VERSION ""

NS_ :

BS_:

BU_: BSM BSM2 CADM CVADAS ECM EPS ORC CANOE EVCU2

BO_ 2654552208 Distance_Point_Map_7: 64 CVADAS
 SG_ FD14_Point_Map_Cruising_Age_63 : 482|6@1+ (1,0) [0|63] ""  CANOE
 SG_ FD14_Point_Map_Cruising_Age_62 : 418|6@1+ (1,0) [0|63] ""  CANOE
 SG_ FD14_Point_Map_Cruising_Age_61 : 354|6@1+ (1,0) [0|63] ""  CANOE
 SG_ FD14_Point_Map_Cruising_Age_60 : 290|6@1+ (1,0) [0|63] ""  CANOE
 SG_ FD14_Point_Map_Cruising_Age_59 : 226|6@1+ (1,0) [0|63] ""  CANOE
 SG_ FD14_Point_Map_Cruising_Age_58 : 162|6@1+ (1,0) [0|63] ""  CANOE
 SG_ FD14_Point_Map_Cruising_Age_57 : 98|6@1+ (1,0) [0|63] ""  CANOE
 SG_ FD14_Point_Map_Cruising_Age_56 : 34|6@1+ (1,0) [0|63] ""  CANOE
 SG_ FD14_Point_Map_Reserved_62 : 440|8@1+ (1,0) [0|255] ""  CANOE
 SG_ FD14_Point_Map_Age_62 : 432|8@1+ (1,0) [0|255] ""  CANOE
 SG_ FD14_Point_Map_Confidence_62 : 424|8@1+ (1,0) [0|255] ""  CANOE
 SG_ FD14_Point_Map_Height_62 : 416|2@1+ (1,0) [0|3] ""  CANOE
 SG_ FD14_Point_Map_Y_62 : 400|16@1- (1,0) [-32768|32767] ""  CANOE
 SG_ FD14_Point_Map_X_62 : 384|16@1- (1,0) [-32768|32767] ""  CANOE
 SG_ FD14_Point_Map_Reserved_61 : 376|8@1+ (1,0) [0|255] ""  CANOE
 SG_ FD14_Point_Map_Age_61 : 368|8@1+ (1,0) [0|255] ""  CANOE
 SG_ FD14_Point_Map_Confidence_61 : 360|8@1+ (1,0) [0|255] ""  CANOE
 SG_ FD14_Point_Map_Height_61 : 352|2@1+ (1,0) [0|3] ""  CANOE
 SG_ FD14_Point_Map_Y_61 : 336|16@1- (1,0) [-32768|32767] ""  CANOE
 SG_ FD14_Point_Map_X_61 : 320|16@1- (1,0) [-32768|32767] ""  CANOE
 SG_ FD14_Point_Map_Reserved_60 : 312|8@1+ (1,0) [0|255] ""  CANOE
 SG_ FD14_Point_Map_Confidence_60 : 296|8@1+ (1,0) [0|255] ""  CANOE
 SG_ FD14_Point_Map_Height_60 : 288|2@1+ (1,0) [0|3] ""  CANOE
 SG_ FD14_Point_Map_Age_60 : 304|8@1+ (1,0) [0|255] ""  CANOE
 SG_ FD14_Point_Map_Y_60 : 272|16@1- (1,0) [-32768|32767] ""  CANOE
 SG_ FD14_Point_Map_X_60 : 256|16@1- (1,0) [-32768|32767] ""  CANOE
 SG_ FD14_Point_Map_Reserved_59 : 248|8@1+ (1,0) [0|255] ""  CANOE
 SG_ FD14_Point_Map_Age_59 : 240|8@1+ (1,0) [0|255] ""  CANOE
 SG_ FD14_Point_Map_Confidence_59 : 232|8@1+ (1,0) [0|255] ""  CANOE
 SG_ FD14_Point_Map_Height_59 : 224|2@1+ (1,0) [0|3] ""  CANOE
 SG_ FD14_Point_Map_Y_59 : 208|16@1- (1,0) [-32768|32767] ""  CANOE
 SG_ FD14_Point_Map_X_59 : 192|16@1- (1,0) [-32768|32767] ""  CANOE
 SG_ FD14_Point_Map_Reserved_58 : 184|8@1+ (1,0) [0|255] ""  CANOE
 SG_ FD14_Point_Map_Age_58 : 176|8@1+ (1,0) [0|255] ""  CANOE
 SG_ FD14_Point_Map_Confidence_58 : 168|8@1+ (1,0) [0|255] ""  CANOE
 SG_ FD14_Point_Map_Height_58 : 160|2@1+ (1,0) [0|3] ""  CANOE
 SG_ FD14_Point_Map_Y_58 : 144|16@1- (1,0) [-32768|32767] ""  CANOE
 SG_ FD14_Point_Map_X_58 : 128|16@1- (1,0) [-32768|32767] ""  CANOE
 SG_ FD14_Point_Map_Reserved_57 : 120|8@1+ (1,0) [0|255] ""  CANOE
 SG_ FD14_Point_Map_Age_57 : 112|8@1+ (1,0) [0|255] ""  CANOE
 SG_ FD14_Point_Map_Confidence_57 : 104|8@1+ (1,0) [0|255] ""  CANOE
 SG_ FD14_Point_Map_Height_57 : 96|2@1+ (1,0) [0|3] ""  CANOE
 SG_ FD14_Point_Map_Y_57 : 80|16@1- (1,0) [-32768|32767] ""  CANOE
 SG_ FD14_Point_Map_X_57 : 64|16@1- (1,0) [-32768|32767] ""  CANOE
 SG_ FD14_Point_Map_Reserved_56 : 56|8@1+ (1,0) [0|255] ""  CANOE
 SG_ FD14_Point_Map_Age_56 : 48|8@1+ (1,0) [0|255] ""  CANOE
 SG_ FD14_Point_Map_Confidence_56 : 40|8@1+ (1,0) [0|255] ""  CANOE
 SG_ FD14_Point_Map_Height_56 : 32|2@1+ (1,0) [0|3] ""  CANOE
 SG_ FD14_Point_Map_Y_56 : 16|16@1- (1,0) [-32768|32767] ""  CANOE
 SG_ FD14_Point_Map_X_56 : 0|16@1- (1,0) [-32768|32767] ""  CANOE
 SG_ FD14_Point_Map_Reserved_63 : 504|8@1+ (1,0) [0|255] ""  CANOE
 SG_ FD14_Point_Map_Age_63 : 496|8@1+ (1,0) [0|255] ""  CANOE
 SG_ FD14_Point_Map_Confidence_63 : 488|8@1+ (1,0) [0|255] ""  CANOE
 SG_ FD14_Point_Map_Height_63 : 480|2@1+ (1,0) [0|3] ""  CANOE
 SG_ FD14_Point_Map_Y_63 : 464|16@1- (1,0) [-32768|32767] ""  CANOE
 SG_ FD14_Point_Map_X_63 : 448|16@1- (1,0) [-32768|32767] ""  CANOE

BO_ 2654552209 Distance_Point_Map_8: 64 CVADAS
 SG_ FD14_Point_Map_Cruising_Age_71 : 498|6@1+ (1,0) [0|63] ""  CANOE
 SG_ FD14_Point_Map_Cruising_Age_70 : 418|6@1+ (1,0) [0|63] ""  CANOE
 SG_ FD14_Point_Map_Cruising_Age_69 : 354|6@1+ (1,0) [0|63] ""  CANOE
 SG_ FD14_Point_Map_Cruising_Age_68 : 290|6@1+ (1,0) [0|63] ""  CANOE
 SG_ FD14_Point_Map_Cruising_Age_67 : 226|6@1+ (1,0) [0|63] ""  CANOE
 SG_ FD14_Point_Map_Cruising_Age_66 : 162|6@1+ (1,0) [0|63] ""  CANOE
 SG_ FD14_Point_Map_Cruising_Age_65 : 98|6@1+ (1,0) [0|63] ""  CANOE
 SG_ FD14_Point_Map_Cruising_Age_64 : 34|6@1+ (1,0) [0|63] ""  CANOE
 SG_ FD14_Point_Map_Reserved_71 : 504|8@1+ (1,0) [0|255] ""  CANOE
 SG_ FD14_Point_Map_Height_71 : 496|2@1+ (1,0) [0|3] ""  CANOE
 SG_ FD14_Point_Map_Age_71 : 488|8@1+ (1,0) [0|255] ""  CANOE
 SG_ FD14_Point_Map_Confidence_71 : 480|8@1+ (1,0) [0|255] ""  CANOE
 SG_ FD14_Point_Map_Y_71 : 464|16@1- (1,0) [-32768|32767] ""  CANOE
 SG_ FD14_Point_Map_X_71 : 448|16@1- (1,0) [-32768|32767] ""  CANOE
 SG_ FD14_Point_Map_Reserved_70 : 440|8@1+ (1,0) [0|255] ""  CANOE
 SG_ FD14_Point_Map_Age_70 : 432|8@1+ (1,0) [0|255] ""  CANOE
 SG_ FD14_Point_Map_Confidence_70 : 424|8@1+ (1,0) [0|255] ""  CANOE
 SG_ FD14_Point_Map_Height_70 : 416|2@1+ (1,0) [0|3] ""  CANOE
 SG_ FD14_Point_Map_Y_70 : 400|16@1- (1,0) [-32768|32767] ""  CANOE
 SG_ FD14_Point_Map_X_70 : 384|16@1- (1,0) [-32768|32767] ""  CANOE
 SG_ FD14_Point_Map_Reserved_69 : 376|8@1+ (1,0) [0|255] ""  CANOE
 SG_ FD14_Point_Map_Age_69 : 368|8@1+ (1,0) [0|255] ""  CANOE
 SG_ FD14_Point_Map_Confidence_69 : 360|8@1+ (1,0) [0|255] ""  CANOE
 SG_ FD14_Point_Map_Height_69 : 352|2@1+ (1,0) [0|3] ""  CANOE
 SG_ FD14_Point_Map_Y_69 : 336|16@1- (1,0) [-32768|32767] ""  CANOE
 SG_ FD14_Point_Map_X_69 : 320|16@1- (1,0) [-32768|32767] ""  CANOE
 SG_ FD14_Point_Map_Reserved_68 : 312|8@1+ (1,0) [0|255] ""  CANOE
 SG_ FD14_Point_Map_Age_68 : 304|8@1+ (1,0) [0|255] ""  CANOE
 SG_ FD14_Point_Map_Confidence_68 : 296|8@1+ (1,0) [0|255] ""  CANOE
 SG_ FD14_Point_Map_Height_68 : 288|2@1+ (1,0) [0|3] ""  CANOE
 SG_ FD14_Point_Map_Y_68 : 272|16@1- (1,0) [-32768|32767] ""  CANOE
 SG_ FD14_Point_Map_X_68 : 256|16@1- (1,0) [-32768|32767] ""  CANOE
 SG_ FD14_Point_Map_Reserved_67 : 248|8@1+ (1,0) [0|255] ""  CANOE
 SG_ FD14_Point_Map_Age_67 : 240|8@1+ (1,0) [0|255] ""  CANOE
 SG_ FD14_Point_Map_Confidence_67 : 232|8@1+ (1,0) [0|255] ""  CANOE
 SG_ FD14_Point_Map_Height_67 : 224|2@1+ (1,0) [0|3] ""  CANOE
 SG_ FD14_Point_Map_Y_67 : 208|16@1- (1,0) [-32768|32767] ""  CANOE
 SG_ FD14_Point_Map_X_67 : 192|16@1- (1,0) [-32768|32767] ""  CANOE
 SG_ FD14_Point_Map_Reserved_66 : 184|8@1+ (1,0) [0|255] ""  CANOE
 SG_ FD14_Point_Map_Age_66 : 176|8@1+ (1,0) [0|255] ""  CANOE
 SG_ FD14_Point_Map_Confidence_66 : 168|8@1+ (1,0) [0|255] ""  CANOE
 SG_ FD14_Point_Map_Height_66 : 160|2@1+ (1,0) [0|3] ""  CANOE
 SG_ FD14_Point_Map_Y_66 : 144|16@1- (1,0) [-32768|32767] ""  CANOE
 SG_ FD14_Point_Map_X_66 : 128|16@1- (1,0) [-32768|32767] ""  CANOE
 SG_ FD14_Point_Map_Reserved_65 : 120|8@1+ (1,0) [0|255] ""  CANOE
 SG_ FD14_Point_Map_Age_65 : 112|8@1+ (1,0) [0|255] ""  CANOE
 SG_ FD14_Point_Map_Confidence_65 : 104|8@1+ (1,0) [0|255] ""  CANOE
 SG_ FD14_Point_Map_Height_65 : 96|2@1+ (1,0) [0|3] ""  CANOE
 SG_ FD14_Point_Map_Y_65 : 80|16@1- (1,0) [-32768|32767] ""  CANOE
 SG_ FD14_Point_Map_X_65 : 64|16@1- (1,0) [-32768|32767] ""  CANOE
 SG_ FD14_Point_Map_Reserved_64 : 56|8@1+ (1,0) [0|255] ""  CANOE
 SG_ FD14_Point_Map_Age_64 : 48|8@1+ (1,0) [0|255] ""  CANOE
 SG_ FD14_Point_Map_Confidence_64 : 40|8@1+ (1,0) [0|255] ""  CANOE
 SG_ FD14_Point_Map_Height_64 : 32|2@1+ (1,0) [0|3] ""  CANOE
 SG_ FD14_Point_Map_Y_64 : 16|16@1- (1,0) [-32768|32767] ""  CANOE
 SG_ FD14_Point_Map_X_64 : 0|16@1- (1,0) [-32768|32767] ""  CANOE

BO_ 2654552210 Distance_Point_Map_9: 64 CVADAS
 SG_ FD14_Point_Map_Cruising_Age_79 : 482|6@1+ (1,0) [0|63] ""  CANOE
 SG_ FD14_Point_Map_Cruising_Age_78 : 418|6@1+ (1,0) [0|63] ""  CANOE
 SG_ FD14_Point_Map_Cruising_Age_77 : 354|6@1+ (1,0) [0|63] ""  CANOE
 SG_ FD14_Point_Map_Cruising_Age_76 : 290|6@1+ (1,0) [0|63] ""  CANOE
 SG_ FD14_Point_Map_Cruising_Age_75 : 226|6@1+ (1,0) [0|63] ""  CANOE
 SG_ FD14_Point_Map_Cruising_Age_74 : 162|6@1+ (1,0) [0|63] ""  CANOE
 SG_ FD14_Point_Map_Cruising_Age_73 : 98|6@1+ (1,0) [0|63] ""  CANOE
 SG_ FD14_Point_Map_Cruising_Age_72 : 34|6@1+ (1,0) [0|63] ""  CANOE
 SG_ FD14_Point_Map_Reserved_79 : 504|8@1+ (1,0) [0|255] ""  CANOE
 SG_ FD14_Point_Map_Age_79 : 496|8@1+ (1,0) [0|255] ""  CANOE
 SG_ FD14_Point_Map_Confidence_79 : 488|8@1+ (1,0) [0|255] ""  CANOE
 SG_ FD14_Point_Map_Height_79 : 480|2@1+ (1,0) [0|3] ""  CANOE
 SG_ FD14_Point_Map_Y_79 : 464|16@1- (1,0) [-32768|32767] ""  CANOE
 SG_ FD14_Point_Map_X_79 : 448|16@1- (1,0) [-32768|32767] ""  CANOE
 SG_ FD14_Point_Map_Reserved_78 : 440|8@1+ (1,0) [0|255] ""  CANOE
 SG_ FD14_Point_Map_Age_78 : 432|8@1+ (1,0) [0|255] ""  CANOE
 SG_ FD14_Point_Map_Confidence_78 : 424|8@1+ (1,0) [0|255] ""  CANOE
 SG_ FD14_Point_Map_Height_78 : 416|2@1+ (1,0) [0|3] ""  CANOE
 SG_ FD14_Point_Map_Y_78 : 400|16@1- (1,0) [-32768|32767] ""  CANOE
 SG_ FD14_Point_Map_X_78 : 384|16@1- (1,0) [-32768|32767] ""  CANOE
 SG_ FD14_Point_Map_Reserved_77 : 376|8@1+ (1,0) [0|255] ""  CANOE
 SG_ FD14_Point_Map_Age_77 : 368|8@1+ (1,0) [0|255] ""  CANOE
 SG_ FD14_Point_Map_Confidence_77 : 360|8@1+ (1,0) [0|255] ""  CANOE
 SG_ FD14_Point_Map_Height_77 : 352|2@1+ (1,0) [0|3] ""  CANOE
 SG_ FD14_Point_Map_Y_77 : 336|16@1- (1,0) [-32768|32767] ""  CANOE
 SG_ FD14_Point_Map_X_77 : 320|16@1- (1,0) [-32768|32767] ""  CANOE
 SG_ FD14_Point_Map_Reserved_76 : 312|8@1+ (1,0) [0|255] ""  CANOE
 SG_ FD14_Point_Map_Age_76 : 304|8@1+ (1,0) [0|255] ""  CANOE
 SG_ FD14_Point_Map_Confidence_76 : 296|8@1+ (1,0) [0|255] ""  CANOE
 SG_ FD14_Point_Map_Height_76 : 288|2@1+ (1,0) [0|3] ""  CANOE
 SG_ FD14_Point_Map_Y_76 : 272|16@1- (1,0) [-32768|32767] ""  CANOE
 SG_ FD14_Point_Map_X_76 : 256|16@1- (1,0) [-32768|32767] ""  CANOE
 SG_ FD14_Point_Map_Reserved_75 : 248|8@1+ (1,0) [0|255] ""  CANOE
 SG_ FD14_Point_Map_Age_75 : 240|8@1+ (1,0) [0|255] ""  CANOE
 SG_ FD14_Point_Map_Confidence_75 : 232|8@1+ (1,0) [0|255] ""  CANOE
 SG_ FD14_Point_Map_Height_75 : 224|2@1+ (1,0) [0|3] ""  CANOE
 SG_ FD14_Point_Map_Y_75 : 208|16@1- (1,0) [-32768|32767] ""  CANOE
 SG_ FD14_Point_Map_X_75 : 192|16@1- (1,0) [-32768|32767] ""  CANOE
 SG_ FD14_Point_Map_Reserved_74 : 184|8@1+ (1,0) [0|255] ""  CANOE
 SG_ FD14_Point_Map_Age_74 : 176|8@1+ (1,0) [0|255] ""  CANOE
 SG_ FD14_Point_Map_Confidence_74 : 168|8@1+ (1,0) [0|255] ""  CANOE
 SG_ FD14_Point_Map_Height_74 : 160|2@1+ (1,0) [0|3] ""  CANOE
 SG_ FD14_Point_Map_Y_74 : 144|16@1- (1,0) [-32768|32767] ""  CANOE
 SG_ FD14_Point_Map_X_74 : 128|16@1- (1,0) [-32768|32767] ""  CANOE
 SG_ FD14_Point_Map_Reserved_73 : 120|8@1+ (1,0) [0|255] ""  CANOE
 SG_ FD14_Point_Map_Age_73 : 112|8@1+ (1,0) [0|255] ""  CANOE
 SG_ FD14_Point_Map_Confidence_73 : 104|8@1+ (1,0) [0|255] ""  CANOE
 SG_ FD14_Point_Map_Height_73 : 96|2@1+ (1,0) [0|3] ""  CANOE
 SG_ FD14_Point_Map_Y_73 : 80|16@1- (1,0) [-32768|32767] ""  CANOE
 SG_ FD14_Point_Map_X_73 : 64|16@1- (1,0) [-32768|32767] ""  CANOE
 SG_ FD14_Point_Map_Reserved_72 : 56|8@1+ (1,0) [0|255] ""  CANOE
 SG_ FD14_Point_Map_Age_72 : 48|8@1+ (1,0) [0|255] ""  CANOE
 SG_ FD14_Point_Map_Confidence_72 : 40|8@1+ (1,0) [0|255] ""  CANOE
 SG_ FD14_Point_Map_Height_72 : 32|2@1+ (1,0) [0|3] ""  CANOE
 SG_ FD14_Point_Map_Y_72 : 16|16@1- (1,0) [-32768|32767] ""  CANOE
 SG_ FD14_Point_Map_X_72 : 0|16@1- (1,0) [-32768|32767] ""  CANOE

BO_ 2654552211 Distance_Point_Map_10: 64 CVADAS
 SG_ FD14_Point_Map_Cruising_Age_87 : 482|6@1+ (1,0) [0|63] ""  CANOE
 SG_ FD14_Point_Map_Cruising_Age_86 : 418|6@1+ (1,0) [0|63] ""  CANOE
 SG_ FD14_Point_Map_Cruising_Age_85 : 354|6@1+ (1,0) [0|63] ""  CANOE
 SG_ FD14_Point_Map_Cruising_Age_84 : 290|6@1+ (1,0) [0|63] ""  CANOE
 SG_ FD14_Point_Map_Cruising_Age_83 : 226|6@1+ (1,0) [0|63] ""  CANOE
 SG_ FD14_Point_Map_Cruising_Age_82 : 162|6@1+ (1,0) [0|63] ""  CANOE
 SG_ FD14_Point_Map_Cruising_Age_81 : 98|6@1+ (1,0) [0|63] ""  CANOE
 SG_ FD14_Point_Map_Cruising_Age_80 : 34|6@1+ (1,0) [0|63] ""  CANOE
 SG_ FD14_Point_Map_Reserved_87 : 504|8@1+ (1,0) [0|255] ""  CANOE
 SG_ FD14_Point_Map_Age_87 : 496|8@1+ (1,0) [0|255] ""  CANOE
 SG_ FD14_Point_Map_Confidence_87 : 488|8@1+ (1,0) [0|255] ""  CANOE
 SG_ FD14_Point_Map_Height_87 : 480|2@1+ (1,0) [0|3] ""  CANOE
 SG_ FD14_Point_Map_Y_87 : 464|16@1- (1,0) [-32768|32767] ""  CANOE
 SG_ FD14_Point_Map_X_87 : 448|16@1- (1,0) [-32768|32767] ""  CANOE
 SG_ FD14_Point_Map_Reserved_86 : 440|8@1+ (1,0) [0|255] ""  CANOE
 SG_ FD14_Point_Map_Age_86 : 432|8@1+ (1,0) [0|255] ""  CANOE
 SG_ FD14_Point_Map_Confidence_86 : 424|8@1+ (1,0) [0|255] ""  CANOE
 SG_ FD14_Point_Map_Height_86 : 416|2@1+ (1,0) [0|3] ""  CANOE
 SG_ FD14_Point_Map_Y_86 : 400|16@1- (1,0) [-32768|32767] ""  CANOE
 SG_ FD14_Point_Map_X_86 : 384|16@1- (1,0) [-32768|32767] ""  CANOE
 SG_ FD14_Point_Map_Reserved_85 : 376|8@1+ (1,0) [0|255] ""  CANOE
 SG_ FD14_Point_Map_Age_85 : 368|8@1+ (1,0) [0|255] ""  CANOE
 SG_ FD14_Point_Map_Confidence_85 : 360|8@1+ (1,0) [0|255] ""  CANOE
 SG_ FD14_Point_Map_Height_85 : 352|2@1+ (1,0) [0|3] ""  CANOE
 SG_ FD14_Point_Map_Y_85 : 336|16@1- (1,0) [-32768|32767] ""  CANOE
 SG_ FD14_Point_Map_X_85 : 320|16@1- (1,0) [-32768|32767] ""  CANOE
 SG_ FD14_Point_Map_Reserved_84 : 312|8@1+ (1,0) [0|255] ""  CANOE
 SG_ FD14_Point_Map_Age_84 : 304|8@1+ (1,0) [0|255] ""  CANOE
 SG_ FD14_Point_Map_Confidence_84 : 296|8@1+ (1,0) [0|255] ""  CANOE
 SG_ FD14_Point_Map_Height_84 : 288|2@1+ (1,0) [0|3] ""  CANOE
 SG_ FD14_Point_Map_Y_84 : 272|16@1- (1,0) [-32768|32767] ""  CANOE
 SG_ FD14_Point_Map_X_84 : 256|16@1- (1,0) [-32768|32767] ""  CANOE
 SG_ FD14_Point_Map_Reserved_83 : 248|8@1+ (1,0) [0|255] ""  CANOE
 SG_ FD14_Point_Map_Age_83 : 240|8@1+ (1,0) [0|255] ""  CANOE
 SG_ FD14_Point_Map_Confidence_83 : 232|8@1+ (1,0) [0|255] ""  CANOE
 SG_ FD14_Point_Map_Height_83 : 224|2@1+ (1,0) [0|3] ""  CANOE
 SG_ FD14_Point_Map_Y_83 : 208|16@1- (1,0) [-32768|32767] ""  CANOE
 SG_ FD14_Point_Map_X_83 : 192|16@1- (1,0) [-32768|32767] ""  CANOE
 SG_ FD14_Point_Map_Reserved_82 : 184|8@1+ (1,0) [0|255] ""  CANOE
 SG_ FD14_Point_Map_Age_82 : 176|8@1+ (1,0) [0|255] ""  CANOE
 SG_ FD14_Point_Map_Confidence_82 : 168|8@1+ (1,0) [0|255] ""  CANOE
 SG_ FD14_Point_Map_Height_82 : 160|2@1+ (1,0) [0|3] ""  CANOE
 SG_ FD14_Point_Map_Y_82 : 144|16@1- (1,0) [-32768|32767] ""  CANOE
 SG_ FD14_Point_Map_X_82 : 128|16@1- (1,0) [-32768|32767] ""  CANOE
 SG_ FD14_Point_Map_Reserved_81 : 120|8@1+ (1,0) [0|255] ""  CANOE
 SG_ FD14_Point_Map_Age_81 : 112|8@1+ (1,0) [0|255] ""  CANOE
 SG_ FD14_Point_Map_Confidence_81 : 104|8@1+ (1,0) [0|255] ""  CANOE
 SG_ FD14_Point_Map_Height_81 : 96|2@1+ (1,0) [0|3] ""  CANOE
 SG_ FD14_Point_Map_Y_81 : 80|16@1- (1,0) [-32768|32767] ""  CANOE
 SG_ FD14_Point_Map_X_81 : 64|16@1- (1,0) [-32768|32767] ""  CANOE
 SG_ FD14_Point_Map_Reserved_80 : 56|8@1+ (1,0) [0|255] ""  CANOE
 SG_ FD14_Point_Map_Age_80 : 48|8@1+ (1,0) [0|255] ""  CANOE
 SG_ FD14_Point_Map_Confidence_80 : 40|8@1+ (1,0) [0|255] ""  CANOE
 SG_ FD14_Point_Map_Height_80 : 32|2@1+ (1,0) [0|3] ""  CANOE
 SG_ FD14_Point_Map_Y_80 : 16|16@1- (1,0) [-32768|32767] ""  CANOE
 SG_ FD14_Point_Map_X_80 : 0|16@1- (1,0) [-32768|32767] ""  CANOE

BO_ 2654552212 Distance_Point_Map_11: 64 CVADAS
 SG_ FD14_Point_Map_Cruising_Age_95 : 482|6@1+ (1,0) [0|63] ""  CANOE
 SG_ FD14_Point_Map_Cruising_Age_94 : 418|6@1+ (1,0) [0|63] ""  CANOE
 SG_ FD14_Point_Map_Cruising_Age_93 : 354|6@1+ (1,0) [0|63] ""  CANOE
 SG_ FD14_Point_Map_Cruising_Age_92 : 290|6@1+ (1,0) [0|63] ""  CANOE
 SG_ FD14_Point_Map_Cruising_Age_91 : 226|6@1+ (1,0) [0|63] ""  CANOE
 SG_ FD14_Point_Map_Cruising_Age_90 : 162|6@1+ (1,0) [0|63] ""  CANOE
 SG_ FD14_Point_Map_Cruising_Age_89 : 98|6@1+ (1,0) [0|63] ""  CANOE
 SG_ FD14_Point_Map_Cruising_Age_88 : 34|6@1+ (1,0) [0|63] ""  CANOE
 SG_ FD14_Point_Map_Reserved_94 : 440|8@1+ (1,0) [0|255] ""  CANOE
 SG_ FD14_Point_Map_Age_94 : 432|8@1+ (1,0) [0|255] ""  CANOE
 SG_ FD14_Point_Map_Confidence_94 : 424|8@1+ (1,0) [0|255] ""  CANOE
 SG_ FD14_Point_Map_Height_94 : 416|2@1+ (1,0) [0|3] ""  CANOE
 SG_ FD14_Point_Map_Y_94 : 400|16@1- (1,0) [-32768|32767] ""  CANOE
 SG_ FD14_Point_Map_X_94 : 384|16@1- (1,0) [-32768|32767] ""  CANOE
 SG_ FD14_Point_Map_Reserved_93 : 376|8@1+ (1,0) [0|255] ""  CANOE
 SG_ FD14_Point_Map_Age_93 : 368|8@1+ (1,0) [0|255] ""  CANOE
 SG_ FD14_Point_Map_Confidence_93 : 360|8@1+ (1,0) [0|255] ""  CANOE
 SG_ FD14_Point_Map_Height_93 : 352|2@1+ (1,0) [0|3] ""  CANOE
 SG_ FD14_Point_Map_Y_93 : 336|16@1- (1,0) [-32768|32767] ""  CANOE
 SG_ FD14_Point_Map_X_93 : 320|16@1- (1,0) [-32768|32767] ""  CANOE
 SG_ FD14_Point_Map_Reserved_92 : 312|8@1+ (1,0) [0|255] ""  CANOE
 SG_ FD14_Point_Map_Age_92 : 304|8@1+ (1,0) [0|255] ""  CANOE
 SG_ FD14_Point_Map_Confidence_92 : 296|8@1+ (1,0) [0|255] ""  CANOE
 SG_ FD14_Point_Map_Height_92 : 288|2@1+ (1,0) [0|3] ""  CANOE
 SG_ FD14_Point_Map_Y_92 : 272|16@1- (1,0) [-32768|32767] ""  CANOE
 SG_ FD14_Point_Map_X_92 : 256|16@1- (1,0) [-32768|32767] ""  CANOE
 SG_ FD14_Point_Map_Reserved_91 : 248|8@1+ (1,0) [0|255] ""  CANOE
 SG_ FD14_Point_Map_Age_91 : 240|8@1+ (1,0) [0|255] ""  CANOE
 SG_ FD14_Point_Map_Confidence_91 : 232|8@1+ (1,0) [0|255] ""  CANOE
 SG_ FD14_Point_Map_Height_91 : 224|2@1+ (1,0) [0|3] ""  CANOE
 SG_ FD14_Point_Map_Y_91 : 208|16@1- (1,0) [-32768|32767] ""  CANOE
 SG_ FD14_Point_Map_X_91 : 192|16@1- (1,0) [-32768|32767] ""  CANOE
 SG_ FD14_Point_Map_Reserved_90 : 184|8@1+ (1,0) [0|255] ""  CANOE
 SG_ FD14_Point_Map_Age_90 : 176|8@1+ (1,0) [0|255] ""  CANOE
 SG_ FD14_Point_Map_Confidence_90 : 168|8@1+ (1,0) [0|255] ""  CANOE
 SG_ FD14_Point_Map_Height_90 : 160|2@1+ (1,0) [0|3] ""  CANOE
 SG_ FD14_Point_Map_Y_90 : 144|16@1- (1,0) [-32768|32767] ""  CANOE
 SG_ FD14_Point_Map_X_90 : 128|16@1- (1,0) [-32768|32767] ""  CANOE
 SG_ FD14_Point_Map_Reserved_89 : 120|8@1+ (1,0) [0|255] ""  CANOE
 SG_ FD14_Point_Map_Age_89 : 112|8@1+ (1,0) [0|255] ""  CANOE
 SG_ FD14_Point_Map_Confidence_89 : 104|8@1+ (1,0) [0|255] ""  CANOE
 SG_ FD14_Point_Map_Height_89 : 96|2@1+ (1,0) [0|3] ""  CANOE
 SG_ FD14_Point_Map_Y_89 : 80|16@1- (1,0) [-32768|32767] ""  CANOE
 SG_ FD14_Point_Map_X_89 : 64|16@1- (1,0) [-32768|32767] ""  CANOE
 SG_ FD14_Point_Map_Reserved_88 : 56|8@1+ (1,0) [0|255] ""  CANOE
 SG_ FD14_Point_Map_Age_88 : 48|8@1+ (1,0) [0|255] ""  CANOE
 SG_ FD14_Point_Map_Confidence_88 : 40|8@1+ (1,0) [0|255] ""  CANOE
 SG_ FD14_Point_Map_Height_88 : 32|2@1+ (1,0) [0|3] ""  CANOE
 SG_ FD14_Point_Map_Y_88 : 16|16@1- (1,0) [-32768|32767] ""  CANOE
 SG_ FD14_Point_Map_X_88 : 0|16@1- (1,0) [-32768|32767] ""  CANOE
 SG_ FD14_Point_Map_Reserved_95 : 504|8@1+ (1,0) [0|255] ""  CANOE
 SG_ FD14_Point_Map_Age_95 : 496|8@1+ (1,0) [0|255] ""  CANOE
 SG_ FD14_Point_Map_Confidence_95 : 488|8@1+ (1,0) [0|255] ""  CANOE
 SG_ FD14_Point_Map_Y_95 : 464|16@1- (1,0) [-32768|32767] ""  CANOE
 SG_ FD14_Point_Map_Height_95 : 480|2@1+ (1,0) [0|3] ""  CANOE
 SG_ FD14_Point_Map_X_95 : 448|16@1- (1,0) [-32768|32767] ""  CANOE

BO_ 2654552213 Firing_Mode: 5 CVADAS
 SG_ FD14_FiringMode_TimeStamp : 8|32@1+ (1,0) [0|0] "ms"  CANOE
 SG_ FD14_Firing_Mode_Seq : 0|8@1+ (1,0) [0|0] ""  CANOE

BO_ 2654552214 Firing_Sensors: 6 CVADAS
 SG_ FD14_FiringSnr_TimeStamp : 16|32@1+ (1,0) [0|0] "ms"  CANOE
 SG_ FD14_Firing_Sensor : 0|16@1+ (1,0) [0|0] ""  CANOE

BO_ 2654552215 Firing_Sequence: 8 CVADAS
 SG_ FD14_Current_Firing_Sequence : 0|2@1+ (1,0) [0|3] ""  CANOE

BO_ 2654552193 FODDebug: 64 CVADAS
 SG_ FD14_cntrCvpamFdData1_u16 : 160|16@1+ (1,0) [0|65535] ""  CANOE
 SG_ FD14_crcCvpamFdData1_u8 : 152|8@1+ (1,0) [0|255] ""  CANOE
 SG_ FD14_msgcntrCvpamFdData1_u8 : 144|8@1+ (1,0) [0|255] ""  CANOE
 SG_ FD14_macCvpamFdData1_u64 : 80|64@1+ (1,0) [0|1.84467440737096E+019] ""  CANOE
 SG_ FD14_obj_Pos_Longi : 48|32@1- (1,0) [-3.4E+038|3.4E+038] ""  CANOE
 SG_ FD14_obj_Pos_Lat : 16|32@1- (1,0) [-3.4E+038|3.4E+038] ""  CANOE
 SG_ FD14_objConf_e : 8|2@1+ (1,0) [0|3] ""  CANOE
 SG_ FD14_FrontSensorDetHealth_e : 0|2@1+ (1,0) [0|3] ""  CANOE

BO_ 2654814256 Log_PackedDiagFlagData2_v: 64 CVADAS
 SG_ FD14_Log_PackedDiagFlagData2_v : 0|8@1+ (1,0) [0|0] ""  CANOE

BO_ 2654814248 Log_PackedDiagFlagData1_v: 64 CVADAS
 SG_ FD14_Log_PackedDiagFlagData1_v : 0|8@1+ (1,0) [0|0] ""  CANOE

BO_ 2654814249 Log_PackedNoiseMeasData: 64 CVADAS
 SG_ FD14_Log_PackedNoiseMeasData : 0|8@1+ (1,0) [0|0] ""  CANOE

BO_ 2654552336 FPADebugInfo1: 64 CVADAS
 SG_ FD14_stFPAInfoToVCLockedSlotRear : 176|32@1- (1,0) [0|640] ""  CANOE
 SG_ FD14_stFPAInfoToVCLockedSlotFrnt : 144|32@1- (1,0) [0|640] ""  CANOE
 SG_ FD14_stFPAInfoToVCLockedSlo_0000 : 112|32@1- (1,0) [0|400] ""  CANOE
 SG_ FD14_stFPAInfoToVCLockedSlo_0001 : 72|32@1- (1,0) [0|400] ""  CANOE
 SG_ FD14_stFPAInfoToVCLockedSlotType : 64|8@1+ (1,0) [0|3] ""  CANOE
 SG_ FD14_m_FPAToNVMParkInStyle : 56|8@1+ (1,0) [0|2] ""  CANOE
 SG_ FD14_stFPAInfoToVCLockedSlotSide : 48|8@1+ (1,0) [0|2] ""  CANOE
 SG_ FD14_m_FpaInfoToVCParkOutStyle : 40|8@1+ (1,0) [0|2] ""  CANOE
 SG_ FD14_stFPAInfoToVCLockedSlotID : 32|8@1+ (1,0) [0|6] ""  CANOE
 SG_ FD14_m_FPAInfoToUSSOMSlotID : 24|8@1+ (1,0) [0|6] ""  CANOE
 SG_ FD14_m_FPAInfoToPLDSlotID : 10|8@1+ (1,0) [0|6] ""  CANOE
 SG_ FD14_stFPAInfoToHMISlot6Valid : 9|1@1+ (1,0) [0|1] ""  CANOE
 SG_ FD14_stFPAInfoToHMISlot5Valid : 8|1@1+ (1,0) [0|1] ""  CANOE
 SG_ FD14_stFPAInfoToHMISlot4Valid : 7|1@1+ (1,0) [0|1] ""  CANOE
 SG_ FD14_stFPAInfoToHMISlot3Valid : 6|1@1+ (1,0) [0|1] ""  CANOE
 SG_ FD14_stFPAInfoToHMISlot2Valid : 5|1@1+ (1,0) [0|1] ""  CANOE
 SG_ FD14_stFPAInfoToHMISlot1Valid : 4|1@1+ (1,0) [0|1] ""  CANOE
 SG_ FD14_m_FPAToNVMWriteNVMParam_b : 3|1@1+ (1,0) [0|1] ""  CANOE
 SG_ FD14_m_FPAToNVMReadNVMParam_b : 2|1@1+ (1,0) [0|1] ""  CANOE
 SG_ FD14_stFPAInfoToVCLockedSlotVali : 1|1@1+ (1,0) [0|1] ""  CANOE
 SG_ FD14_AutoParkInitializedStatus_b : 0|1@1+ (1,0) [0|1] ""  CANOE

BO_ 2654552145 HMI_Curr_Displayed_Overlays: 16 CVADAS
 SG_ FD14_Frameset1AndTopFrontText_b : 111|1@1+ (1,0) [0|1] ""  CANOE
 SG_ FD14_Frameset1AndTopRearText_b : 110|1@1+ (1,0) [0|1] ""  CANOE
 SG_ FD14_Frameset2AndFrontCrossText_ : 109|1@1+ (1,0) [0|1] ""  CANOE
 SG_ FD14_Frameset2AndRearCrossText_b : 108|1@1+ (1,0) [0|1] ""  CANOE
 SG_ FD14_MoreCamsIconFullScreenNoSel : 107|1@1+ (1,0) [0|1] ""  CANOE
 SG_ FD14_TopRearButtonNoSelect_b : 106|1@1+ (1,0) [0|1] ""  CANOE
 SG_ FD14_TopRearButtonSelect_b : 105|1@1+ (1,0) [0|1] ""  CANOE
 SG_ FD14_RearCrossButtonNoSelect_b : 104|1@1+ (1,0) [0|1] ""  CANOE
 SG_ FD14_RearCrossButtonSelect_b : 103|1@1+ (1,0) [0|1] ""  CANOE
 SG_ FD14_FrontCrossButtonNoSelect_b : 102|1@1+ (1,0) [0|1] ""  CANOE
 SG_ FD14_FrontCrossButtonSelect_b : 101|1@1+ (1,0) [0|1] ""  CANOE
 SG_ FD14_TopFrontButtonSelect_b : 100|1@1+ (1,0) [0|1] ""  CANOE
 SG_ FD14_TopFrontButtonNoSelect_b : 99|1@1+ (1,0) [0|1] ""  CANOE
 SG_ FD14_BackupRearCamButtonSelect_b : 98|1@1+ (1,0) [0|1] ""  CANOE
 SG_ FD14_BackupRearCamButtonNoSelect : 97|1@1+ (1,0) [0|1] ""  CANOE
 SG_ FD14_FrontFaceCamButtonSelect_b : 96|1@1+ (1,0) [0|1] ""  CANOE
 SG_ FD14_FrontFaceCamButtonNoSelect_ : 95|1@1+ (1,0) [0|1] ""  CANOE
 SG_ FD14_FrontTireTracks_b : 94|1@1+ (1,0) [0|1] ""  CANOE
 SG_ FD14_AuxCamButton1Select_b : 93|1@1+ (1,0) [0|1] ""  CANOE
 SG_ FD14_AuxCamButton1NoSelect_b : 92|1@1+ (1,0) [0|1] ""  CANOE
 SG_ FD14_AuxCamButton2Select_b : 91|1@1+ (1,0) [0|1] ""  CANOE
 SG_ FD14_AuxCamButton2NoSelect_b : 90|1@1+ (1,0) [0|1] ""  CANOE
 SG_ FD14_MoreCamsButton1Select_b : 89|1@1+ (1,0) [0|1] ""  CANOE
 SG_ FD14_MoreCamsButton1NoSelect_b : 88|1@1+ (1,0) [0|1] ""  CANOE
 SG_ FD14_MoreCamsButton2Select_b : 87|1@1+ (1,0) [0|1] ""  CANOE
 SG_ FD14_MoreCamsButton2NoSelect_b : 86|1@1+ (1,0) [0|1] ""  CANOE
 SG_ FD14_RearViewDynamics_b : 85|1@1+ (1,0) [0|1] ""  CANOE
 SG_ FD14_TopViewRearDynamics_b : 84|1@1+ (1,0) [0|1] ""  CANOE
 SG_ FD14_FrontViewDynamics_b : 83|1@1+ (1,0) [0|1] ""  CANOE
 SG_ FD14_TopViewFrontDynamics_b : 82|1@1+ (1,0) [0|1] ""  CANOE
 SG_ FD14_XIcon_b : 81|1@1+ (1,0) [0|1] ""  CANOE
 SG_ FD14_ZoomButtonDisable_b : 80|1@1+ (1,0) [0|1] ""  CANOE
 SG_ FD14_ZoomMinusIcon_b : 79|1@1+ (1,0) [0|1] ""  CANOE
 SG_ FD14_ZoomPlusIcon_b : 78|1@1+ (1,0) [0|1] ""  CANOE
 SG_ FD14_LeftDoorFrontOpen_Icon_b : 77|1@1+ (1,0) [0|1] ""  CANOE
 SG_ FD14_LeftDoorRearOpen_Icon_b : 76|1@1+ (1,0) [0|1] ""  CANOE
 SG_ FD14_RightDoorFrontOpen_Icon_b : 75|1@1+ (1,0) [0|1] ""  CANOE
 SG_ FD14_RightDoorRearOpen_Icon_b : 74|1@1+ (1,0) [0|1] ""  CANOE
 SG_ FD14_BackDoorOpen_Icon_b : 73|1@1+ (1,0) [0|1] ""  CANOE
 SG_ FD14_FrontCam_NA_b : 72|1@1+ (1,0) [0|1] ""  CANOE
 SG_ FD14_LeftCam_NA_b : 71|1@1+ (1,0) [0|1] ""  CANOE
 SG_ FD14_BackCam_NA_b : 70|1@1+ (1,0) [0|1] ""  CANOE
 SG_ FD14_RightCam_NA_b : 69|1@1+ (1,0) [0|1] ""  CANOE
 SG_ FD14_TopViewBlack_b : 68|1@1+ (1,0) [0|1] ""  CANOE
 SG_ FD14_LeftDoorFrontClose_Icon_b : 67|1@1+ (1,0) [0|1] ""  CANOE
 SG_ FD14_LeftDoorRearClose_Icon_b : 66|1@1+ (1,0) [0|1] ""  CANOE
 SG_ FD14_RightDoorFrontClose_Icon_b : 65|1@1+ (1,0) [0|1] ""  CANOE
 SG_ FD14_RightDoorRearClose_Icon_b : 64|1@1+ (1,0) [0|1] ""  CANOE
 SG_ FD14_Reserved13_b : 63|1@1+ (1,0) [0|1] ""  CANOE
 SG_ FD14_PDC_RearCenter_Yellow_b : 62|1@1+ (1,0) [0|1] ""  CANOE
 SG_ FD14_PDC_RearCenter_Red_b : 61|1@1+ (1,0) [0|1] ""  CANOE
 SG_ FD14_Reserved12_b : 60|1@1+ (1,0) [0|1] ""  CANOE
 SG_ FD14_PDC_RearRight_Yellow_b : 59|1@1+ (1,0) [0|1] ""  CANOE
 SG_ FD14_PDC_RearRight_Red_b : 58|1@1+ (1,0) [0|1] ""  CANOE
 SG_ FD14_Reserved11_b : 57|1@1+ (1,0) [0|1] ""  CANOE
 SG_ FD14_PDC_FrontLeft_Yellow_b : 56|1@1+ (1,0) [0|1] ""  CANOE
 SG_ FD14_PDC_FrontLeft_Red_b : 55|1@1+ (1,0) [0|1] ""  CANOE
 SG_ FD14_Reserved10_b : 54|1@1+ (1,0) [0|1] ""  CANOE
 SG_ FD14_PDC_FrontCenter_Yellow_b : 53|1@1+ (1,0) [0|1] ""  CANOE
 SG_ FD14_PDC_FrontCenter_Red_b : 52|1@1+ (1,0) [0|1] ""  CANOE
 SG_ FD14_Reserved09_b : 51|1@1+ (1,0) [0|1] ""  CANOE
 SG_ FD14_PDC_FrontRight_Yellow_b : 50|1@1+ (1,0) [0|1] ""  CANOE
 SG_ FD14_PDC_FrontRight_Red_b : 49|1@1+ (1,0) [0|1] ""  CANOE
 SG_ FD14_Reserved08_b : 48|1@1+ (1,0) [0|1] ""  CANOE
 SG_ FD14_PDC_RearLeft_Yellow_b : 47|1@1+ (1,0) [0|1] ""  CANOE
 SG_ FD14_PDC_RearLeft_Red_b : 46|1@1+ (1,0) [0|1] ""  CANOE
 SG_ FD14_SrvLayout_b : 45|1@1+ (1,0) [0|1] ""  CANOE
 SG_ FD14_SrvStAngIndOk_b : 44|1@1+ (1,0) [0|1] ""  CANOE
 SG_ FD14_SrvStAngIndNok_b : 43|1@1+ (1,0) [0|1] ""  CANOE
 SG_ FD14_SrvSpOmIndOk_b : 42|1@1+ (1,0) [0|1] ""  CANOE
 SG_ FD14_SrvSpOmIndNok_b : 41|1@1+ (1,0) [0|1] ""  CANOE
 SG_ FD14_SrvChkIndRun_b : 40|1@1+ (1,0) [0|1] ""  CANOE
 SG_ FD14_SrvChkIndOk_b : 39|1@1+ (1,0) [0|1] ""  CANOE
 SG_ FD14_SrvChkIndNok_b : 38|1@1+ (1,0) [0|1] ""  CANOE
 SG_ FD14_SrvChkIndCondNok_b : 37|1@1+ (1,0) [0|1] ""  CANOE
 SG_ FD14_SrvCamIndFrOk_b : 36|1@1+ (1,0) [0|1] ""  CANOE
 SG_ FD14_SrvCamIndFrNok_b : 35|1@1+ (1,0) [0|1] ""  CANOE
 SG_ FD14_SrvCamIndFrPend_b : 34|1@1+ (1,0) [0|1] ""  CANOE
 SG_ FD14_SrvCamIndFrNone_b : 33|1@1+ (1,0) [0|1] ""  CANOE
 SG_ FD14_SrvCamIndLeOk_b : 32|1@1+ (1,0) [0|1] ""  CANOE
 SG_ FD14_SrvCamIndLeNok_b : 31|1@1+ (1,0) [0|1] ""  CANOE
 SG_ FD14_SrvCamIndLePend_b : 30|1@1+ (1,0) [0|1] ""  CANOE
 SG_ FD14_SrvCamIndLeNone_b : 29|1@1+ (1,0) [0|1] ""  CANOE
 SG_ FD14_SrvCamIndBaOk_b : 28|1@1+ (1,0) [0|1] ""  CANOE
 SG_ FD14_SrvCamIndBaNok_b : 27|1@1+ (1,0) [0|1] ""  CANOE
 SG_ FD14_SrvCamIndBaPend_b : 26|1@1+ (1,0) [0|1] ""  CANOE
 SG_ FD14_SrvCamIndBaNone_b : 25|1@1+ (1,0) [0|1] ""  CANOE
 SG_ FD14_SrvCamIndRiOk_b : 24|1@1+ (1,0) [0|1] ""  CANOE
 SG_ FD14_SrvCamIndRiNok_b : 23|1@1+ (1,0) [0|1] ""  CANOE
 SG_ FD14_SrvCamIndRiPend_b : 22|1@1+ (1,0) [0|1] ""  CANOE
 SG_ FD14_SrvCamIndRiNone_b : 21|1@1+ (1,0) [0|1] ""  CANOE
 SG_ FD14_SrvPrgBar0Per_b : 20|1@1+ (1,0) [0|1] ""  CANOE
 SG_ FD14_SrvPrgBar20Per_b : 19|1@1+ (1,0) [0|1] ""  CANOE
 SG_ FD14_SrvPrgBar40Per_b : 18|1@1+ (1,0) [0|1] ""  CANOE
 SG_ FD14_SrvPrgBar60Per_b : 17|1@1+ (1,0) [0|1] ""  CANOE
 SG_ FD14_SrvPrgBar80Per_b : 16|1@1+ (1,0) [0|1] ""  CANOE
 SG_ FD14_SrvPrgBar100Per_b : 15|1@1+ (1,0) [0|1] ""  CANOE
 SG_ FD14_TrscOvl : 14|1@1+ (1,0) [0|1] ""  CANOE
 SG_ FD14_TrscJackKnifeOrange : 13|1@1+ (1,0) [0|1] ""  CANOE
 SG_ FD14_TrscJackKnifeRed : 12|1@1+ (1,0) [0|1] ""  CANOE
 SG_ FD14_TrscTrailerRed : 11|1@1+ (1,0) [0|1] ""  CANOE
 SG_ FD14_THATriangleOverlay : 10|1@1+ (1,0) [0|1] ""  CANOE
 SG_ FD14_THACouplerBulletIcon : 9|1@1+ (1,0) [0|1] ""  CANOE
 SG_ FD14_THAButtonGrey : 8|1@1+ (1,0) [0|1] ""  CANOE
 SG_ FD14_THAButtonSelectable : 7|1@1+ (1,0) [0|1] ""  CANOE
 SG_ FD14_THAConfirmButton : 6|1@1+ (1,0) [0|1] ""  CANOE
 SG_ FD14_THAStartButton : 5|1@1+ (1,0) [0|1] ""  CANOE
 SG_ FD14_THAProgressBar : 4|1@1+ (1,0) [0|1] ""  CANOE
 SG_ FD14_Reserved3_b : 3|1@1+ (1,0) [0|1] ""  CANOE
 SG_ FD14_Reserved2_b : 2|1@1+ (1,0) [0|1] ""  CANOE
 SG_ FD14_Reserved1_b : 1|1@1+ (1,0) [0|1] ""  CANOE
 SG_ FD14_Reserved0_b : 0|1@1+ (1,0) [0|1] ""  CANOE

BO_ 2654552147 HMI_Curr_Displayed_ProxiConfig: 16 CVADAS
 SG_ FD14_MePRX_b_TRSCPresence : 70|1@1+ (1,0) [0|1] ""  CANOE
 SG_ FD14_MePRX_b_TRGPresence : 69|1@1+ (1,0) [0|1] ""  CANOE
 SG_ FD14_MePRX_b_CanNode27 : 68|1@1+ (1,0) [0|1] ""  CANOE
 SG_ FD14_MePRX_b_CANNode95 : 67|1@1+ (1,0) [0|1] ""  CANOE
 SG_ FD14_MePRX_b_AuxTrlrCam : 66|1@1+ (1,0) [0|1] ""  CANOE
 SG_ FD14_MePRX_b_FrwFacingCam : 65|1@1+ (1,0) [0|1] ""  CANOE
 SG_ FD14_MePRX_b_SurroundViewCamera : 64|1@1+ (1,0) [0|1] ""  CANOE
 SG_ FD14_MePRX_e_AutonomyLvl : 56|8@1+ (1,0) [0|255] ""  CANOE
 SG_ FD14_MePRX_e_PAMTunSet : 48|8@1+ (1,0) [0|255] ""  CANOE
 SG_ FD14_MePRX_e_MirrorType : 40|8@1+ (1,0) [0|255] ""  CANOE
 SG_ FD14_MePRX_e_RadDispType : 32|8@1+ (1,0) [0|255] ""  CANOE
 SG_ FD14_MePRX_e_SteerRatRackPinionT : 24|8@1+ (1,0) [0|255] ""  CANOE
 SG_ FD14_MePRX_e_Wheelbase : 16|8@1+ (1,0) [0|255] ""  CANOE
 SG_ FD14_MePRX_e_VehLineCfg : 8|8@1+ (1,0) [0|255] ""  CANOE
 SG_ FD14_MePRX_e_VariantID : 0|8@1+ (1,0) [0|255] ""  CANOE

BO_ 2654552144 HMI_Curr_Requested_Overlays: 16 CVADAS
 SG_ FD14_Frameset1AndTopFrontText_b : 111|1@1+ (1,0) [0|1] ""  CANOE
 SG_ FD14_Frameset1AndTopRearText_b : 110|1@1+ (1,0) [0|1] ""  CANOE
 SG_ FD14_Frameset2AndFrontCross_0000 : 109|1@1+ (1,0) [0|1] ""  CANOE
 SG_ FD14_Frameset2AndRearCrossText_b : 108|1@1+ (1,0) [0|1] ""  CANOE
 SG_ FD14_MoreCamsIconFullScreen_0000 : 107|1@1+ (1,0) [0|1] ""  CANOE
 SG_ FD14_TopRearButtonNoSelect_b : 106|1@1+ (1,0) [0|1] ""  CANOE
 SG_ FD14_TopRearButtonSelect_b : 105|1@1+ (1,0) [0|1] ""  CANOE
 SG_ FD14_RearCrossButtonNoSelect_b : 104|1@1+ (1,0) [0|1] ""  CANOE
 SG_ FD14_RearCrossButtonSelect_b : 103|1@1+ (1,0) [0|1] ""  CANOE
 SG_ FD14_FrontCrossButtonNoSelect_b : 102|1@1+ (1,0) [0|1] ""  CANOE
 SG_ FD14_FrontCrossButtonSelect_b : 101|1@1+ (1,0) [0|1] ""  CANOE
 SG_ FD14_TopFrontButtonSelect_b : 100|1@1+ (1,0) [0|1] ""  CANOE
 SG_ FD14_TopFrontButtonNoSelect_b : 99|1@1+ (1,0) [0|1] ""  CANOE
 SG_ FD14_BackupRearCamButtonSelect_b : 98|1@1+ (1,0) [0|1] ""  CANOE
 SG_ FD14_BackupRearCamButtonNoS_0000 : 97|1@1+ (1,0) [0|1] ""  CANOE
 SG_ FD14_FrontFaceCamButtonSelect_b : 96|1@1+ (1,0) [0|1] ""  CANOE
 SG_ FD14_FrontFaceCamButtonNoSe_0000 : 95|1@1+ (1,0) [0|1] ""  CANOE
 SG_ FD14_FrontTireTracks_b : 94|1@1+ (1,0) [0|1] ""  CANOE
 SG_ FD14_AuxCamButton1Select_b : 93|1@1+ (1,0) [0|1] ""  CANOE
 SG_ FD14_AuxCamButton1NoSelect_b : 92|1@1+ (1,0) [0|1] ""  CANOE
 SG_ FD14_AuxCamButton2Select_b : 91|1@1+ (1,0) [0|1] ""  CANOE
 SG_ FD14_AuxCamButton2NoSelect_b : 90|1@1+ (1,0) [0|1] ""  CANOE
 SG_ FD14_MoreCamsButton1Select_b : 89|1@1+ (1,0) [0|1] ""  CANOE
 SG_ FD14_MoreCamsButton1NoSelect_b : 88|1@1+ (1,0) [0|1] ""  CANOE
 SG_ FD14_MoreCamsButton2Select_b : 87|1@1+ (1,0) [0|1] ""  CANOE
 SG_ FD14_MoreCamsButton2NoSelect_b : 86|1@1+ (1,0) [0|1] ""  CANOE
 SG_ FD14_RearViewDynamics_b : 85|1@1+ (1,0) [0|1] ""  CANOE
 SG_ FD14_TopViewRearDynamics_b : 84|1@1+ (1,0) [0|1] ""  CANOE
 SG_ FD14_FrontViewDynamics_b : 83|1@1+ (1,0) [0|1] ""  CANOE
 SG_ FD14_TopViewFrontDynamics_b : 82|1@1+ (1,0) [0|1] ""  CANOE
 SG_ FD14_XIcon_b : 81|1@1+ (1,0) [0|1] ""  CANOE
 SG_ FD14_ZoomButtonDisable_b : 80|1@1+ (1,0) [0|1] ""  CANOE
 SG_ FD14_ZoomMinusIcon_b : 79|1@1+ (1,0) [0|1] ""  CANOE
 SG_ FD14_ZoomPlusIcon_b : 78|1@1+ (1,0) [0|1] ""  CANOE
 SG_ FD14_LeftDoorFrontOpen_Icon_b : 77|1@1+ (1,0) [0|1] ""  CANOE
 SG_ FD14_LeftDoorRearOpen_Icon_b : 76|1@1+ (1,0) [0|1] ""  CANOE
 SG_ FD14_RightDoorFrontOpen_Icon_b : 75|1@1+ (1,0) [0|1] ""  CANOE
 SG_ FD14_RightDoorRearOpen_Icon_b : 74|1@1+ (1,0) [0|1] ""  CANOE
 SG_ FD14_BackDoorOpen_Icon_b : 73|1@1+ (1,0) [0|1] ""  CANOE
 SG_ FD14_FrontCam_NA_b : 72|1@1+ (1,0) [0|1] ""  CANOE
 SG_ FD14_LeftCam_NA_b : 71|1@1+ (1,0) [0|1] ""  CANOE
 SG_ FD14_BackCam_NA_b : 70|1@1+ (1,0) [0|1] ""  CANOE
 SG_ FD14_RightCam_NA_b : 69|1@1+ (1,0) [0|1] ""  CANOE
 SG_ FD14_TopViewBlack_b : 68|1@1+ (1,0) [0|1] ""  CANOE
 SG_ FD14_LeftDoorFrontClose_Icon_b : 67|1@1+ (1,0) [0|1] ""  CANOE
 SG_ FD14_LeftDoorRearClose_Icon_b : 66|1@1+ (1,0) [0|1] ""  CANOE
 SG_ FD14_RightDoorFrontClose_Icon_b : 65|1@1+ (1,0) [0|1] ""  CANOE
 SG_ FD14_RightDoorRearClose_Icon_b : 64|1@1+ (1,0) [0|1] ""  CANOE
 SG_ FD14_Reserved13_b : 63|1@1+ (1,0) [0|1] ""  CANOE
 SG_ FD14_PDC_RearCenter_Yellow_b : 62|1@1+ (1,0) [0|1] ""  CANOE
 SG_ FD14_PDC_RearCenter_Red_b : 61|1@1+ (1,0) [0|1] ""  CANOE
 SG_ FD14_Reserved12_b : 60|1@1+ (1,0) [0|1] ""  CANOE
 SG_ FD14_PDC_RearRight_Yellow_b : 59|1@1+ (1,0) [0|1] ""  CANOE
 SG_ FD14_PDC_RearRight_Red_b : 58|1@1+ (1,0) [0|1] ""  CANOE
 SG_ FD14_Reserved11_b : 57|1@1+ (1,0) [0|1] ""  CANOE
 SG_ FD14_PDC_FrontLeft_Yellow_b : 56|1@1+ (1,0) [0|1] ""  CANOE
 SG_ FD14_PDC_FrontLeft_Red_b : 55|1@1+ (1,0) [0|1] ""  CANOE
 SG_ FD14_Reserved10_b : 54|1@1+ (1,0) [0|1] ""  CANOE
 SG_ FD14_PDC_FrontCenter_Yellow_b : 53|1@1+ (1,0) [0|1] ""  CANOE
 SG_ FD14_PDC_FrontCenter_Red_b : 52|1@1+ (1,0) [0|1] ""  CANOE
 SG_ FD14_Reserved09_b : 51|1@1+ (1,0) [0|1] ""  CANOE
 SG_ FD14_PDC_FrontRight_Yellow_b : 50|1@1+ (1,0) [0|1] ""  CANOE
 SG_ FD14_PDC_FrontRight_Red_b : 49|1@1+ (1,0) [0|1] ""  CANOE
 SG_ FD14_Reserved08_b : 48|1@1+ (1,0) [0|1] ""  CANOE
 SG_ FD14_PDC_RearLeft_Yellow_b : 47|1@1+ (1,0) [0|1] ""  CANOE
 SG_ FD14_PDC_RearLeft_Red_b : 46|1@1+ (1,0) [0|1] ""  CANOE
 SG_ FD14_SrvLayout_b : 45|1@1+ (1,0) [0|1] ""  CANOE
 SG_ FD14_SrvStAngIndOk_b : 44|1@1+ (1,0) [0|1] ""  CANOE
 SG_ FD14_SrvStAngIndNok_b : 43|1@1+ (1,0) [0|1] ""  CANOE
 SG_ FD14_SrvSpOmIndOk_b : 42|1@1+ (1,0) [0|1] ""  CANOE
 SG_ FD14_SrvSpOmIndNok_b : 41|1@1+ (1,0) [0|1] ""  CANOE
 SG_ FD14_SrvChkIndRun_b : 40|1@1+ (1,0) [0|1] ""  CANOE
 SG_ FD14_SrvChkIndOk_b : 39|1@1+ (1,0) [0|1] ""  CANOE
 SG_ FD14_SrvChkIndNok_b : 38|1@1+ (1,0) [0|1] ""  CANOE
 SG_ FD14_SrvChkIndCondNok_b : 37|1@1+ (1,0) [0|1] ""  CANOE
 SG_ FD14_SrvCamIndFrOk_b : 36|1@1+ (1,0) [0|1] ""  CANOE
 SG_ FD14_SrvCamIndFrNok_b : 35|1@1+ (1,0) [0|1] ""  CANOE
 SG_ FD14_SrvCamIndFrPend_b : 34|1@1+ (1,0) [0|1] ""  CANOE
 SG_ FD14_SrvCamIndFrNone_b : 33|1@1+ (1,0) [0|1] ""  CANOE
 SG_ FD14_SrvCamIndLeOk_b : 32|1@1+ (1,0) [0|1] ""  CANOE
 SG_ FD14_SrvCamIndLeNok_b : 31|1@1+ (1,0) [0|1] ""  CANOE
 SG_ FD14_SrvCamIndLePend_b : 30|1@1+ (1,0) [0|1] ""  CANOE
 SG_ FD14_SrvCamIndLeNone_b : 29|1@1+ (1,0) [0|1] ""  CANOE
 SG_ FD14_SrvCamIndBaOk_b : 28|1@1+ (1,0) [0|1] ""  CANOE
 SG_ FD14_SrvCamIndBaNok_b : 27|1@1+ (1,0) [0|1] ""  CANOE
 SG_ FD14_SrvCamIndBaPend_b : 26|1@1+ (1,0) [0|1] ""  CANOE
 SG_ FD14_SrvCamIndBaNone_b : 25|1@1+ (1,0) [0|1] ""  CANOE
 SG_ FD14_SrvCamIndRiOk_b : 24|1@1+ (1,0) [0|1] ""  CANOE
 SG_ FD14_SrvCamIndRiNok_b : 23|1@1+ (1,0) [0|1] ""  CANOE
 SG_ FD14_SrvCamIndRiPend_b : 22|1@1+ (1,0) [0|1] ""  CANOE
 SG_ FD14_SrvCamIndRiNone_b : 21|1@1+ (1,0) [0|1] ""  CANOE
 SG_ FD14_SrvPrgBar0Per_b : 20|1@1+ (1,0) [0|1] ""  CANOE
 SG_ FD14_SrvPrgBar20Per_b : 19|1@1+ (1,0) [0|1] ""  CANOE
 SG_ FD14_SrvPrgBar40Per_b : 18|1@1+ (1,0) [0|1] ""  CANOE
 SG_ FD14_SrvPrgBar60Per_b : 17|1@1+ (1,0) [0|1] ""  CANOE
 SG_ FD14_SrvPrgBar80Per_b : 16|1@1+ (1,0) [0|1] ""  CANOE
 SG_ FD14_SrvPrgBar100Per_b : 15|1@1+ (1,0) [0|1] ""  CANOE
 SG_ FD14_TrscOvl : 14|1@1+ (1,0) [0|1] ""  CANOE
 SG_ FD14_TrscJackKnifeOrange : 13|1@1+ (1,0) [0|1] ""  CANOE
 SG_ FD14_TrscJackKnifeRed : 12|1@1+ (1,0) [0|1] ""  CANOE
 SG_ FD14_TrscTrailerRed : 11|1@1+ (1,0) [0|1] ""  CANOE
 SG_ FD14_THATriangleOverlay : 10|1@1+ (1,0) [0|1] ""  CANOE
 SG_ FD14_THACouplerBulletIcon : 9|1@1+ (1,0) [0|1] ""  CANOE
 SG_ FD14_THAButtonGrey : 8|1@1+ (1,0) [0|1] ""  CANOE
 SG_ FD14_THAButtonSelectable : 7|1@1+ (1,0) [0|1] ""  CANOE
 SG_ FD14_THAConfirmButton : 6|1@1+ (1,0) [0|1] ""  CANOE
 SG_ FD14_THAStartButton : 5|1@1+ (1,0) [0|1] ""  CANOE
 SG_ FD14_THAProgressBar : 4|1@1+ (1,0) [0|1] ""  CANOE
 SG_ FD14_Reserved3_b : 3|1@1+ (1,0) [0|1] ""  CANOE
 SG_ FD14_Reserved2_b : 2|1@1+ (1,0) [0|1] ""  CANOE
 SG_ FD14_Reserved1_b : 1|1@1+ (1,0) [0|1] ""  CANOE
 SG_ FD14_Reserved0_b : 0|1@1+ (1,0) [0|1] ""  CANOE

BO_ 2654552146 HMI_Curr_Requested_ProxiConfig: 16 CVADAS
 SG_ FD14_MePRX_b_TRSCPresence : 112|1@1+ (1,0) [0|1] ""  CANOE
 SG_ FD14_MePRX_b_TRGPresence : 104|1@1+ (1,0) [0|1] ""  CANOE
 SG_ FD14_MePRX_b_CanNode27 : 96|1@1+ (1,0) [0|1] ""  CANOE
 SG_ FD14_MePRX_b_CANNode95 : 88|1@1+ (1,0) [0|1] ""  CANOE
 SG_ FD14_MePRX_b_AuxTrlrCam : 80|1@1+ (1,0) [0|1] ""  CANOE
 SG_ FD14_MePRX_b_FrwFacingCam : 72|1@1+ (1,0) [0|1] ""  CANOE
 SG_ FD14_MePRX_b_SurroundViewCamera : 64|1@1+ (1,0) [0|1] ""  CANOE
 SG_ FD14_MePRX_e_AutonomyLvl : 56|8@1+ (1,0) [0|255] ""  CANOE
 SG_ FD14_MePRX_e_PAMTunSet : 48|8@1+ (1,0) [0|255] ""  CANOE
 SG_ FD14_MePRX_e_MirrorType : 40|8@1+ (1,0) [0|255] ""  CANOE
 SG_ FD14_MePRX_e_RadDispType : 32|8@1+ (1,0) [0|255] ""  CANOE
 SG_ FD14_MePRX_e_SteerRatRackPi_0000 : 24|8@1+ (1,0) [0|255] ""  CANOE
 SG_ FD14_MePRX_e_Wheelbase : 16|8@1+ (1,0) [0|255] ""  CANOE
 SG_ FD14_MePRX_e_VehLineCfg : 8|8@1+ (1,0) [0|255] ""  CANOE
 SG_ FD14_MePRX_e_VariantID : 0|8@1+ (1,0) [0|255] ""  CANOE

BO_ 2654552184 LMD_LaneLinesDebug_1: 64 CVADAS
 SG_ FD14_LMD_m_Line_2_End_Range : 368|32@1- (0.5,0) [-25|38.5] ""  CANOE
 SG_ FD14_LMD_m_Line_2_Start_Range : 336|32@1- (0.5,0) [-25|38.5] ""  CANOE
 SG_ FD14_LMD_rad_Line_2_Heading : 304|32@1- (0.000976562,0) [-0.357|0.6420234375] ""  CANOE
 SG_ FD14_LMD_m_Line_2_Offset : 272|32@1- (0.01,0) [-5|5.23] ""  CANOE
 SG_ FD14_LMD_e_Line_2_Type : 72|8@1+ (1,0) [0|15] ""  CANOE
 SG_ FD14_LMD_pct_Line_2_Confidence : 240|32@1- (0.1,0) [0|1.5] ""  CANOE
 SG_ FD14_LMD_px_Line_2_Curvature : 208|32@1- (9.77E-007,0) [-0.032|0.032027695] ""  CANOE
 SG_ FD14_LMD_m_Line_1_End_Range : 176|32@1- (0.5,0) [-25|38.5] ""  CANOE
 SG_ FD14_LMD_m_Line_1_Start_Range : 144|32@1- (0.5,0) [-25|38.5] ""  CANOE
 SG_ FD14_LMD_rad_Line_1_Heading : 112|32@1- (0.000976562,0) [-0.357|0.6420234375] ""  CANOE
 SG_ FD14_LMD_m_Line_1_Offset : 80|32@1- (0.01,0) [-5|5.23] ""  CANOE
 SG_ FD14_LMD_e_Line_1_Type : 64|8@1+ (1,0) [0|15] ""  CANOE
 SG_ FD14_LMD_px_Line_1_Curvature : 32|32@1- (9.77E-007,0) [-0.032|0.032027695] ""  CANOE
 SG_ FD14_LMD_pct_Line_1_Confidence : 0|32@1- (0.1,0) [0|1.5] ""  CANOE

BO_ 2654552321 LMD_LaneLinesDebug_2: 64 CVADAS
 SG_ FD14_LMD_e_Line_4_Type : 392|8@1+ (1,0) [0|15] ""  CANOE
 SG_ FD14_LMD_e_Line_3_Type : 384|8@1+ (1,0) [0|15] ""  CANOE
 SG_ FD14_LMD_pct_Line_3_Confidence : 352|32@1- (0.1,0) [0|1.5] ""  CANOE
 SG_ FD14_LMD_px_Line_3_Curvature : 320|32@1- (9.77E-007,0) [-0.032|0.032027695] ""  CANOE
 SG_ FD14_LMD_m_Line_4_End_Range : 288|32@1- (0.5,0) [-25|38.5] ""  CANOE
 SG_ FD14_LMD_m_Line_4_Start_Range : 256|32@1- (0.5,0) [-25|38.5] ""  CANOE
 SG_ FD14_LMD_rad_Line_4_Heading : 224|32@1- (0.000976562,0) [-0.357|0.6420234375] ""  CANOE
 SG_ FD14_LMD_m_Line_4_Offset : 192|32@1- (0.01,0) [-5|5.23] ""  CANOE
 SG_ FD14_LMD_pct_Line_4_Confidence : 160|32@1- (0.1,0) [0|1.5] ""  CANOE
 SG_ FD14_LMD_px_Line_4_Curvature : 128|32@1- (9.77E-007,0) [-0.032|0.032027695] ""  CANOE
 SG_ FD14_LMD_m_Line_3_End_Range : 96|32@1- (0.5,0) [-25|38.5] ""  CANOE
 SG_ FD14_LMD_m_Line_3_Start_Range : 64|32@1- (0.5,0) [-25|38.5] ""  CANOE
 SG_ FD14_LMD_rad_Line_3_Heading : 32|32@1- (0.000976562,0) [-0.357|0.6420234375] ""  CANOE
 SG_ FD14_LMD_m_Line_3_Offset : 0|32@1- (0.01,0) [-5|5.23] ""  CANOE

BO_ 2654552322 LMD_SegmentDebug_1: 64 CVADAS
 SG_ FD14_LMD_m_Segment_5_Y1 : 448|32@1- (0.01,0) [-5|5.23] ""  CANOE
 SG_ FD14_LMD_m_Segment_4_Y1 : 416|32@1- (0.01,0) [-5|5.23] ""  CANOE
 SG_ FD14_LMD_m_Segment_3_Y1 : 384|32@1- (0.01,0) [-5|5.23] ""  CANOE
 SG_ FD14_LMD_m_Segment_2_Y1 : 352|32@1- (0.01,0) [-5|5.23] ""  CANOE
 SG_ FD14_LMD_m_Segment_1_Y1 : 320|32@1- (0.01,0) [-5|5.23] ""  CANOE
 SG_ FD14_LMD_m_Segment_8_X1 : 288|32@1- (0.03,0) [-21|40.41] ""  CANOE
 SG_ FD14_LMD_m_Segment_6_X1 : 256|32@1- (0.03,0) [-21|40.41] ""  CANOE
 SG_ FD14_LMD_m_Segment_7_X1 : 224|32@1- (0.03,0) [-21|40.41] ""  CANOE
 SG_ FD14_LMD_m_Segment_5_X1 : 192|32@1- (0.03,0) [-21|40.41] ""  CANOE
 SG_ FD14_LMD_m_Segment_4_X1 : 160|32@1- (0.03,0) [-21|40.41] ""  CANOE
 SG_ FD14_LMD_m_Segment_3_X1 : 128|32@1- (0.03,0) [-21|40.41] ""  CANOE
 SG_ FD14_LMD_m_Segment_2_X1 : 96|32@1- (0.03,0) [-21|40.41] ""  CANOE
 SG_ FD14_LMD_m_Segment_1_X1 : 64|32@1- (0.03,0) [-21|40.41] ""  CANOE
 SG_ FD14_LMD_e_Segment_7_ID : 56|8@1+ (1,0) [0|15] ""  CANOE
 SG_ FD14_LMD_e_Segment_8_ID : 48|8@1+ (1,0) [0|15] ""  CANOE
 SG_ FD14_LMD_e_Segment_5_ID : 40|8@1+ (1,0) [0|15] ""  CANOE
 SG_ FD14_LMD_e_Segment_6_ID : 32|8@1+ (1,0) [0|15] ""  CANOE
 SG_ FD14_LMD_e_Segment_3_ID : 24|8@1+ (1,0) [0|15] ""  CANOE
 SG_ FD14_LMD_e_Segment_4_ID : 16|8@1+ (1,0) [0|15] ""  CANOE
 SG_ FD14_LMD_e_Segment_1_ID : 8|8@1+ (1,0) [0|15] ""  CANOE
 SG_ FD14_LMD_e_Segment_2_ID : 0|8@1+ (1,0) [0|15] ""  CANOE

BO_ 2654552323 LMD_SegmentDebug_1_2: 12 CVADAS
 SG_ FD14_LMD_m_Segment_8_Y1 : 32|32@1- (0.01,0) [-5|5.23] ""  CANOE
 SG_ FD14_LMD_m_Segment_7_Y1 : 64|32@1- (0.01,0) [-5|5.23] ""  CANOE
 SG_ FD14_LMD_m_Segment_6_Y1 : 0|32@1- (0.01,0) [-5|5.23] ""  CANOE

BO_ 2654552324 LMD_SegmentDebug_2_1: 64 CVADAS
 SG_ FD14_LMD_m_Segment_8_Y2 : 480|32@1- (0.01,0) [-5|5.23] ""  CANOE
 SG_ FD14_LMD_m_Segment_7_Y2 : 448|32@1- (0.01,0) [-5|5.23] ""  CANOE
 SG_ FD14_LMD_m_Segment_6_Y2 : 416|32@1- (0.01,0) [-5|5.23] ""  CANOE
 SG_ FD14_LMD_m_Segment_5_Y2 : 384|32@1- (0.01,0) [-5|5.23] ""  CANOE
 SG_ FD14_LMD_m_Segment_4_Y2 : 352|32@1- (0.01,0) [-5|5.23] ""  CANOE
 SG_ FD14_LMD_m_Segment_3_Y2 : 320|32@1- (0.01,0) [-5|5.23] ""  CANOE
 SG_ FD14_LMD_m_Segment_2_Y2 : 288|32@1- (0.01,0) [-5|5.23] ""  CANOE
 SG_ FD14_LMD_m_Segment_1_Y2 : 256|32@1- (0.01,0) [-5|5.23] ""  CANOE
 SG_ FD14_LMD_m_Segment_8_X2 : 224|32@1- (0.03,0) [-21|40.41] ""  CANOE
 SG_ FD14_LMD_m_Segment_7_X2 : 192|32@1- (0.03,0) [-21|40.41] ""  CANOE
 SG_ FD14_LMD_m_Segment_6_X2 : 160|32@1- (0.03,0) [-21|40.41] ""  CANOE
 SG_ FD14_LMD_m_Segment_5_X2 : 128|32@1- (0.03,0) [-21|40.41] ""  CANOE
 SG_ FD14_LMD_m_Segment_4_X2 : 96|32@1- (0.03,0) [-21|40.41] ""  CANOE
 SG_ FD14_LMD_m_Segment_3_X2 : 64|32@1- (0.03,0) [-21|40.41] ""  CANOE
 SG_ FD14_LMD_m_Segment_2_X2 : 32|32@1- (0.03,0) [-21|40.41] ""  CANOE
 SG_ FD14_LMD_m_Segment_1_X2 : 0|32@1- (0.03,0) [-21|40.41] ""  CANOE

BO_ 2654552325 LMD_SegmentDebug_2_2: 48 CVADAS
 SG_ FD14_leLMD_e_HealthStatus : 304|8@1+ (1,0) [0|3] ""  CANOE
 SG_ FD14_IeLMD_e_CameraStatus : 296|8@1+ (1,0) [0|15] ""  CANOE
 SG_ FD14_Total_lines_count : 288|8@1+ (1,0) [0|100] ""  CANOE
 SG_ FD14_Frame_Index_Lanes__1 : 256|32@1+ (1,0) [0|2500] ""  CANOE
 SG_ FD14_LMD_pct_Segment_7_Confidenc : 224|32@1- (0.1,0) [0|1.5] ""  CANOE
 SG_ FD14_LMD_pct_Segment_8_Confidenc : 192|32@1- (0.1,0) [0|1.5] ""  CANOE
 SG_ FD14_LMD_pct_Segment_5_Confidenc : 160|32@1- (0.1,0) [0|1.5] ""  CANOE
 SG_ FD14_LMD_pct_Segment_6_Confidenc : 128|32@1- (0.1,0) [0|1.5] ""  CANOE
 SG_ FD14_LMD_pct_Segment_3_Confidenc : 96|32@1- (0.1,0) [0|1.5] ""  CANOE
 SG_ FD14_LMD_pct_Segment_4_Confidenc : 64|32@1- (0.1,0) [0|1.5] ""  CANOE
 SG_ FD14_LMD_pct_Segment_1_Confidenc : 32|32@1- (0.1,0) [0|1.5] ""  CANOE
 SG_ FD14_LMD_pct_Segment_2_Confidenc : 0|32@1- (0.1,0) [0|1.5] ""  CANOE

BO_ 2654814230 Log_SnrMeasData_01: 64 CVADAS
 SG_ FD14_Log_SnrMeasData_1 : 0|64@1+ (1,0) [0|1.84467440737096E+019] ""  CANOE

BO_ 2654814231 Log_SnrMeasData_02: 64 CVADAS
 SG_ FD14_Log_SnrMeasData_2 : 0|64@1+ (1,0) [0|1.84467440737096E+019] ""  CANOE

BO_ 2654814247 Log_SnrMeasData_03: 64 CVADAS
 SG_ FD14_Log_SnrMeasData_3 : 0|64@1+ (1,0) [0|1.84467440737096E+019] ""  CANOE

BO_ 2654814233 Log_SnrMeasData_04: 64 CVADAS
 SG_ FD14_Log_SnrMeasData_4 : 0|64@1+ (1,0) [0|1.84467440737096E+019] ""  CANOE

BO_ 2654814234 Log_SnrMeasData_05: 64 CVADAS
 SG_ FD14_Log_SnrMeasData_5 : 0|64@1+ (1,0) [0|1.84467440737096E+019] ""  CANOE

BO_ 2654814235 Log_SnrMeasData_06: 64 CVADAS
 SG_ FD14_Log_SnrMeasData_6 : 0|64@1+ (1,0) [0|1.84467440737096E+019] ""  CANOE

BO_ 2654814236 Log_SnrMeasData_07: 64 CVADAS
 SG_ FD14_Log_SnrMeasData_7 : 0|64@1+ (1,0) [0|1.84467440737096E+019] ""  CANOE
 SG_ FD14_SnrMeasDataChecksum : 344|32@1+ (1,0) [0|0] ""  CANOE

BO_ 2654814237 Log_SnrTemperature: 64 CVADAS
 SG_ FD14_Log_Sensor_Temperature : 0|64@1+ (1,0) [0|1.84467440737096E+019] ""  CANOE

BO_ 2654552337 ME_Debug_SensorTestData_1: 64 CVADAS
 SG_ FD14_Tstr_SD_FSR_DrvFreq : 0|16@1+ (572,0) [0|145860] "hz"  CANOE
 SG_ FD14_Tstr_SD_FSR_RingFreq : 16|16@1+ (572,0) [0|145860] "hz"  CANOE
 SG_ FD14_Tstr_SD_FSR_Ringtime_us : 32|12@1+ (1,0) [0|4095] ""  CANOE
 SG_ FD14_Tstr_SD_FSR_Unfiltered_DirD : 44|10@1+ (1,0) [0|1023] "cm"  CANOE
 SG_ FD14_Tstr_SD_FSR_Unfiltered_0000 : 54|10@1+ (1,0) [0|1023] "cm"  CANOE
 SG_ FD14_Tstr_SD_FSR_EchoHeight_adc : 64|8@1+ (1,0) [0|255] "adc"  CANOE
 SG_ FD14_Tstr_SD_FSR_SensorBlkgSetCo : 72|8@1+ (1,0) [0|255] ""  CANOE
 SG_ FD14_Tstr_SD_FSR_SensorBlkgClrCo : 80|8@1+ (1,0) [0|255] ""  CANOE
 SG_ FD14_Tstr_SD_FOR_DrvFreq : 88|16@1+ (572,0) [0|145860] "hz"  CANOE
 SG_ FD14_Tstr_SD_FOR_RingFreq : 104|16@1+ (572,0) [0|145860] "hz"  CANOE
 SG_ FD14_Tstr_SD_FOR_Ringtime_us : 120|12@1+ (1,0) [0|4095] ""  CANOE
 SG_ FD14_Tstr_SD_FOR_Unfiltered_DirD : 132|10@1+ (1,0) [0|1023] "cm"  CANOE
 SG_ FD14_Tstr_SD_FOR_Unfiltered_0000 : 142|10@1+ (1,0) [0|1023] "cm"  CANOE
 SG_ FD14_Tstr_SD_FOR_EchoHeight_adc : 152|8@1+ (1,0) [0|255] "adc"  CANOE
 SG_ FD14_Tstr_SD_FOR_SensorBlkgSetCo : 160|8@1+ (1,0) [0|255] ""  CANOE
 SG_ FD14_Tstr_SD_FOR_SensorBlkgClrCo : 168|8@1+ (1,0) [0|255] ""  CANOE
 SG_ FD14_Tstr_SD_FIR_DrvFreq : 176|16@1+ (572,0) [0|145860] "hz"  CANOE
 SG_ FD14_Tstr_SD_FIR_RingFreq : 192|16@1+ (572,0) [0|145860] "hz"  CANOE
 SG_ FD14_Tstr_SD_FIR_Ringtime_us : 208|12@1+ (1,0) [0|4095] ""  CANOE
 SG_ FD14_Tstr_SD_FIR_Unfiltered_DirD : 220|10@1+ (1,0) [0|1023] "cm"  CANOE
 SG_ FD14_Tstr_SD_FIR_Unfiltered_0000 : 230|10@1+ (1,0) [0|1023] "cm"  CANOE
 SG_ FD14_Tstr_SD_FIR_EchoHeight_adc : 240|8@1+ (1,0) [0|255] "adc"  CANOE
 SG_ FD14_Tstr_SD_FIR_SensorBlkgSetCo : 248|8@1+ (1,0) [0|255] ""  CANOE
 SG_ FD14_Tstr_SD_FIR_SensorBlkgClrCo : 256|8@1+ (1,0) [0|255] ""  CANOE
 SG_ FD14_Tstr_SD_FIL_DrvFreq : 264|16@1+ (572,0) [0|145860] "hz"  CANOE
 SG_ FD14_Tstr_SD_FIL_RingFreq : 280|16@1+ (572,0) [0|145860] "hz"  CANOE
 SG_ FD14_Tstr_SD_FIL_Ringtime_us : 296|12@1+ (1,0) [0|4095] ""  CANOE
 SG_ FD14_Tstr_SD_FIL_Unfiltered_DirD : 308|10@1+ (1,0) [0|1023] "cm"  CANOE
 SG_ FD14_Tstr_SD_FIL_Unfiltered_0000 : 318|10@1+ (1,0) [0|1023] "cm"  CANOE
 SG_ FD14_Tstr_SD_FIL_EchoHeight_adc : 328|8@1+ (1,0) [0|255] "adc"  CANOE
 SG_ FD14_Tstr_SD_FIL_SensorBlkgSetCo : 336|8@1+ (1,0) [0|255] ""  CANOE
 SG_ FD14_Tstr_SD_FIL_SensorBlkgClrCo : 344|8@1+ (1,0) [0|255] ""  CANOE

BO_ 2654552338 ME_Debug_SensorTestData_2: 64 CVADAS
 SG_ FD14_Tstr_SD_FOL_DrvFreq : 0|16@1+ (572,0) [0|145860] "hz"  CANOE
 SG_ FD14_Tstr_SD_FOL_RingFreq : 16|16@1+ (572,0) [0|145860] "hz"  CANOE
 SG_ FD14_Tstr_SD_FOL_Ringtime_us : 32|12@1+ (1,0) [0|4095] ""  CANOE
 SG_ FD14_Tstr_SD_FOL_Unfiltered_DirD : 44|10@1+ (1,0) [0|1023] "cm"  CANOE
 SG_ FD14_Tstr_SD_FOL_Unfiltered_0000 : 54|10@1+ (1,0) [0|1023] "cm"  CANOE
 SG_ FD14_Tstr_SD_FOL_EchoHeight_adc : 64|8@1+ (1,0) [0|255] "adc"  CANOE
 SG_ FD14_Tstr_SD_FOL_SensorBlkgSetCo : 72|8@1+ (1,0) [0|255] ""  CANOE
 SG_ FD14_Tstr_SD_FOL_SensorBlkgClrCo : 80|8@1+ (1,0) [0|255] ""  CANOE
 SG_ FD14_Tstr_SD_FSL_DrvFreq : 88|16@1+ (572,0) [0|145860] "hz"  CANOE
 SG_ FD14_Tstr_SD_FSL_RingFreq : 104|16@1+ (572,0) [0|145860] "hz"  CANOE
 SG_ FD14_Tstr_SD_FSL_Ringtime_us : 120|12@1+ (1,0) [0|4095] ""  CANOE
 SG_ FD14_Tstr_SD_FSL_Unfiltered_DirD : 132|10@1+ (1,0) [0|1023] "cm"  CANOE
 SG_ FD14_Tstr_SD_FSL_Unfiltered_0000 : 142|10@1+ (1,0) [0|1023] "cm"  CANOE
 SG_ FD14_Tstr_SD_FSL_EchoHeight_adc : 152|8@1+ (1,0) [0|255] "adc"  CANOE
 SG_ FD14_Tstr_SD_FSL_SensorBlkgSetCo : 160|8@1+ (1,0) [0|255] ""  CANOE
 SG_ FD14_Tstr_SD_FSL_SensorBlkgClrCo : 168|8@1+ (1,0) [0|255] ""  CANOE
 SG_ FD14_Tstr_SD_RSR_DrvFreq : 176|16@1+ (572,0) [0|145860] "hz"  CANOE
 SG_ FD14_Tstr_SD_RSR_RingFreq : 192|16@1+ (572,0) [0|145860] "hz"  CANOE
 SG_ FD14_Tstr_SD_RSR_Ringtime_us : 208|12@1+ (1,0) [0|4095] ""  CANOE
 SG_ FD14_Tstr_SD_RSR_Unfiltered_DirD : 220|10@1+ (1,0) [0|1023] "cm"  CANOE
 SG_ FD14_Tstr_SD_RSR_Unfiltered_0000 : 230|10@1+ (1,0) [0|1023] "cm"  CANOE
 SG_ FD14_Tstr_SD_RSR_EchoHeight_adc : 240|8@1+ (1,0) [0|255] "adc"  CANOE
 SG_ FD14_Tstr_SD_RSR_SensorBlkgSetCo : 248|8@1+ (1,0) [0|255] ""  CANOE
 SG_ FD14_Tstr_SD_RSR_SensorBlkgClrCo : 256|8@1+ (1,0) [0|255] ""  CANOE
 SG_ FD14_Tstr_SD_ROR_DrvFreq : 264|16@1+ (572,0) [0|145860] "hz"  CANOE
 SG_ FD14_Tstr_SD_ROR_RingFreq : 280|16@1+ (572,0) [0|145860] "hz"  CANOE
 SG_ FD14_Tstr_SD_ROR_Ringtime_us : 296|12@1+ (1,0) [0|4095] ""  CANOE
 SG_ FD14_Tstr_SD_ROR_Unfiltered_DirD : 308|10@1+ (1,0) [0|1023] "cm"  CANOE
 SG_ FD14_Tstr_SD_ROR_Unfiltered_0000 : 318|10@1+ (1,0) [0|1023] "cm"  CANOE
 SG_ FD14_Tstr_SD_ROR_EchoHeight_adc : 328|8@1+ (1,0) [0|255] "adc"  CANOE
 SG_ FD14_Tstr_SD_ROR_SensorBlkgSetCo : 336|8@1+ (1,0) [0|255] ""  CANOE
 SG_ FD14_Tstr_SD_ROR_SensorBlkgClrCo : 344|8@1+ (1,0) [0|255] ""  CANOE

BO_ 2654552339 ME_Debug_SensorTestData_3: 64 CVADAS
 SG_ FD14_Tstr_SD_RIR_DrvFreq : 0|16@1+ (572,0) [0|145860] "hz"  CANOE
 SG_ FD14_Tstr_SD_RIR_RingFreq : 16|16@1+ (572,0) [0|145860] "hz"  CANOE
 SG_ FD14_Tstr_SD_RIR_Ringtime_us : 32|12@1+ (1,0) [0|4095] ""  CANOE
 SG_ FD14_Tstr_SD_RIR_Unfiltered_DirD : 44|10@1+ (1,0) [0|1023] "cm"  CANOE
 SG_ FD14_Tstr_SD_RIR_Unfiltered_0000 : 54|10@1+ (1,0) [0|1023] "cm"  CANOE
 SG_ FD14_Tstr_SD_RIR_EchoHeight_adc : 64|8@1+ (1,0) [0|255] "adc"  CANOE
 SG_ FD14_Tstr_SD_RIR_SensorBlkgSetCo : 72|8@1+ (1,0) [0|255] ""  CANOE
 SG_ FD14_Tstr_SD_RIR_SensorBlkgClrCo : 80|8@1+ (1,0) [0|255] ""  CANOE
 SG_ FD14_Tstr_SD_RIL_DrvFreq : 88|16@1+ (572,0) [0|145860] "hz"  CANOE
 SG_ FD14_Tstr_SD_RIL_RingFreq : 104|16@1+ (572,0) [0|145860] "hz"  CANOE
 SG_ FD14_Tstr_SD_RIL_Ringtime_us : 120|12@1+ (1,0) [0|4095] ""  CANOE
 SG_ FD14_Tstr_SD_RIL_Unfiltered_DirD : 132|10@1+ (1,0) [0|1023] "cm"  CANOE
 SG_ FD14_Tstr_SD_RIL_Unfiltered_0000 : 142|10@1+ (1,0) [0|1023] "cm"  CANOE
 SG_ FD14_Tstr_SD_RIL_EchoHeight_adc : 152|8@1+ (1,0) [0|255] "adc"  CANOE
 SG_ FD14_Tstr_SD_RIL_SensorBlkgSetCo : 160|8@1+ (1,0) [0|255] ""  CANOE
 SG_ FD14_Tstr_SD_RIL_SensorBlkgClrCo : 168|8@1+ (1,0) [0|255] ""  CANOE
 SG_ FD14_Tstr_SD_ROL_DrvFreq : 176|16@1+ (572,0) [0|145860] "hz"  CANOE
 SG_ FD14_Tstr_SD_ROL_RingFreq : 192|16@1+ (572,0) [0|145860] "hz"  CANOE
 SG_ FD14_Tstr_SD_ROL_Ringtime_us : 208|12@1+ (1,0) [0|4095] ""  CANOE
 SG_ FD14_Tstr_SD_ROL_Unfiltered_DirD : 220|10@1+ (1,0) [0|1023] "cm"  CANOE
 SG_ FD14_Tstr_SD_ROL_Unfiltered_0000 : 230|10@1+ (1,0) [0|1023] "cm"  CANOE
 SG_ FD14_Tstr_SD_ROL_EchoHeight_adc : 240|8@1+ (1,0) [0|255] "adc"  CANOE
 SG_ FD14_Tstr_SD_ROL_SensorBlkgSetCo : 248|8@1+ (1,0) [0|255] ""  CANOE
 SG_ FD14_Tstr_SD_ROL_SensorBlkgClrCo : 256|8@1+ (1,0) [0|255] ""  CANOE
 SG_ FD14_Tstr_SD_RSL_DrvFreq : 264|16@1+ (572,0) [0|145860] "hz"  CANOE
 SG_ FD14_Tstr_SD_RSL_RingFreq : 280|16@1+ (572,0) [0|145860] "hz"  CANOE
 SG_ FD14_Tstr_SD_RSL_Ringtime_us : 296|12@1+ (1,0) [0|4095] ""  CANOE
 SG_ FD14_Tstr_SD_RSL_Unfiltered_DirD : 308|10@1+ (1,0) [0|1023] "cm"  CANOE
 SG_ FD14_Tstr_SD_RSL_Unfiltered_0000 : 318|10@1+ (1,0) [0|1023] "cm"  CANOE
 SG_ FD14_Tstr_SD_RSL_EchoHeight_adc : 328|8@1+ (1,0) [0|255] "adc"  CANOE
 SG_ FD14_Tstr_SD_RSL_SensorBlkgSetCo : 336|8@1+ (1,0) [0|255] ""  CANOE
 SG_ FD14_Tstr_SD_RSL_SensorBlkgClrCo : 344|8@1+ (1,0) [0|255] ""  CANOE

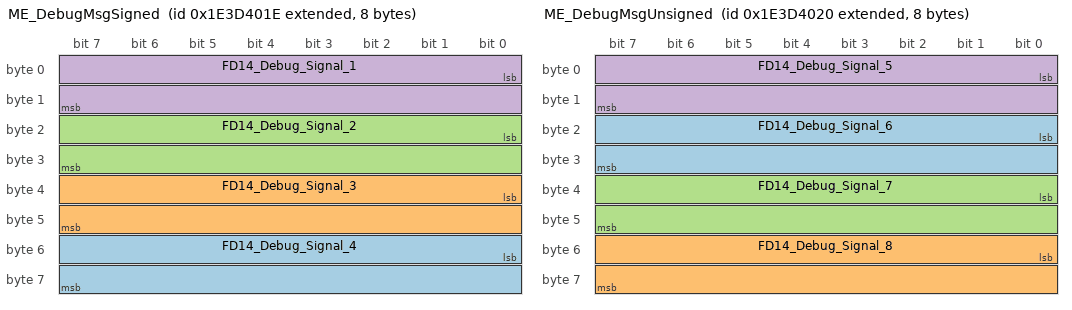
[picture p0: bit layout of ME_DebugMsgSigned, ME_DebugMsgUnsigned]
BO_ 2654814238 ME_DebugMsgSigned: 8 CVADAS
 SG_ FD14_Debug_Signal_4 : 48|16@1- (1,0) [0|0] ""  CANOE
 SG_ FD14_Debug_Signal_3 : 32|16@1- (1,0) [0|0] ""  CANOE
 SG_ FD14_Debug_Signal_2 : 16|16@1- (1,0) [0|0] ""  CANOE
 SG_ FD14_Debug_Signal_1 : 0|16@1- (1,0) [0|0] ""  CANOE

BO_ 2654814240 ME_DebugMsgUnsigned: 8 CVADAS
 SG_ FD14_Debug_Signal_6 : 16|16@1+ (1,0) [0|0] ""  CANOE
 SG_ FD14_Debug_Signal_8 : 48|16@1+ (1,0) [0|0] ""  CANOE
 SG_ FD14_Debug_Signal_7 : 32|16@1+ (1,0) [0|0] ""  CANOE
 SG_ FD14_Debug_Signal_5 : 0|16@1+ (1,0) [0|0] ""  CANOE

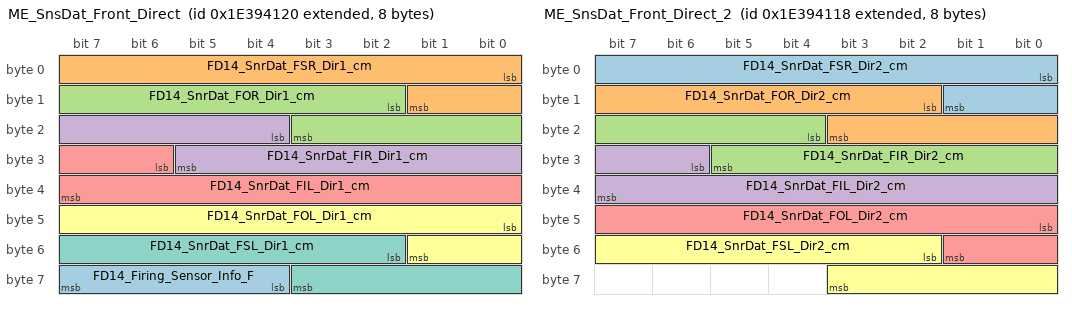
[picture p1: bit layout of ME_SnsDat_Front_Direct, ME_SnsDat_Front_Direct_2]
BO_ 2654552352 ME_SnsDat_Front_Direct: 8 CVADAS
 SG_ FD14_Firing_Sensor_Info_F : 60|4@1+ (1,0) [0|8] ""  CANOE
 SG_ FD14_SnrDat_FSR_Dir1_cm : 0|10@1+ (1,0) [0|1023] ""  CANOE
 SG_ FD14_SnrDat_FOR_Dir1_cm : 10|10@1+ (1,0) [0|1023] ""  CANOE
 SG_ FD14_SnrDat_FIR_Dir1_cm : 20|10@1+ (1,0) [0|1023] ""  CANOE
 SG_ FD14_SnrDat_FIL_Dir1_cm : 30|10@1+ (1,0) [0|1023] ""  CANOE
 SG_ FD14_SnrDat_FOL_Dir1_cm : 40|10@1+ (1,0) [0|1023] ""  CANOE
 SG_ FD14_SnrDat_FSL_Dir1_cm : 50|10@1+ (1,0) [0|1023] ""  CANOE

BO_ 2654552344 ME_SnsDat_Front_Direct_2: 8 CVADAS
 SG_ FD14_SnrDat_FSR_Dir2_cm : 0|10@1+ (1,0) [0|1023] ""  CANOE
 SG_ FD14_SnrDat_FOR_Dir2_cm : 10|10@1+ (1,0) [0|1023] ""  CANOE
 SG_ FD14_SnrDat_FIR_Dir2_cm : 20|10@1+ (1,0) [0|1023] ""  CANOE
 SG_ FD14_SnrDat_FIL_Dir2_cm : 30|10@1+ (1,0) [0|1023] ""  CANOE
 SG_ FD14_SnrDat_FOL_Dir2_cm : 40|10@1+ (1,0) [0|1023] ""  CANOE
 SG_ FD14_SnrDat_FSL_Dir2_cm : 50|10@1+ (1,0) [0|1023] ""  CANOE

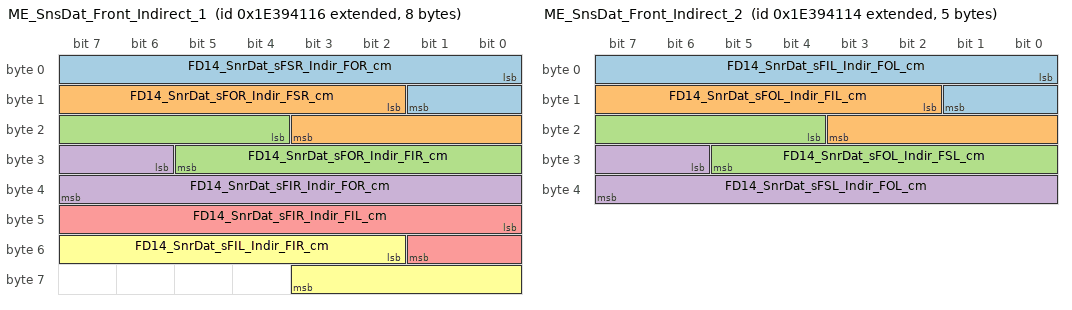
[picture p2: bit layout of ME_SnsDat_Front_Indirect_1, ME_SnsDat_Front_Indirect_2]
BO_ 2654552342 ME_SnsDat_Front_Indirect_1: 8 CVADAS
 SG_ FD14_SnrDat_sFSR_Indir_FOR_cm : 0|10@1+ (1,0) [0|1023] ""  CANOE
 SG_ FD14_SnrDat_sFOR_Indir_FSR_cm : 10|10@1+ (1,0) [0|1023] ""  CANOE
 SG_ FD14_SnrDat_sFOR_Indir_FIR_cm : 20|10@1+ (1,0) [0|1023] ""  CANOE
 SG_ FD14_SnrDat_sFIR_Indir_FOR_cm : 30|10@1+ (1,0) [0|1023] ""  CANOE
 SG_ FD14_SnrDat_sFIR_Indir_FIL_cm : 40|10@1+ (1,0) [0|1023] ""  CANOE
 SG_ FD14_SnrDat_sFIL_Indir_FIR_cm : 50|10@1+ (1,0) [0|1023] ""  CANOE

BO_ 2654552340 ME_SnsDat_Front_Indirect_2: 5 CVADAS
 SG_ FD14_SnrDat_sFIL_Indir_FOL_cm : 0|10@1+ (1,0) [0|1023] ""  CANOE
 SG_ FD14_SnrDat_sFOL_Indir_FIL_cm : 10|10@1+ (1,0) [0|1023] ""  CANOE
 SG_ FD14_SnrDat_sFOL_Indir_FSL_cm : 20|10@1+ (1,0) [0|1023] ""  CANOE
 SG_ FD14_SnrDat_sFSL_Indir_FOL_cm : 30|10@1+ (1,0) [0|1023] ""  CANOE

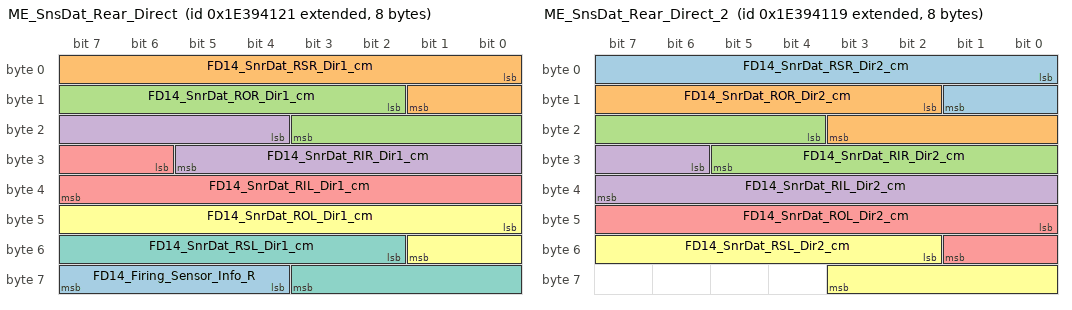
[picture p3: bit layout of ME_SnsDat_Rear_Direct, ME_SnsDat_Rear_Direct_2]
BO_ 2654552353 ME_SnsDat_Rear_Direct: 8 CVADAS
 SG_ FD14_Firing_Sensor_Info_R : 60|4@1+ (1,0) [0|8] ""  CANOE
 SG_ FD14_SnrDat_RSR_Dir1_cm : 0|10@1+ (1,0) [0|1023] ""  CANOE
 SG_ FD14_SnrDat_ROR_Dir1_cm : 10|10@1+ (1,0) [0|1023] ""  CANOE
 SG_ FD14_SnrDat_RIR_Dir1_cm : 20|10@1+ (1,0) [0|1023] ""  CANOE
 SG_ FD14_SnrDat_RIL_Dir1_cm : 30|10@1+ (1,0) [0|1023] ""  CANOE
 SG_ FD14_SnrDat_ROL_Dir1_cm : 40|10@1+ (1,0) [0|1023] ""  CANOE
 SG_ FD14_SnrDat_RSL_Dir1_cm : 50|10@1+ (1,0) [0|1023] ""  CANOE

BO_ 2654552345 ME_SnsDat_Rear_Direct_2: 8 CVADAS
 SG_ FD14_SnrDat_RSR_Dir2_cm : 0|10@1+ (1,0) [0|1023] ""  CANOE
 SG_ FD14_SnrDat_ROR_Dir2_cm : 10|10@1+ (1,0) [0|1023] ""  CANOE
 SG_ FD14_SnrDat_RIR_Dir2_cm : 20|10@1+ (1,0) [0|1023] ""  CANOE
 SG_ FD14_SnrDat_RIL_Dir2_cm : 30|10@1+ (1,0) [0|1023] ""  CANOE
 SG_ FD14_SnrDat_ROL_Dir2_cm : 40|10@1+ (1,0) [0|1023] ""  CANOE
 SG_ FD14_SnrDat_RSL_Dir2_cm : 50|10@1+ (1,0) [0|1023] ""  CANOE

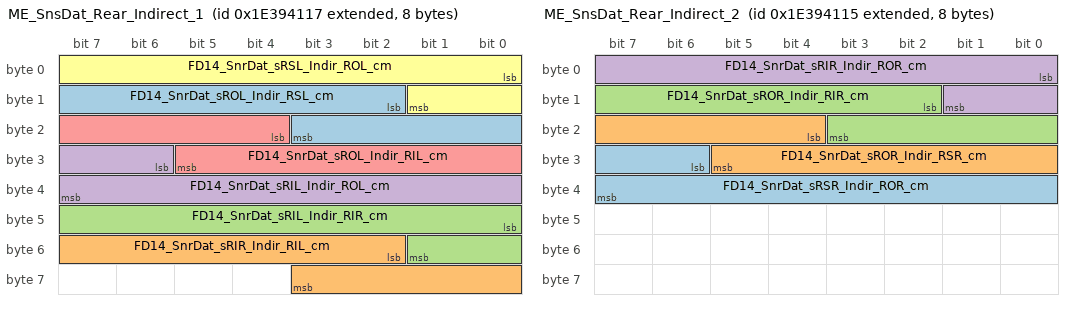
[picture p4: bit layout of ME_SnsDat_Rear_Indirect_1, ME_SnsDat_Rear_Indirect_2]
BO_ 2654552343 ME_SnsDat_Rear_Indirect_1: 8 CVADAS
 SG_ FD14_SnrDat_sROL_Indir_RSL_cm : 10|10@1+ (1,0) [0|1023] ""  CANOE
 SG_ FD14_SnrDat_sRIR_Indir_RIL_cm : 50|10@1+ (1,0) [0|1023] ""  CANOE
 SG_ FD14_SnrDat_sRIL_Indir_RIR_cm : 40|10@1+ (1,0) [0|1023] ""  CANOE
 SG_ FD14_SnrDat_sRIL_Indir_ROL_cm : 30|10@1+ (1,0) [0|1023] ""  CANOE
 SG_ FD14_SnrDat_sROL_Indir_RIL_cm : 20|10@1+ (1,0) [0|1023] ""  CANOE
 SG_ FD14_SnrDat_sRSL_Indir_ROL_cm : 0|10@1+ (1,0) [0|1023] ""  CANOE

BO_ 2654552341 ME_SnsDat_Rear_Indirect_2: 8 CVADAS
 SG_ FD14_SnrDat_sRSR_Indir_ROR_cm : 30|10@1+ (1,0) [0|1023] ""  CANOE
 SG_ FD14_SnrDat_sROR_Indir_RSR_cm : 20|10@1+ (1,0) [0|1023] ""  CANOE
 SG_ FD14_SnrDat_sROR_Indir_RIR_cm : 10|10@1+ (1,0) [0|1023] ""  CANOE
 SG_ FD14_SnrDat_sRIR_Indir_ROR_cm : 0|10@1+ (1,0) [0|1023] ""  CANOE

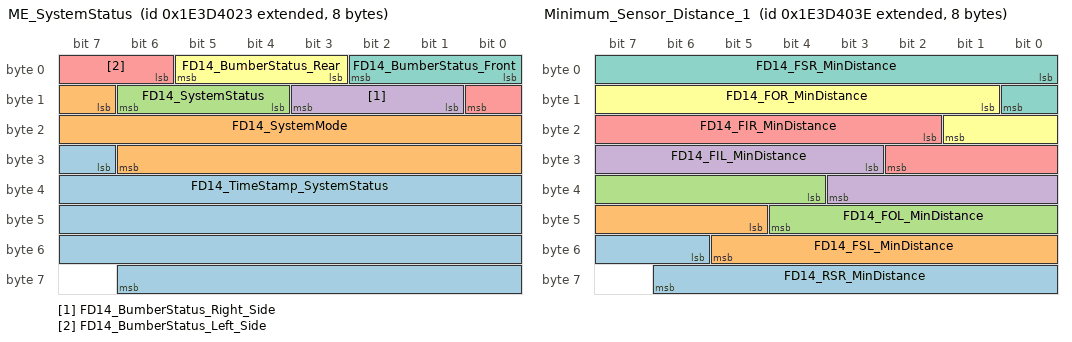
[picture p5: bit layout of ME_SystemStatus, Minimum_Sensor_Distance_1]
BO_ 2654814243 ME_SystemStatus: 8 CVADAS
 SG_ FD14_TimeStamp_SystemStatus : 31|32@1+ (1,0) [0|4294967295] "ms"  CANOE
 SG_ FD14_SystemMode : 15|16@1+ (1,0) [0|65535] ""  CANOE
 SG_ FD14_SystemStatus : 12|3@1+ (1,0) [0|7] ""  CANOE
 SG_ FD14_BumberStatus_Right_Side : 9|3@1+ (1,0) [0|7] ""  CANOE
 SG_ FD14_BumberStatus_Left_Side : 6|3@1+ (1,0) [0|7] ""  CANOE
 SG_ FD14_BumberStatus_Rear : 3|3@1+ (1,0) [0|7] ""  CANOE
 SG_ FD14_BumberStatus_Front : 0|3@1+ (1,0) [0|7] ""  CANOE

BO_ 2654814270 Minimum_Sensor_Distance_1: 8 CVADAS
 SG_ FD14_RSR_MinDistance : 54|9@1+ (1,0) [0|511] "cm"  CANOE
 SG_ FD14_FSL_MinDistance : 45|9@1+ (1,0) [0|511] "cm"  CANOE
 SG_ FD14_FOL_MinDistance : 36|9@1+ (1,0) [0|511] "cm"  CANOE
 SG_ FD14_FIL_MinDistance : 27|9@1+ (1,0) [0|511] "cm"  CANOE
 SG_ FD14_FIR_MinDistance : 18|9@1+ (1,0) [0|511] "cm"  CANOE
 SG_ FD14_FOR_MinDistance : 9|9@1+ (1,0) [0|511] "cm"  CANOE
 SG_ FD14_FSR_MinDistance : 0|9@1+ (1,0) [0|511] "cm"  CANOE

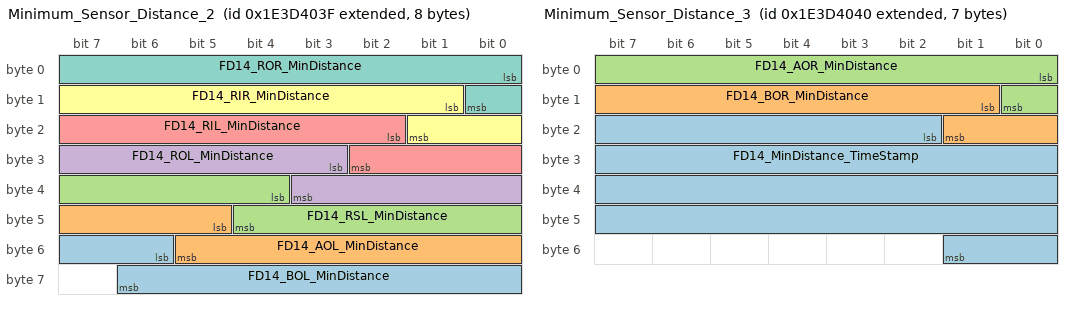
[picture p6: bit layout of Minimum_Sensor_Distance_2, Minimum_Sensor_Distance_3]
BO_ 2654814271 Minimum_Sensor_Distance_2: 8 CVADAS
 SG_ FD14_BOL_MinDistance : 54|9@1+ (1,0) [0|511] "cm"  CANOE
 SG_ FD14_AOL_MinDistance : 45|9@1+ (1,0) [0|511] "cm"  CANOE
 SG_ FD14_RSL_MinDistance : 36|9@1+ (1,0) [0|511] "cm"  CANOE
 SG_ FD14_ROL_MinDistance : 27|9@1+ (1,0) [0|511] "cm"  CANOE
 SG_ FD14_RIL_MinDistance : 18|9@1+ (1,0) [0|511] "cm"  CANOE
 SG_ FD14_RIR_MinDistance : 9|9@1+ (1,0) [0|511] "cm"  CANOE
 SG_ FD14_ROR_MinDistance : 0|9@1+ (1,0) [0|511] "cm"  CANOE

BO_ 2654814272 Minimum_Sensor_Distance_3: 7 CVADAS
 SG_ FD14_MinDistance_TimeStamp : 18|32@1+ (1,0) [0|0] "ms"  CANOE
 SG_ FD14_BOR_MinDistance : 9|9@1+ (1,0) [0|511] "cm"  CANOE
 SG_ FD14_AOR_MinDistance : 0|9@1+ (1,0) [0|511] "cm"  CANOE

BO_ 2654552179 MOT_Obj_0_1: 64 CVADAS
 SG_ FD14_MOT_ObjValid_1 : 385|1@1+ (1,0) [0|1] ""  CANOE
 SG_ FD14_MOT_ObjValid_0 : 384|1@1+ (1,0) [0|1] ""  CANOE
 SG_ FD14_MOT_ObjectDimensions_1_1 : 352|32@1- (0.0001,0) [3.4E-038|3.4E+038] ""  CANOE
 SG_ FD14_MOT_ObjectDimensions_0_1 : 320|32@1- (0.0001,0) [3.4E-038|3.4E+038] ""  CANOE
 SG_ FD14_MOT_ObjVelY_1 : 288|32@1- (0.0001,0) [3.4E-038|3.4E+038] ""  CANOE
 SG_ FD14_MOT_ObjVelX_1 : 256|32@1- (0.0001,0) [3.4E-038|3.4E+038] ""  CANOE
 SG_ FD14_MOT_ClosestPntDist_1_1 : 224|32@1- (0.0001,0) [3.4E-038|3.4E+038] ""  CANOE
 SG_ FD14_MOT_ClosestPntDist_0_1 : 192|32@1- (0.0001,0) [3.4E-038|3.4E+038] ""  CANOE
 SG_ FD14_MOT_ObjectDimensions_1_0 : 160|32@1- (0.0001,0) [3.4E-038|3.4E+038] ""  CANOE
 SG_ FD14_MOT_ObjectDimensions_0_0 : 128|32@1- (0.0001,0) [3.4E-038|3.4E+038] ""  CANOE
 SG_ FD14_MOT_ObjVelY_0 : 96|32@1- (0.0001,0) [3.4E-038|3.4E+038] ""  CANOE
 SG_ FD14_MOT_ObjVelX_0 : 64|32@1- (0.0001,0) [3.4E-038|3.4E+038] ""  CANOE
 SG_ FD14_MOT_ClosestPntDist_1_0 : 32|32@1- (0.0001,0) [3.4E-038|3.4E+038] ""  CANOE
 SG_ FD14_MOT_ClosestPntDist_0_0 : 0|32@1- (0.0001,0) [3.4E-038|3.4E+038] ""  CANOE

BO_ 2654552180 MOT_Obj_2_3: 64 CVADAS
 SG_ FD14_MOT_ObjectDimensions_1_3 : 368|32@1- (0.0001,0) [3.4E-038|3.4E+038] ""  CANOE
 SG_ FD14_MOT_ObjectDimensions_0_3 : 336|32@1- (0.0001,0) [3.4E-038|3.4E+038] ""  CANOE
 SG_ FD14_MOT_ObjVelY_3 : 304|32@1- (0.0001,0) [3.4E-038|3.4E+038] ""  CANOE
 SG_ FD14_MOT_ObjVelX_3 : 272|32@1- (0.0001,0) [3.4E-038|3.4E+038] ""  CANOE
 SG_ FD14_MOT_ClosestPntDist_1_3 : 240|32@1- (0.0001,0) [3.4E-038|3.4E+038] ""  CANOE
 SG_ FD14_MOT_ClosestPntDist_0_3 : 208|32@1- (0.0001,0) [3.4E-038|3.4E+038] ""  CANOE
 SG_ FD14_MOT_ObjectDimensions_1_2 : 176|32@1- (0.0001,0) [3.4E-038|3.4E+038] ""  CANOE
 SG_ FD14_MOT_ObjectDimensions_0_2 : 144|32@1- (0.0001,0) [3.4E-038|3.4E+038] ""  CANOE
 SG_ FD14_MOT_ObjVelY_2 : 112|32@1- (0.0001,0) [3.4E-038|3.4E+038] ""  CANOE
 SG_ FD14_MOT_ObjVelX_2 : 80|32@1- (0.0001,0) [3.4E-038|3.4E+038] ""  CANOE
 SG_ FD14_MOT_ClosestPntDist_1_2 : 48|32@1- (0.0001,0) [3.4E-038|3.4E+038] ""  CANOE
 SG_ FD14_MOT_ClosestPntDist_0_2 : 16|32@1- (0.0001,0) [3.4E-038|3.4E+038] ""  CANOE
 SG_ FD14_MOT_ObjValid_3 : 1|1@1+ (1,0) [0|1] ""  CANOE
 SG_ FD14_MOT_ObjValid_2 : 0|1@1+ (1,0) [0|1] ""  CANOE

BO_ 2654552181 MOT_Obj_4_5: 64 CVADAS
 SG_ FD14_MOT_ObjectDimensions_1_5 : 368|32@1- (0.0001,0) [3.4E-038|3.4E+038] ""  CANOE
 SG_ FD14_MOT_ObjectDimensions_0_5 : 336|32@1- (0.0001,0) [3.4E-038|3.4E+038] ""  CANOE
 SG_ FD14_MOT_ObjVelY_5 : 304|32@1- (0.0001,0) [3.4E-038|3.4E+038] ""  CANOE
 SG_ FD14_MOT_ObjVelX_5 : 272|32@1- (0.0001,0) [3.4E-038|3.4E+038] ""  CANOE
 SG_ FD14_MOT_ClosestPntDist_1_5 : 240|32@1- (0.0001,0) [3.4E-038|3.4E+038] ""  CANOE
 SG_ FD14_MOT_ClosestPntDist_0_5 : 208|32@1- (0.0001,0) [3.4E-038|3.4E+038] ""  CANOE
 SG_ FD14_MOT_ObjectDimensions_1_4 : 176|32@1- (0.0001,0) [3.4E-038|3.4E+038] ""  CANOE
 SG_ FD14_MOT_ObjectDimensions_0_4 : 144|32@1- (0.0001,0) [3.4E-038|3.4E+038] ""  CANOE
 SG_ FD14_MOT_ObjVelY_4 : 112|32@1- (0.0001,0) [3.4E-038|3.4E+038] ""  CANOE
 SG_ FD14_MOT_ObjVelX_4 : 80|32@1- (0.0001,0) [3.4E-038|3.4E+038] ""  CANOE
 SG_ FD14_MOT_ClosestPntDist_1_4 : 48|32@1- (0.0001,0) [3.4E-038|3.4E+038] ""  CANOE
 SG_ FD14_MOT_ClosestPntDist_0_4 : 16|32@1- (0.0001,0) [3.4E-038|3.4E+038] ""  CANOE
 SG_ FD14_MOT_ObjValid_5 : 1|1@1+ (1,0) [0|1] ""  CANOE
 SG_ FD14_MOT_ObjValid_4 : 0|1@1+ (1,0) [0|1] ""  CANOE

BO_ 2654552182 MOT_Obj_6_7: 64 CVADAS
 SG_ FD14_MOT_ObjectDimensions_1_7 : 368|32@1- (0.0001,0) [3.4E-038|3.4E+038] ""  CANOE
 SG_ FD14_MOT_ObjectDimensions_0_7 : 336|32@1- (0.0001,0) [3.4E-038|3.4E+038] ""  CANOE
 SG_ FD14_MOT_ObjVelY_7 : 304|32@1- (0.0001,0) [3.4E-038|3.4E+038] ""  CANOE
 SG_ FD14_MOT_ObjVelX_7 : 272|32@1- (0.0001,0) [3.4E-038|3.4E+038] ""  CANOE
 SG_ FD14_MOT_ClosestPntDist_1_7 : 240|32@1- (0.0001,0) [3.4E-038|3.4E+038] ""  CANOE
 SG_ FD14_MOT_ClosestPntDist_0_7 : 208|32@1- (0.0001,0) [3.4E-038|3.4E+038] ""  CANOE
 SG_ FD14_MOT_ObjectDimensions_1_6 : 176|32@1- (0.0001,0) [3.4E-038|3.4E+038] ""  CANOE
 SG_ FD14_MOT_ObjectDimensions_0_6 : 144|32@1- (0.0001,0) [3.4E-038|3.4E+038] ""  CANOE
 SG_ FD14_MOT_ObjVelY_6 : 112|32@1- (0.0001,0) [3.4E-038|3.4E+038] ""  CANOE
 SG_ FD14_MOT_ObjVelX_6 : 80|32@1- (0.0001,0) [3.4E-038|3.4E+038] ""  CANOE
 SG_ FD14_MOT_ClosestPntDist_1_6 : 48|32@1- (0.0001,0) [3.4E-038|3.4E+038] ""  CANOE
 SG_ FD14_MOT_ClosestPntDist_0_6 : 16|32@1- (0.0001,0) [3.4E-038|3.4E+038] ""  CANOE
 SG_ FD14_MOT_ObjValid_7 : 1|1@1+ (1,0) [0|1] ""  CANOE
 SG_ FD14_MOT_ObjValid_6 : 0|1@1+ (1,0) [0|1] ""  CANOE

BO_ 2654552183 MOT_Obj_8_9: 64 CVADAS
 SG_ FD14_MOT_ObjectDimensions_1_9 : 368|32@1- (0.0001,0) [3.4E-038|3.4E+038] ""  CANOE
 SG_ FD14_MOT_ObjectDimensions_0_9 : 336|32@1- (0.0001,0) [3.4E-038|3.4E+038] ""  CANOE
 SG_ FD14_MOT_ObjVelY_9 : 304|32@1- (0.0001,0) [3.4E-038|3.4E+038] ""  CANOE
 SG_ FD14_MOT_ObjVelX_9 : 272|32@1- (0.0001,0) [3.4E-038|3.4E+038] ""  CANOE
 SG_ FD14_MOT_ClosestPntDist_1_9 : 240|32@1- (0.0001,0) [3.4E-038|3.4E+038] ""  CANOE
 SG_ FD14_MOT_ClosestPntDist_0_9 : 208|32@1- (0.0001,0) [3.4E-038|3.4E+038] ""  CANOE
 SG_ FD14_MOT_ObjectDimensions_1_8 : 176|32@1- (0.0001,0) [3.4E-038|3.4E+038] ""  CANOE
 SG_ FD14_MOT_ObjectDimensions_0_8 : 144|32@1- (0.0001,0) [3.4E-038|3.4E+038] ""  CANOE
 SG_ FD14_MOT_ObjVelY_8 : 112|32@1- (0.0001,0) [3.4E-038|3.4E+038] ""  CANOE
 SG_ FD14_MOT_ObjVelX_8 : 80|32@1- (0.0001,0) [3.4E-038|3.4E+038] ""  CANOE
 SG_ FD14_MOT_ClosestPntDist_1_8 : 48|32@1- (0.0001,0) [3.4E-038|3.4E+038] ""  CANOE
 SG_ FD14_MOT_ClosestPntDist_0_8 : 16|32@1- (0.0001,0) [3.4E-038|3.4E+038] ""  CANOE
 SG_ FD14_MOT_ObjValid_9 : 1|1@1+ (1,0) [0|1] ""  CANOE
 SG_ FD14_MOT_ObjValid_8 : 0|1@1+ (1,0) [0|1] ""  CANOE

BO_ 2654552326 PLDDebugInfo1: 64 CVADAS
 SG_ FD14_stPLDParkingSlot4SlotType : 304|8@1+ (1,0) [0|3] ""  CANOE
 SG_ FD14_stPLDParkingSlot4DataSlotSi : 296|8@1+ (1,0) [0|2] ""  CANOE
 SG_ FD14_stPLDParkingSlot4DataSlotID : 288|8@1+ (1,0) [0|6] ""  CANOE
 SG_ FD14_stPLDParkingSlot4RearRightX : 256|32@1- (1,0) [0|400] ""  CANOE
 SG_ FD14_stPLDParkingSlot4RearRightY : 224|32@1- (1,0) [0|640] ""  CANOE
 SG_ FD14_stPLDParkingSlot4FrontLeftY : 192|32@1- (1,0) [0|640] ""  CANOE
 SG_ FD14_stPLDParkingSlot4FrontLeftX : 160|32@1- (1,0) [0|400] ""  CANOE
 SG_ FD14_stPLDParkingSlot1DataSlotID : 152|8@1+ (1,0) [0|6] ""  CANOE
 SG_ FD14_stPLDParkingSlot1DataSlotSi : 144|8@1+ (1,0) [0|2] ""  CANOE
 SG_ FD14_stPLDParkingSlot1SlotType : 39|8@1+ (1,0) [0|3] ""  CANOE
 SG_ FD14_stPLDParkingSlot1RearRightY : 112|32@1- (1,0) [0|640] ""  CANOE
 SG_ FD14_stPLDParkingSlot1RearRightX : 80|32@1- (1,0) [0|400] ""  CANOE
 SG_ FD14_stPLDParkingSlot1FrontLeftY : 48|32@1- (1,0) [0|640] ""  CANOE
 SG_ FD14_stPLDParkingSlot1FrontLeftX : 7|32@1- (1,0) [0|400] ""  CANOE
 SG_ FD14_stPLDParkingSlot6SlotValid : 6|1@1+ (1,0) [0|1] ""  CANOE
 SG_ FD14_stPLDParkingSlot5SlotValid : 5|1@1+ (1,0) [0|1] ""  CANOE
 SG_ FD14_stPLDParkingSlot3SlotValid : 4|1@1+ (1,0) [0|1] ""  CANOE
 SG_ FD14_stPLDParkingSlot2SlotValid : 3|1@1+ (1,0) [0|1] ""  CANOE
 SG_ FD14_stPLDParkingSlot4SlotValid : 2|1@1+ (1,0) [0|1] ""  CANOE
 SG_ FD14_stPLDParkingSlot1SlotValid : 1|1@1+ (1,0) [0|1] ""  CANOE
 SG_ FD14_isPLDInitSuccess_b : 0|1@1+ (1,0) [0|1] ""  CANOE

BO_ 2654552327 PLDDebugInfo2: 20 CVADAS
 SG_ FD14_stPLDLockedSlotDataSlotVali : 152|1@1+ (1,0) [0|1] ""  CANOE
 SG_ FD14_stPLDLockedSlotDataSlotID : 144|8@1+ (1,0) [0|6] ""  CANOE
 SG_ FD14_stPLDLockedSlotDataSlotSide : 136|8@1+ (1,0) [0|2] ""  CANOE
 SG_ FD14_stPLDLockedSlotDataSlotType : 128|8@1+ (1,0) [0|3] ""  CANOE
 SG_ FD14_stPLDLockedSlotDataRearRigh : 96|32@1- (1,0) [0|640] ""  CANOE
 SG_ FD14_stPLDLockedSlotDataRea_0000 : 64|32@1- (1,0) [0|400] ""  CANOE
 SG_ FD14_stPLDLockedSlotDataFrontLef : 32|32@1- (1,0) [0|640] ""  CANOE
 SG_ FD14_stPLDLockedSlotDataFro_0000 : 0|32@1- (1,0) [0|400] ""  CANOE

BO_ 2654814273 PntDebugData_0: 64 CVADAS
 SG_ FD14_Pntdebugdata_0 : 0|64@1+ (1,0) [0|0] ""  CANOE

BO_ 2654814274 PntDebugData_1: 64 CVADAS
 SG_ FD14_Pntdebugdata_1 : 0|64@1+ (1,0) [0|0] ""  CANOE

BO_ 2654814275 PntDebugData_2: 64 CVADAS
 SG_ FD14_Pntdebugdata_2 : 0|64@1+ (1,0) [0|0] ""  CANOE

BO_ 2654814277 PntDebugData_3: 64 CVADAS
 SG_ FD14_Pntdebugdata_3 : 0|64@1+ (1,0) [0|0] ""  CANOE

BO_ 2654552185 THADebugInfo1: 64 CVADAS
 SG_ FD14_MeTHA_deg_RoadWhlAng : 36|32@1- (0.001,0) [-180|180] ""  CANOE
 SG_ FD14_MeTHA_b_THAAbortStatus : 18|1@1+ (1,0) [0|1] ""  CANOE
 SG_ FD14_MeTHA_b_UsrCplrSelCnfm : 17|1@1+ (1,0) [0|1] ""  CANOE
 SG_ FD14_MeTHA_b_UsrHitchCnfm : 16|1@1+ (1,0) [0|1] ""  CANOE
 SG_ FD14_MeTHA_e_THAStateInfo : 28|8@1+ (1,0) [0|10] ""  CANOE
 SG_ FD14_MeTHA_e_RearBrkSupprInfo : 14|2@1+ (1,0) [0|2] ""  CANOE
 SG_ FD14_MeTHA_e_ScreenRequest : 20|8@1+ (1,0) [0|25] ""  CANOE
 SG_ FD14_MeTHA_b_EnblRearParkAsstTrg : 13|1@1+ (1,0) [0|1] ""  CANOE
 SG_ FD14_MeTHA_b_TrlrCplrStatus : 19|1@1+ (1,0) [0|1] ""  CANOE
 SG_ FD14_IeTHA_e_PamChimeTyp : 5|8@1+ (1,0) [0|15] ""  CANOE
 SG_ FD14_IeTHA_b_ChimeActvRhf : 3|1@1+ (1,0) [0|1] ""  CANOE
 SG_ FD14_IeTHA_b_ChimeActvLhf : 4|1@1+ (1,0) [0|1] ""  CANOE
 SG_ FD14_IeTHA_e_PamVol : 0|3@1+ (1,0) [0|3] ""  CANOE

BO_ 2654552192 THADebugInfo2: 64 CVADAS
 SG_ FD14_MeTHA_px_CplrPntY : 214|32@1- (1,0) [0|1280] ""  CANOE
 SG_ FD14_MeTHA_px_CplrPntX : 182|32@1- (1,0) [0|1920] ""  CANOE
 SG_ FD14_MeTHA_px_HitchPntY : 150|32@1- (1,0) [0|1280] ""  CANOE
 SG_ FD14_MeTHA_px_HitchPntX : 118|32@1- (1,0) [0|1920] ""  CANOE
 SG_ FD14_MeTHA_pct_CplrTrckConf : 110|8@1+ (1,0) [0|100] ""  CANOE
 SG_ FD14_MeTHA_pct_CplrDetConf : 102|8@1+ (1,0) [0|100] ""  CANOE
 SG_ FD14_MeTHA_px_HitchCplrPixDiffLa : 70|32@1- (1,0) [-1920|1920] ""  CANOE
 SG_ FD14_MeTHA_px_HitchCplrPixDiffLo : 38|32@1- (1,0) [-1280|1280] ""  CANOE
 SG_ FD14_MeTHA_deg_CplrAng : 6|32@1- (0.5,0) [0|180] ""  CANOE
 SG_ FD14_MeTHA_e_CplrDetctStatus : 3|3@1+ (1,0) [0|2] ""  CANOE
 SG_ FD14_MeTHA_e_HitchDetctStatus : 0|3@1+ (1,0) [0|2] ""  CANOE

BO_ 2654552151 TRSC_Debug_Message1: 64 CVADAS
 SG_ FD14_ReservedTRSCSig2 : 464|32@1- (1,0) [-3.40282E+038|3.40282347E+038] ""  CANOE
 SG_ FD14_ReservedTRSCSig1 : 432|32@1- (1,0) [-3.40282E+038|3.40282347E+038] ""  CANOE
 SG_ FD14_MeTRSC_cnt_TRSCAliveCounter : 416|16@1+ (1,0) [0|0] "count"  CANOE
 SG_ FD14_MeTRSC_s_TRSCTimeTaken : 400|16@1+ (1,0) [0|0] "msec"  CANOE
 SG_ FD14_MeTRSC_s_TRSCPeriodicity : 384|16@1+ (1,0) [0|0] "msec"  CANOE
 SG_ FD14_IeTRSC_pct_TrlrRecogConf : 349|32@1- (0.1,0) [0|100] "pct"  CANOE
 SG_ FD14_IeTRSC_pct_TrlrTrackConf : 285|32@1- (0.1,0) [0|100] "pct"  CANOE
 SG_ FD14_MeTRSC_m_HitchLength : 0|32@1- (0.01,0) [1000|2500] "mm"  CANOE
 SG_ FD14_IeTRSC_m_TrlrWhlBaseEff : 317|32@1- (0.01,0) [0|15000] "mm"  CANOE
 SG_ FD14_IeTRSC_pct_TrlrDetConf : 253|32@1- (0.1,0) [0|100] "pct"  CANOE
 SG_ FD14_MeTRSC_deg_JackKnifeAngle : 221|32@1- (0.01,0) [-110|110] "deg"  CANOE
 SG_ FD14_MeTRSC_m_TrailerBeamLen : 92|32@1- (0.01,0) [1|20] "m"  CANOE
 SG_ FD14_MeTRSC_e_TrlrAngSign : 76|1@1+ (1,0) [0|2] ""  CANOE
 SG_ FD14_MeTRSC_e_TrlrPrsntInfo : 81|1@1+ (1,0) [0|3] ""  CANOE
 SG_ FD14_MeTRSC_e_TrlrRecogInfo : 75|1@1+ (1,0) [0|1] ""  CANOE
 SG_ FD14_MeTRSC_e_TrlrCalInfo : 80|1@1+ (1,0) [0|1] ""  CANOE
 SG_ FD14_MeSVS_b_MoreCamReqSts : 220|1@1+ (1,0) [0|1] ""  CANOE
 SG_ FD14_MeTRSC_deg_JackknifeThrAngl : 188|32@1- (0.1,0) [-110|110] "deg"  CANOE
 SG_ FD14_MeTRSC_deg_TADAngleRate : 156|32@1- (0.1,0) [-110|110] "deg/sec"  CANOE
 SG_ FD14_MeTRSC_deg_MaxAllowedTADAng : 124|32@1- (0.1,0) [-110|110] "deg"  CANOE
 SG_ FD14_MeTRSC_e_TrailerID : 85|7@1+ (1,0) [0|6] ""  CANOE
 SG_ FD14_MeTRSC_e_CalFail : 82|3@1+ (1,0) [0|2] ""  CANOE
 SG_ FD14_MeTRSC_e_TADCalibrationSubs : 72|3@1+ (1,0) [0|2] ""  CANOE
 SG_ FD14_MeTRSC_e_TurnAroundSubState : 77|3@1+ (1,0) [0|2] ""  CANOE
 SG_ FD14_MeTRSC_e_TADState : 64|8@1+ (1,0) [0|7] ""  CANOE
 SG_ FD14_MeTRSC_deg_TADAngle : 32|32@1- (0.01,0) [-110|110] "deg"  CANOE

BO_ 2654552165 TRSC_Debug_Message2: 64 CVADAS
 SG_ FD14_IeTRSC_e_TRSCAbortReas : 400|22@1+ (1,0) [0|21] ""  CANOE
 SG_ FD14_MeTRSC_e_TRSCStat : 384|8@1+ (1,0) [0|21] ""  CANOE
 SG_ FD14_IeTRSC_e_TrlrAngGrapOverSts : 352|22@1+ (1,0) [0|21] ""  CANOE
 SG_ FD14_IeTRSC_e_TRSCUnavailReas : 320|21@1+ (1,0) [0|20] ""  CANOE
 SG_ FD14_IeTRSC_e_CamBlockSts : 188|4@1+ (1,0) [0|3] ""  CANOE
 SG_ FD14_IeTRSC_kph_VehSpeedVSOSig : 288|32@1- (0.01,0) [-90|90] "deg"  CANOE
 SG_ FD14_IeTRSC_M_TRSCStrTrq : 256|32@1- (0.01,0) [-90|90] "deg"  CANOE
 SG_ FD14_IeTRSC_deg_JackknifeThrAngl : 224|32@1- (0.01,0) [-90|90] "deg"  CANOE
 SG_ FD14_IeTRSC_deg_TADAngle : 192|32@1- (0.01,0) [-90|90] "deg"  CANOE
 SG_ FD14_IeTRSC_deg_TrlrAngKnob : 156|32@1- (0.01,0) [-90|90] "deg"  CANOE
 SG_ FD14_IeTRSC_e_TrlrRecogInfo : 152|4@1+ (1,0) [0|3] ""  CANOE
 SG_ FD14_IeTRSC_e_TRSKMSts : 148|3@1+ (1,0) [0|2] ""  CANOE
 SG_ FD14_IeTRSC_e_TRSKMCenBtnSts : 144|4@1+ (1,0) [0|3] ""  CANOE
 SG_ FD14_IeTRSC_e_TRSKMBtnSts : 91|4@1+ (1,0) [0|3] ""  CANOE
 SG_ FD14_IeTRSC_e_TrailerID : 136|6@1+ (1,0) [0|5] ""  CANOE
 SG_ FD14_IeTRSC_e_GearShiftSts : 128|8@1+ (1,0) [0|7] ""  CANOE
 SG_ FD14_IeTRSC_deg_FrntWhlAng : 96|32@1- (0.1,0) [-40|40] "deg"  CANOE
 SG_ FD14_IeTRSC_e_TrlrPrsntSts : 88|3@1+ (1,0) [0|2] ""  CANOE
 SG_ FD14_IeTRSC_e_TrlrPrsntFailReas : 84|3@1+ (1,0) [0|2] ""  CANOE
 SG_ FD14_IeTRSC_e_TrlrCalibSts : 13|3@1+ (1,0) [0|2] ""  CANOE
 SG_ FD14_IeTRSC_e_TrlrCalibManState : 80|4@1+ (1,0) [0|3] ""  CANOE
 SG_ FD14_IeTRSC_e_TrlrCalibFailReas : 8|5@1+ (1,0) [0|4] ""  CANOE
 SG_ FD14_IeTRSC_cnt_TrlrCalibPa_0000 : 64|16@1+ (1,0) [0|65535] "count"  CANOE
 SG_ FD14_IeTRSC_cnt_TrlrCalibPassCnt : 48|16@1+ (1,0) [0|65535] "count"  CANOE
 SG_ FD14_IeTRSC_cnt_TrlrCalibFa_0000 : 32|16@1+ (1,0) [0|65535] "count"  CANOE
 SG_ FD14_IeTRSC_cnt_TrlrCalibFailCnt : 16|16@1+ (1,0) [0|65535] "count"  CANOE
 SG_ FD14_IeTRSC_cnt_KnobPos : 0|8@1+ (1,0) [0|255] "count"  CANOE

CM_ SG_ 2654552193 FD14_cntrCvpamFdData1_u16 "To analyze distance between ego vehicle(front axle) and detected vehicle";
CM_ SG_ 2654552193 FD14_crcCvpamFdData1_u8 "To analyze distance between ego vehicle(front axle) and detected vehicle";
CM_ SG_ 2654552193 FD14_msgcntrCvpamFdData1_u8 "To analyze distance between ego vehicle(front axle) and detected vehicle";
CM_ SG_ 2654552193 FD14_macCvpamFdData1_u64 "To analyze distance between ego vehicle(front axle) and detected vehicle";
CM_ SG_ 2654552193 FD14_obj_Pos_Longi "To analyze distance between ego vehicle(front axle) and detected vehicle";
CM_ SG_ 2654552193 FD14_obj_Pos_Lat "To analyze angle between ego vehicle(front axle) and detected vehicle";
CM_ SG_ 2654552151 FD14_IeTRSC_pct_TrlrTrackConf "DID value of Trailer tracking confidence";
BA_DEF_ SG_  "GenSigStartValue" INT 0 2147483647;
BA_DEF_ SG_  "GenSigInactiveValue" INT 0 2147483647;
BA_DEF_ SG_  "GenSigSendType" ENUM  "NotUsed","OnWrite","OnWriteWithRepetition","OnChange","OnChangeWithRepetition","IfActive","IfActiveWithRepetition","NoSigSendType";
BA_DEF_ SG_  "GenSigTimeoutTime_BSM" INT 0 65535;
BA_DEF_ SG_  "GenSigTimeoutTime_BSM2" INT 0 65535;
BA_DEF_ SG_  "GenSigTimeoutTime_CADM" INT 0 65535;
BA_DEF_ SG_  "GenSigTimeoutTime_CVADAS" INT 0 65535;
BA_DEF_ SG_  "GenSigTimeoutTime_ECM" INT 0 65535;
BA_DEF_ SG_  "GenSigTimeoutTime_EPS" INT 0 65535;
BA_DEF_ SG_  "GenSigTimeoutTime_EVCU2" INT 0 65535;
BA_DEF_ SG_  "GenSigTimeoutTime_ORC" INT 0 65535;
BA_DEF_ BO_  "DiagRequest" ENUM  "No","Yes";
BA_DEF_ BO_  "Type" ENUM  "P","C","PE","COC","PE_Cntrl","E","E_Cntrl","OC","S","BAF","DC","EM","MM","ISO-TP","-";
BA_DEF_ BO_  "DiagResponse" ENUM  "No","Yes";
BA_DEF_ BO_  "NmMessage" ENUM  "No","Yes";
BA_DEF_ BO_  "GenMsgSendType" ENUM  "Cyclic","NotUsed","NotUsed","NotUsed","NotUsed","NotUsed","NotUsed","NotUsed","NoMsgSendType";
BA_DEF_ BO_  "GenMsgNrOfRepetition" INT 0 255;
BA_DEF_ BO_  "GenMsgILSupport" ENUM  "No","Yes";
BA_DEF_ BO_  "GenMsgCycleTimeFast" INT 0 65535;
BA_DEF_ BO_  "GenMsgCycleTime" INT 0 65535;
BA_DEF_ BO_  "GenMsgDelayTime" INT 0 65535;
BA_DEF_ BO_  "NmAsrMessage" ENUM  "No","Yes";
BA_DEF_ BO_  "DiagState" ENUM  "No","Yes";
BA_DEF_ BO_  "DiagConnection" HEX 0 65535;
BA_DEF_ BO_  "VFrameFormat" ENUM  "StandardCAN","ExtendedCAN","reserved","reserved","reserved","reserved","reserved","reserved","reserved","reserved","reserved","reserved","reserved","reserved","StandardCAN_FD","ExtendedCAN_FD";
BA_DEF_ BO_  "CANFD_BRS" ENUM  "No","Yes";
BA_DEF_ SG_  "SystemSignalLongSymbol" STRING ;
BA_DEF_DEF_  "GenSigStartValue" 0;
BA_DEF_DEF_  "GenSigInactiveValue" 0;
BA_DEF_DEF_  "GenSigSendType" "NoSigSendType";
BA_DEF_DEF_  "GenSigTimeoutTime_BSM" 2500;
BA_DEF_DEF_  "GenSigTimeoutTime_BSM2" 2500;
BA_DEF_DEF_  "GenSigTimeoutTime_CADM" 2500;
BA_DEF_DEF_  "GenSigTimeoutTime_CVADAS" 2500;
BA_DEF_DEF_  "GenSigTimeoutTime_ECM" 2500;
BA_DEF_DEF_  "GenSigTimeoutTime_EPS" 2500;
BA_DEF_DEF_  "GenSigTimeoutTime_EVCU2" 2500;
BA_DEF_DEF_  "GenSigTimeoutTime_ORC" 2500;
BA_DEF_DEF_  "DiagRequest" "No";
BA_DEF_DEF_  "Type" "-";
BA_DEF_DEF_  "DiagResponse" "No";
BA_DEF_DEF_  "NmMessage" "No";
BA_DEF_DEF_  "GenMsgSendType" "NoMsgSendType";
BA_DEF_DEF_  "GenMsgNrOfRepetition" 0;
BA_DEF_DEF_  "GenMsgILSupport" "No";
BA_DEF_DEF_  "GenMsgCycleTimeFast" 0;
BA_DEF_DEF_  "GenMsgCycleTime" 0;
BA_DEF_DEF_  "GenMsgDelayTime" 0;
BA_DEF_DEF_  "NmAsrMessage" "No";
BA_DEF_DEF_  "DiagState" "No";
BA_DEF_DEF_  "DiagConnection" 0;
BA_DEF_DEF_  "VFrameFormat" "StandardCAN_FD";
BA_DEF_DEF_  "CANFD_BRS" "No";
BA_DEF_DEF_  "SystemSignalLongSymbol" "";
BA_ "CANFD_BRS" BO_ 2654552208 1;
BA_ "GenMsgILSupport" BO_ 2654552208 1;
BA_ "VFrameFormat" BO_ 2654552208 15;
BA_ "CANFD_BRS" BO_ 2654552209 1;
BA_ "GenMsgILSupport" BO_ 2654552209 1;
BA_ "VFrameFormat" BO_ 2654552209 15;
BA_ "CANFD_BRS" BO_ 2654552210 1;
BA_ "GenMsgILSupport" BO_ 2654552210 1;
BA_ "VFrameFormat" BO_ 2654552210 15;
BA_ "CANFD_BRS" BO_ 2654552211 1;
BA_ "GenMsgILSupport" BO_ 2654552211 1;
BA_ "VFrameFormat" BO_ 2654552211 15;
BA_ "CANFD_BRS" BO_ 2654552212 1;
BA_ "GenMsgILSupport" BO_ 2654552212 1;
BA_ "VFrameFormat" BO_ 2654552212 15;
BA_ "CANFD_BRS" BO_ 2654552213 1;
BA_ "GenMsgILSupport" BO_ 2654552213 1;
BA_ "VFrameFormat" BO_ 2654552213 15;
BA_ "CANFD_BRS" BO_ 2654552214 1;
BA_ "GenMsgILSupport" BO_ 2654552214 1;
BA_ "VFrameFormat" BO_ 2654552214 15;
BA_ "CANFD_BRS" BO_ 2654552215 1;
BA_ "GenMsgILSupport" BO_ 2654552215 1;
BA_ "VFrameFormat" BO_ 2654552215 15;
BA_ "CANFD_BRS" BO_ 2654552193 1;
BA_ "GenMsgILSupport" BO_ 2654552193 1;
BA_ "VFrameFormat" BO_ 2654552193 15;
BA_ "CANFD_BRS" BO_ 2654814256 1;
BA_ "GenMsgCycleTime" BO_ 2654814256 40;
BA_ "GenMsgILSupport" BO_ 2654814256 1;
BA_ "GenMsgSendType" BO_ 2654814256 0;
BA_ "VFrameFormat" BO_ 2654814256 15;
BA_ "CANFD_BRS" BO_ 2654814248 1;
BA_ "GenMsgCycleTime" BO_ 2654814248 40;
BA_ "GenMsgILSupport" BO_ 2654814248 1;
BA_ "GenMsgSendType" BO_ 2654814248 0;
BA_ "VFrameFormat" BO_ 2654814248 15;
BA_ "CANFD_BRS" BO_ 2654814249 1;
BA_ "GenMsgCycleTime" BO_ 2654814249 40;
BA_ "GenMsgILSupport" BO_ 2654814249 1;
BA_ "GenMsgSendType" BO_ 2654814249 0;
BA_ "VFrameFormat" BO_ 2654814249 15;
BA_ "CANFD_BRS" BO_ 2654552336 1;
BA_ "GenMsgILSupport" BO_ 2654552336 1;
BA_ "VFrameFormat" BO_ 2654552336 15;
BA_ "CANFD_BRS" BO_ 2654552145 1;
BA_ "GenMsgILSupport" BO_ 2654552145 1;
BA_ "VFrameFormat" BO_ 2654552145 15;
BA_ "CANFD_BRS" BO_ 2654552147 1;
BA_ "GenMsgILSupport" BO_ 2654552147 1;
BA_ "VFrameFormat" BO_ 2654552147 15;
BA_ "CANFD_BRS" BO_ 2654552144 1;
BA_ "GenMsgILSupport" BO_ 2654552144 1;
BA_ "VFrameFormat" BO_ 2654552144 15;
BA_ "CANFD_BRS" BO_ 2654552146 1;
BA_ "GenMsgILSupport" BO_ 2654552146 1;
BA_ "VFrameFormat" BO_ 2654552146 15;
BA_ "CANFD_BRS" BO_ 2654552184 1;
BA_ "GenMsgILSupport" BO_ 2654552184 1;
BA_ "VFrameFormat" BO_ 2654552184 15;
BA_ "CANFD_BRS" BO_ 2654552321 1;
BA_ "GenMsgILSupport" BO_ 2654552321 1;
BA_ "VFrameFormat" BO_ 2654552321 15;
BA_ "CANFD_BRS" BO_ 2654552322 1;
BA_ "GenMsgILSupport" BO_ 2654552322 1;
BA_ "VFrameFormat" BO_ 2654552322 15;
BA_ "CANFD_BRS" BO_ 2654552323 1;
BA_ "GenMsgILSupport" BO_ 2654552323 1;
BA_ "VFrameFormat" BO_ 2654552323 15;
BA_ "CANFD_BRS" BO_ 2654552324 1;
BA_ "GenMsgILSupport" BO_ 2654552324 1;
BA_ "VFrameFormat" BO_ 2654552324 15;
BA_ "CANFD_BRS" BO_ 2654552325 1;
BA_ "GenMsgILSupport" BO_ 2654552325 1;
BA_ "VFrameFormat" BO_ 2654552325 15;
BA_ "CANFD_BRS" BO_ 2654814230 1;
BA_ "GenMsgSendType" BO_ 2654814230 0;
BA_ "GenMsgILSupport" BO_ 2654814230 1;
BA_ "GenMsgCycleTime" BO_ 2654814230 40;
BA_ "VFrameFormat" BO_ 2654814230 15;
BA_ "CANFD_BRS" BO_ 2654814231 1;
BA_ "GenMsgSendType" BO_ 2654814231 0;
BA_ "GenMsgILSupport" BO_ 2654814231 1;
BA_ "GenMsgCycleTime" BO_ 2654814231 40;
BA_ "VFrameFormat" BO_ 2654814231 15;
BA_ "CANFD_BRS" BO_ 2654814247 1;
BA_ "GenMsgSendType" BO_ 2654814247 0;
BA_ "GenMsgILSupport" BO_ 2654814247 1;
BA_ "GenMsgCycleTime" BO_ 2654814247 40;
BA_ "VFrameFormat" BO_ 2654814247 15;
BA_ "CANFD_BRS" BO_ 2654814233 1;
BA_ "GenMsgSendType" BO_ 2654814233 0;
BA_ "GenMsgILSupport" BO_ 2654814233 1;
BA_ "GenMsgCycleTime" BO_ 2654814233 40;
BA_ "VFrameFormat" BO_ 2654814233 15;
BA_ "CANFD_BRS" BO_ 2654814234 1;
BA_ "GenMsgSendType" BO_ 2654814234 0;
BA_ "GenMsgILSupport" BO_ 2654814234 1;
BA_ "GenMsgCycleTime" BO_ 2654814234 40;
BA_ "VFrameFormat" BO_ 2654814234 15;
BA_ "CANFD_BRS" BO_ 2654814235 1;
BA_ "GenMsgSendType" BO_ 2654814235 0;
BA_ "GenMsgILSupport" BO_ 2654814235 1;
BA_ "GenMsgCycleTime" BO_ 2654814235 40;
BA_ "VFrameFormat" BO_ 2654814235 15;
BA_ "CANFD_BRS" BO_ 2654814236 1;
BA_ "GenMsgSendType" BO_ 2654814236 0;
BA_ "GenMsgILSupport" BO_ 2654814236 1;
BA_ "GenMsgCycleTime" BO_ 2654814236 40;
BA_ "VFrameFormat" BO_ 2654814236 15;
BA_ "CANFD_BRS" BO_ 2654814237 1;
BA_ "GenMsgILSupport" BO_ 2654814237 1;
BA_ "VFrameFormat" BO_ 2654814237 15;
BA_ "CANFD_BRS" BO_ 2654552337 1;
BA_ "GenMsgILSupport" BO_ 2654552337 1;
BA_ "VFrameFormat" BO_ 2654552337 15;
BA_ "CANFD_BRS" BO_ 2654552338 1;
BA_ "GenMsgILSupport" BO_ 2654552338 1;
BA_ "VFrameFormat" BO_ 2654552338 15;
BA_ "CANFD_BRS" BO_ 2654552339 1;
BA_ "GenMsgILSupport" BO_ 2654552339 1;
BA_ "VFrameFormat" BO_ 2654552339 15;
BA_ "CANFD_BRS" BO_ 2654814238 1;
BA_ "GenMsgILSupport" BO_ 2654814238 1;
BA_ "VFrameFormat" BO_ 2654814238 15;
BA_ "CANFD_BRS" BO_ 2654814240 1;
BA_ "GenMsgILSupport" BO_ 2654814240 1;
BA_ "VFrameFormat" BO_ 2654814240 15;
BA_ "CANFD_BRS" BO_ 2654552352 1;
BA_ "GenMsgILSupport" BO_ 2654552352 1;
BA_ "VFrameFormat" BO_ 2654552352 15;
BA_ "CANFD_BRS" BO_ 2654552344 1;
BA_ "GenMsgILSupport" BO_ 2654552344 1;
BA_ "VFrameFormat" BO_ 2654552344 15;
BA_ "CANFD_BRS" BO_ 2654552342 1;
BA_ "GenMsgILSupport" BO_ 2654552342 1;
BA_ "VFrameFormat" BO_ 2654552342 15;
BA_ "CANFD_BRS" BO_ 2654552340 1;
BA_ "GenMsgILSupport" BO_ 2654552340 1;
BA_ "VFrameFormat" BO_ 2654552340 15;
BA_ "CANFD_BRS" BO_ 2654552353 1;
BA_ "GenMsgILSupport" BO_ 2654552353 1;
BA_ "VFrameFormat" BO_ 2654552353 15;
BA_ "CANFD_BRS" BO_ 2654552345 1;
BA_ "GenMsgILSupport" BO_ 2654552345 1;
BA_ "VFrameFormat" BO_ 2654552345 15;
BA_ "CANFD_BRS" BO_ 2654552343 1;
BA_ "GenMsgILSupport" BO_ 2654552343 1;
BA_ "VFrameFormat" BO_ 2654552343 15;
BA_ "CANFD_BRS" BO_ 2654552341 1;
BA_ "GenMsgILSupport" BO_ 2654552341 1;
BA_ "VFrameFormat" BO_ 2654552341 15;
BA_ "CANFD_BRS" BO_ 2654814243 1;
BA_ "GenMsgILSupport" BO_ 2654814243 1;
BA_ "VFrameFormat" BO_ 2654814243 15;
BA_ "CANFD_BRS" BO_ 2654814270 1;
BA_ "GenMsgILSupport" BO_ 2654814270 1;
BA_ "VFrameFormat" BO_ 2654814270 15;
BA_ "CANFD_BRS" BO_ 2654814271 1;
BA_ "GenMsgILSupport" BO_ 2654814271 1;
BA_ "VFrameFormat" BO_ 2654814271 15;
BA_ "CANFD_BRS" BO_ 2654814272 1;
BA_ "GenMsgILSupport" BO_ 2654814272 1;
BA_ "VFrameFormat" BO_ 2654814272 15;
BA_ "CANFD_BRS" BO_ 2654552179 1;
BA_ "GenMsgILSupport" BO_ 2654552179 1;
BA_ "VFrameFormat" BO_ 2654552179 15;
BA_ "CANFD_BRS" BO_ 2654552180 1;
BA_ "GenMsgILSupport" BO_ 2654552180 1;
BA_ "VFrameFormat" BO_ 2654552180 15;
BA_ "CANFD_BRS" BO_ 2654552181 1;
BA_ "GenMsgILSupport" BO_ 2654552181 1;
BA_ "VFrameFormat" BO_ 2654552181 15;
BA_ "CANFD_BRS" BO_ 2654552182 1;
BA_ "GenMsgILSupport" BO_ 2654552182 1;
BA_ "VFrameFormat" BO_ 2654552182 15;
BA_ "CANFD_BRS" BO_ 2654552183 1;
BA_ "GenMsgILSupport" BO_ 2654552183 1;
BA_ "VFrameFormat" BO_ 2654552183 15;
BA_ "CANFD_BRS" BO_ 2654552326 1;
BA_ "GenMsgILSupport" BO_ 2654552326 1;
BA_ "VFrameFormat" BO_ 2654552326 15;
BA_ "CANFD_BRS" BO_ 2654552327 1;
BA_ "GenMsgILSupport" BO_ 2654552327 1;
BA_ "VFrameFormat" BO_ 2654552327 15;
BA_ "CANFD_BRS" BO_ 2654814273 1;
BA_ "GenMsgILSupport" BO_ 2654814273 1;
BA_ "VFrameFormat" BO_ 2654814273 15;
BA_ "CANFD_BRS" BO_ 2654814274 1;
BA_ "GenMsgILSupport" BO_ 2654814274 1;
BA_ "VFrameFormat" BO_ 2654814274 15;
BA_ "CANFD_BRS" BO_ 2654814275 1;
BA_ "GenMsgILSupport" BO_ 2654814275 1;
BA_ "VFrameFormat" BO_ 2654814275 15;
BA_ "CANFD_BRS" BO_ 2654814277 1;
BA_ "GenMsgILSupport" BO_ 2654814277 1;
BA_ "VFrameFormat" BO_ 2654814277 15;
BA_ "CANFD_BRS" BO_ 2654552185 1;
BA_ "GenMsgILSupport" BO_ 2654552185 1;
BA_ "VFrameFormat" BO_ 2654552185 15;
BA_ "CANFD_BRS" BO_ 2654552192 1;
BA_ "GenMsgILSupport" BO_ 2654552192 1;
BA_ "VFrameFormat" BO_ 2654552192 15;
BA_ "CANFD_BRS" BO_ 2654552151 1;
BA_ "GenMsgILSupport" BO_ 2654552151 1;
BA_ "GenMsgSendType" BO_ 2654552151 0;
BA_ "GenMsgCycleTime" BO_ 2654552151 1000;
BA_ "VFrameFormat" BO_ 2654552151 15;
BA_ "CANFD_BRS" BO_ 2654552165 1;
BA_ "GenMsgILSupport" BO_ 2654552165 1;
BA_ "GenMsgSendType" BO_ 2654552165 0;
BA_ "GenMsgCycleTime" BO_ 2654552165 1000;
BA_ "VFrameFormat" BO_ 2654552165 15;
BA_ "GenSigSendType" SG_ 2654552208 FD14_Point_Map_Cruising_Age_63 1;
BA_ "GenSigSendType" SG_ 2654552208 FD14_Point_Map_Cruising_Age_62 1;
BA_ "GenSigSendType" SG_ 2654552208 FD14_Point_Map_Cruising_Age_61 1;
BA_ "GenSigSendType" SG_ 2654552208 FD14_Point_Map_Cruising_Age_60 1;
BA_ "GenSigSendType" SG_ 2654552208 FD14_Point_Map_Cruising_Age_59 1;
BA_ "GenSigSendType" SG_ 2654552208 FD14_Point_Map_Cruising_Age_58 1;
BA_ "GenSigSendType" SG_ 2654552208 FD14_Point_Map_Cruising_Age_57 1;
BA_ "GenSigSendType" SG_ 2654552208 FD14_Point_Map_Cruising_Age_56 1;
BA_ "GenSigSendType" SG_ 2654552208 FD14_Point_Map_Reserved_62 1;
BA_ "GenSigSendType" SG_ 2654552208 FD14_Point_Map_Age_62 1;
BA_ "GenSigSendType" SG_ 2654552208 FD14_Point_Map_Confidence_62 1;
BA_ "GenSigSendType" SG_ 2654552208 FD14_Point_Map_Height_62 1;
BA_ "GenSigSendType" SG_ 2654552208 FD14_Point_Map_Y_62 1;
BA_ "GenSigSendType" SG_ 2654552208 FD14_Point_Map_X_62 1;
BA_ "GenSigSendType" SG_ 2654552208 FD14_Point_Map_Reserved_61 1;
BA_ "GenSigSendType" SG_ 2654552208 FD14_Point_Map_Age_61 1;
BA_ "GenSigSendType" SG_ 2654552208 FD14_Point_Map_Confidence_61 1;
BA_ "GenSigSendType" SG_ 2654552208 FD14_Point_Map_Height_61 1;
BA_ "GenSigSendType" SG_ 2654552208 FD14_Point_Map_Y_61 1;
BA_ "GenSigSendType" SG_ 2654552208 FD14_Point_Map_X_61 1;
BA_ "GenSigSendType" SG_ 2654552208 FD14_Point_Map_Reserved_60 1;
BA_ "GenSigSendType" SG_ 2654552208 FD14_Point_Map_Confidence_60 1;
BA_ "GenSigSendType" SG_ 2654552208 FD14_Point_Map_Height_60 1;
BA_ "GenSigSendType" SG_ 2654552208 FD14_Point_Map_Age_60 1;
BA_ "GenSigSendType" SG_ 2654552208 FD14_Point_Map_Y_60 1;
BA_ "GenSigSendType" SG_ 2654552208 FD14_Point_Map_X_60 1;
BA_ "GenSigSendType" SG_ 2654552208 FD14_Point_Map_Reserved_59 1;
BA_ "GenSigSendType" SG_ 2654552208 FD14_Point_Map_Age_59 1;
BA_ "GenSigSendType" SG_ 2654552208 FD14_Point_Map_Confidence_59 1;
BA_ "GenSigSendType" SG_ 2654552208 FD14_Point_Map_Height_59 1;
BA_ "GenSigSendType" SG_ 2654552208 FD14_Point_Map_Y_59 1;
BA_ "GenSigSendType" SG_ 2654552208 FD14_Point_Map_X_59 1;
BA_ "GenSigSendType" SG_ 2654552208 FD14_Point_Map_Reserved_58 1;
BA_ "GenSigSendType" SG_ 2654552208 FD14_Point_Map_Age_58 1;
BA_ "GenSigSendType" SG_ 2654552208 FD14_Point_Map_Confidence_58 1;
BA_ "GenSigSendType" SG_ 2654552208 FD14_Point_Map_Height_58 1;
BA_ "GenSigSendType" SG_ 2654552208 FD14_Point_Map_Y_58 1;
BA_ "GenSigSendType" SG_ 2654552208 FD14_Point_Map_X_58 1;
BA_ "GenSigSendType" SG_ 2654552208 FD14_Point_Map_Reserved_57 1;
BA_ "GenSigSendType" SG_ 2654552208 FD14_Point_Map_Age_57 1;
BA_ "GenSigSendType" SG_ 2654552208 FD14_Point_Map_Confidence_57 1;
BA_ "GenSigSendType" SG_ 2654552208 FD14_Point_Map_Height_57 1;
BA_ "GenSigSendType" SG_ 2654552208 FD14_Point_Map_Y_57 1;
BA_ "GenSigSendType" SG_ 2654552208 FD14_Point_Map_X_57 1;
BA_ "GenSigSendType" SG_ 2654552208 FD14_Point_Map_Reserved_56 1;
BA_ "GenSigSendType" SG_ 2654552208 FD14_Point_Map_Age_56 1;
BA_ "GenSigSendType" SG_ 2654552208 FD14_Point_Map_Confidence_56 1;
BA_ "GenSigSendType" SG_ 2654552208 FD14_Point_Map_Height_56 1;
BA_ "GenSigSendType" SG_ 2654552208 FD14_Point_Map_Y_56 1;
BA_ "GenSigSendType" SG_ 2654552208 FD14_Point_Map_X_56 1;
BA_ "GenSigSendType" SG_ 2654552208 FD14_Point_Map_Reserved_63 1;
BA_ "GenSigSendType" SG_ 2654552208 FD14_Point_Map_Age_63 1;
BA_ "GenSigSendType" SG_ 2654552208 FD14_Point_Map_Confidence_63 1;
BA_ "GenSigSendType" SG_ 2654552208 FD14_Point_Map_Height_63 1;
BA_ "GenSigSendType" SG_ 2654552208 FD14_Point_Map_Y_63 1;
BA_ "GenSigSendType" SG_ 2654552208 FD14_Point_Map_X_63 1;
BA_ "GenSigSendType" SG_ 2654552209 FD14_Point_Map_Cruising_Age_71 1;
BA_ "GenSigSendType" SG_ 2654552209 FD14_Point_Map_Cruising_Age_70 1;
BA_ "GenSigSendType" SG_ 2654552209 FD14_Point_Map_Cruising_Age_69 1;
BA_ "GenSigSendType" SG_ 2654552209 FD14_Point_Map_Cruising_Age_68 1;
BA_ "GenSigSendType" SG_ 2654552209 FD14_Point_Map_Cruising_Age_67 1;
BA_ "GenSigSendType" SG_ 2654552209 FD14_Point_Map_Cruising_Age_66 1;
BA_ "GenSigSendType" SG_ 2654552209 FD14_Point_Map_Cruising_Age_65 1;
BA_ "GenSigSendType" SG_ 2654552209 FD14_Point_Map_Cruising_Age_64 1;
BA_ "GenSigSendType" SG_ 2654552209 FD14_Point_Map_Reserved_71 1;
BA_ "GenSigSendType" SG_ 2654552209 FD14_Point_Map_Height_71 1;
BA_ "GenSigSendType" SG_ 2654552209 FD14_Point_Map_Age_71 1;
BA_ "GenSigSendType" SG_ 2654552209 FD14_Point_Map_Confidence_71 1;
BA_ "GenSigSendType" SG_ 2654552209 FD14_Point_Map_Y_71 1;
BA_ "GenSigSendType" SG_ 2654552209 FD14_Point_Map_X_71 1;
BA_ "GenSigSendType" SG_ 2654552209 FD14_Point_Map_Reserved_70 1;
BA_ "GenSigSendType" SG_ 2654552209 FD14_Point_Map_Age_70 1;
BA_ "GenSigSendType" SG_ 2654552209 FD14_Point_Map_Confidence_70 1;
BA_ "GenSigSendType" SG_ 2654552209 FD14_Point_Map_Height_70 1;
BA_ "GenSigSendType" SG_ 2654552209 FD14_Point_Map_Y_70 1;
BA_ "GenSigSendType" SG_ 2654552209 FD14_Point_Map_X_70 1;
BA_ "GenSigSendType" SG_ 2654552209 FD14_Point_Map_Reserved_69 1;
BA_ "GenSigSendType" SG_ 2654552209 FD14_Point_Map_Age_69 1;
BA_ "GenSigSendType" SG_ 2654552209 FD14_Point_Map_Confidence_69 1;
BA_ "GenSigSendType" SG_ 2654552209 FD14_Point_Map_Height_69 1;
BA_ "GenSigSendType" SG_ 2654552209 FD14_Point_Map_Y_69 1;
BA_ "GenSigSendType" SG_ 2654552209 FD14_Point_Map_X_69 1;
BA_ "GenSigSendType" SG_ 2654552209 FD14_Point_Map_Reserved_68 1;
BA_ "GenSigSendType" SG_ 2654552209 FD14_Point_Map_Age_68 1;
BA_ "GenSigSendType" SG_ 2654552209 FD14_Point_Map_Confidence_68 1;
BA_ "GenSigSendType" SG_ 2654552209 FD14_Point_Map_Height_68 1;
BA_ "GenSigSendType" SG_ 2654552209 FD14_Point_Map_Y_68 1;
BA_ "GenSigSendType" SG_ 2654552209 FD14_Point_Map_X_68 1;
BA_ "GenSigSendType" SG_ 2654552209 FD14_Point_Map_Reserved_67 1;
BA_ "GenSigSendType" SG_ 2654552209 FD14_Point_Map_Age_67 1;
BA_ "GenSigSendType" SG_ 2654552209 FD14_Point_Map_Confidence_67 1;
BA_ "GenSigSendType" SG_ 2654552209 FD14_Point_Map_Height_67 1;
BA_ "GenSigSendType" SG_ 2654552209 FD14_Point_Map_Y_67 1;
BA_ "GenSigSendType" SG_ 2654552209 FD14_Point_Map_X_67 1;
BA_ "GenSigSendType" SG_ 2654552209 FD14_Point_Map_Reserved_66 1;
BA_ "GenSigSendType" SG_ 2654552209 FD14_Point_Map_Age_66 1;
BA_ "GenSigSendType" SG_ 2654552209 FD14_Point_Map_Confidence_66 1;
BA_ "GenSigSendType" SG_ 2654552209 FD14_Point_Map_Height_66 1;
BA_ "GenSigSendType" SG_ 2654552209 FD14_Point_Map_Y_66 1;
BA_ "GenSigSendType" SG_ 2654552209 FD14_Point_Map_X_66 1;
BA_ "GenSigSendType" SG_ 2654552209 FD14_Point_Map_Reserved_65 1;
BA_ "GenSigSendType" SG_ 2654552209 FD14_Point_Map_Age_65 1;
BA_ "GenSigSendType" SG_ 2654552209 FD14_Point_Map_Confidence_65 1;
BA_ "GenSigSendType" SG_ 2654552209 FD14_Point_Map_Height_65 1;
BA_ "GenSigSendType" SG_ 2654552209 FD14_Point_Map_Y_65 1;
BA_ "GenSigSendType" SG_ 2654552209 FD14_Point_Map_X_65 1;
BA_ "GenSigSendType" SG_ 2654552209 FD14_Point_Map_Reserved_64 1;
BA_ "GenSigSendType" SG_ 2654552209 FD14_Point_Map_Age_64 1;
BA_ "GenSigSendType" SG_ 2654552209 FD14_Point_Map_Confidence_64 1;
BA_ "GenSigSendType" SG_ 2654552209 FD14_Point_Map_Height_64 1;
BA_ "GenSigSendType" SG_ 2654552209 FD14_Point_Map_Y_64 1;
BA_ "GenSigSendType" SG_ 2654552209 FD14_Point_Map_X_64 1;
BA_ "GenSigSendType" SG_ 2654552210 FD14_Point_Map_Cruising_Age_79 1;
BA_ "GenSigSendType" SG_ 2654552210 FD14_Point_Map_Cruising_Age_78 1;
BA_ "GenSigSendType" SG_ 2654552210 FD14_Point_Map_Cruising_Age_77 1;
BA_ "GenSigSendType" SG_ 2654552210 FD14_Point_Map_Cruising_Age_76 1;
BA_ "GenSigSendType" SG_ 2654552210 FD14_Point_Map_Cruising_Age_75 1;
BA_ "GenSigSendType" SG_ 2654552210 FD14_Point_Map_Cruising_Age_74 1;
BA_ "GenSigSendType" SG_ 2654552210 FD14_Point_Map_Cruising_Age_73 1;
BA_ "GenSigSendType" SG_ 2654552210 FD14_Point_Map_Cruising_Age_72 1;
BA_ "GenSigSendType" SG_ 2654552210 FD14_Point_Map_Reserved_79 1;
BA_ "GenSigSendType" SG_ 2654552210 FD14_Point_Map_Age_79 1;
BA_ "GenSigSendType" SG_ 2654552210 FD14_Point_Map_Confidence_79 1;
BA_ "GenSigSendType" SG_ 2654552210 FD14_Point_Map_Height_79 1;
BA_ "GenSigSendType" SG_ 2654552210 FD14_Point_Map_Y_79 1;
BA_ "GenSigSendType" SG_ 2654552210 FD14_Point_Map_X_79 1;
BA_ "GenSigSendType" SG_ 2654552210 FD14_Point_Map_Reserved_78 1;
BA_ "GenSigSendType" SG_ 2654552210 FD14_Point_Map_Age_78 1;
BA_ "GenSigSendType" SG_ 2654552210 FD14_Point_Map_Confidence_78 1;
BA_ "GenSigSendType" SG_ 2654552210 FD14_Point_Map_Height_78 1;
BA_ "GenSigSendType" SG_ 2654552210 FD14_Point_Map_Y_78 1;
BA_ "GenSigSendType" SG_ 2654552210 FD14_Point_Map_X_78 1;
BA_ "GenSigSendType" SG_ 2654552210 FD14_Point_Map_Reserved_77 1;
BA_ "GenSigSendType" SG_ 2654552210 FD14_Point_Map_Age_77 1;
BA_ "GenSigSendType" SG_ 2654552210 FD14_Point_Map_Confidence_77 1;
BA_ "GenSigSendType" SG_ 2654552210 FD14_Point_Map_Height_77 1;
BA_ "GenSigSendType" SG_ 2654552210 FD14_Point_Map_Y_77 1;
BA_ "GenSigSendType" SG_ 2654552210 FD14_Point_Map_X_77 1;
BA_ "GenSigSendType" SG_ 2654552210 FD14_Point_Map_Reserved_76 1;
BA_ "GenSigSendType" SG_ 2654552210 FD14_Point_Map_Age_76 1;
BA_ "GenSigSendType" SG_ 2654552210 FD14_Point_Map_Confidence_76 1;
BA_ "GenSigSendType" SG_ 2654552210 FD14_Point_Map_Height_76 1;
BA_ "GenSigSendType" SG_ 2654552210 FD14_Point_Map_Y_76 1;
BA_ "GenSigSendType" SG_ 2654552210 FD14_Point_Map_X_76 1;
BA_ "GenSigSendType" SG_ 2654552210 FD14_Point_Map_Reserved_75 1;
BA_ "GenSigSendType" SG_ 2654552210 FD14_Point_Map_Age_75 1;
BA_ "GenSigSendType" SG_ 2654552210 FD14_Point_Map_Confidence_75 1;
BA_ "GenSigSendType" SG_ 2654552210 FD14_Point_Map_Height_75 1;
BA_ "GenSigSendType" SG_ 2654552210 FD14_Point_Map_Y_75 1;
BA_ "GenSigSendType" SG_ 2654552210 FD14_Point_Map_X_75 1;
BA_ "GenSigSendType" SG_ 2654552210 FD14_Point_Map_Reserved_74 1;
BA_ "GenSigSendType" SG_ 2654552210 FD14_Point_Map_Age_74 1;
BA_ "GenSigSendType" SG_ 2654552210 FD14_Point_Map_Confidence_74 1;
BA_ "GenSigSendType" SG_ 2654552210 FD14_Point_Map_Height_74 1;
BA_ "GenSigSendType" SG_ 2654552210 FD14_Point_Map_Y_74 1;
BA_ "GenSigSendType" SG_ 2654552210 FD14_Point_Map_X_74 1;
BA_ "GenSigSendType" SG_ 2654552210 FD14_Point_Map_Reserved_73 1;
BA_ "GenSigSendType" SG_ 2654552210 FD14_Point_Map_Age_73 1;
BA_ "GenSigSendType" SG_ 2654552210 FD14_Point_Map_Confidence_73 1;
BA_ "GenSigSendType" SG_ 2654552210 FD14_Point_Map_Height_73 1;
BA_ "GenSigSendType" SG_ 2654552210 FD14_Point_Map_Y_73 1;
BA_ "GenSigSendType" SG_ 2654552210 FD14_Point_Map_X_73 1;
BA_ "GenSigSendType" SG_ 2654552210 FD14_Point_Map_Reserved_72 1;
BA_ "GenSigSendType" SG_ 2654552210 FD14_Point_Map_Age_72 1;
BA_ "GenSigSendType" SG_ 2654552210 FD14_Point_Map_Confidence_72 1;
BA_ "GenSigSendType" SG_ 2654552210 FD14_Point_Map_Height_72 1;
BA_ "GenSigSendType" SG_ 2654552210 FD14_Point_Map_Y_72 1;
BA_ "GenSigSendType" SG_ 2654552210 FD14_Point_Map_X_72 1;
BA_ "GenSigSendType" SG_ 2654552211 FD14_Point_Map_Cruising_Age_87 1;
BA_ "GenSigSendType" SG_ 2654552211 FD14_Point_Map_Cruising_Age_86 1;
BA_ "GenSigSendType" SG_ 2654552211 FD14_Point_Map_Cruising_Age_85 1;
BA_ "GenSigSendType" SG_ 2654552211 FD14_Point_Map_Cruising_Age_84 1;
BA_ "GenSigSendType" SG_ 2654552211 FD14_Point_Map_Cruising_Age_83 1;
BA_ "GenSigSendType" SG_ 2654552211 FD14_Point_Map_Cruising_Age_82 1;
BA_ "GenSigSendType" SG_ 2654552211 FD14_Point_Map_Cruising_Age_81 1;
BA_ "GenSigSendType" SG_ 2654552211 FD14_Point_Map_Cruising_Age_80 1;
BA_ "GenSigSendType" SG_ 2654552211 FD14_Point_Map_Reserved_87 1;
BA_ "GenSigSendType" SG_ 2654552211 FD14_Point_Map_Age_87 1;
BA_ "GenSigSendType" SG_ 2654552211 FD14_Point_Map_Confidence_87 1;
BA_ "GenSigSendType" SG_ 2654552211 FD14_Point_Map_Height_87 1;
BA_ "GenSigSendType" SG_ 2654552211 FD14_Point_Map_Y_87 1;
BA_ "GenSigSendType" SG_ 2654552211 FD14_Point_Map_X_87 1;
BA_ "GenSigSendType" SG_ 2654552211 FD14_Point_Map_Reserved_86 1;
BA_ "GenSigSendType" SG_ 2654552211 FD14_Point_Map_Age_86 1;
BA_ "GenSigSendType" SG_ 2654552211 FD14_Point_Map_Confidence_86 1;
BA_ "GenSigSendType" SG_ 2654552211 FD14_Point_Map_Height_86 1;
BA_ "GenSigSendType" SG_ 2654552211 FD14_Point_Map_Y_86 1;
BA_ "GenSigSendType" SG_ 2654552211 FD14_Point_Map_X_86 1;
BA_ "GenSigSendType" SG_ 2654552211 FD14_Point_Map_Reserved_85 1;
BA_ "GenSigSendType" SG_ 2654552211 FD14_Point_Map_Age_85 1;
BA_ "GenSigSendType" SG_ 2654552211 FD14_Point_Map_Confidence_85 1;
BA_ "GenSigSendType" SG_ 2654552211 FD14_Point_Map_Height_85 1;
BA_ "GenSigSendType" SG_ 2654552211 FD14_Point_Map_Y_85 1;
BA_ "GenSigSendType" SG_ 2654552211 FD14_Point_Map_X_85 1;
BA_ "GenSigSendType" SG_ 2654552211 FD14_Point_Map_Reserved_84 1;
BA_ "GenSigSendType" SG_ 2654552211 FD14_Point_Map_Age_84 1;
BA_ "GenSigSendType" SG_ 2654552211 FD14_Point_Map_Confidence_84 1;
BA_ "GenSigSendType" SG_ 2654552211 FD14_Point_Map_Height_84 1;
BA_ "GenSigSendType" SG_ 2654552211 FD14_Point_Map_Y_84 1;
BA_ "GenSigSendType" SG_ 2654552211 FD14_Point_Map_X_84 1;
BA_ "GenSigSendType" SG_ 2654552211 FD14_Point_Map_Reserved_83 1;
BA_ "GenSigSendType" SG_ 2654552211 FD14_Point_Map_Age_83 1;
BA_ "GenSigSendType" SG_ 2654552211 FD14_Point_Map_Confidence_83 1;
BA_ "GenSigSendType" SG_ 2654552211 FD14_Point_Map_Height_83 1;
BA_ "GenSigSendType" SG_ 2654552211 FD14_Point_Map_Y_83 1;
BA_ "GenSigSendType" SG_ 2654552211 FD14_Point_Map_X_83 1;
BA_ "GenSigSendType" SG_ 2654552211 FD14_Point_Map_Reserved_82 1;
BA_ "GenSigSendType" SG_ 2654552211 FD14_Point_Map_Age_82 1;
BA_ "GenSigSendType" SG_ 2654552211 FD14_Point_Map_Confidence_82 1;
BA_ "GenSigSendType" SG_ 2654552211 FD14_Point_Map_Height_82 1;
BA_ "GenSigSendType" SG_ 2654552211 FD14_Point_Map_Y_82 1;
BA_ "GenSigSendType" SG_ 2654552211 FD14_Point_Map_X_82 1;
BA_ "GenSigSendType" SG_ 2654552211 FD14_Point_Map_Reserved_81 1;
BA_ "GenSigSendType" SG_ 2654552211 FD14_Point_Map_Age_81 1;
BA_ "GenSigSendType" SG_ 2654552211 FD14_Point_Map_Confidence_81 1;
BA_ "GenSigSendType" SG_ 2654552211 FD14_Point_Map_Height_81 1;
BA_ "GenSigSendType" SG_ 2654552211 FD14_Point_Map_Y_81 1;
BA_ "GenSigSendType" SG_ 2654552211 FD14_Point_Map_X_81 1;
BA_ "GenSigSendType" SG_ 2654552211 FD14_Point_Map_Reserved_80 1;
BA_ "GenSigSendType" SG_ 2654552211 FD14_Point_Map_Age_80 1;
BA_ "GenSigSendType" SG_ 2654552211 FD14_Point_Map_Confidence_80 1;
BA_ "GenSigSendType" SG_ 2654552211 FD14_Point_Map_Height_80 1;
BA_ "GenSigSendType" SG_ 2654552211 FD14_Point_Map_Y_80 1;
BA_ "GenSigSendType" SG_ 2654552211 FD14_Point_Map_X_80 1;
BA_ "GenSigSendType" SG_ 2654552212 FD14_Point_Map_Cruising_Age_95 1;
BA_ "GenSigSendType" SG_ 2654552212 FD14_Point_Map_Cruising_Age_94 1;
BA_ "GenSigSendType" SG_ 2654552212 FD14_Point_Map_Cruising_Age_93 1;
BA_ "GenSigSendType" SG_ 2654552212 FD14_Point_Map_Cruising_Age_92 1;
BA_ "GenSigSendType" SG_ 2654552212 FD14_Point_Map_Cruising_Age_91 1;
BA_ "GenSigSendType" SG_ 2654552212 FD14_Point_Map_Cruising_Age_90 1;
BA_ "GenSigSendType" SG_ 2654552212 FD14_Point_Map_Cruising_Age_89 1;
BA_ "GenSigSendType" SG_ 2654552212 FD14_Point_Map_Cruising_Age_88 1;
BA_ "GenSigSendType" SG_ 2654552212 FD14_Point_Map_Reserved_94 1;
BA_ "GenSigSendType" SG_ 2654552212 FD14_Point_Map_Age_94 1;
BA_ "GenSigSendType" SG_ 2654552212 FD14_Point_Map_Confidence_94 1;
BA_ "GenSigSendType" SG_ 2654552212 FD14_Point_Map_Height_94 1;
BA_ "GenSigSendType" SG_ 2654552212 FD14_Point_Map_Y_94 1;
BA_ "GenSigSendType" SG_ 2654552212 FD14_Point_Map_X_94 1;
BA_ "GenSigSendType" SG_ 2654552212 FD14_Point_Map_Reserved_93 1;
BA_ "GenSigSendType" SG_ 2654552212 FD14_Point_Map_Age_93 1;
BA_ "GenSigSendType" SG_ 2654552212 FD14_Point_Map_Confidence_93 1;
BA_ "GenSigSendType" SG_ 2654552212 FD14_Point_Map_Height_93 1;
BA_ "GenSigSendType" SG_ 2654552212 FD14_Point_Map_Y_93 1;
BA_ "GenSigSendType" SG_ 2654552212 FD14_Point_Map_X_93 1;
BA_ "GenSigSendType" SG_ 2654552212 FD14_Point_Map_Reserved_92 1;
BA_ "GenSigSendType" SG_ 2654552212 FD14_Point_Map_Age_92 1;
BA_ "GenSigSendType" SG_ 2654552212 FD14_Point_Map_Confidence_92 1;
BA_ "GenSigSendType" SG_ 2654552212 FD14_Point_Map_Height_92 1;
BA_ "GenSigSendType" SG_ 2654552212 FD14_Point_Map_Y_92 1;
BA_ "GenSigSendType" SG_ 2654552212 FD14_Point_Map_X_92 1;
BA_ "GenSigSendType" SG_ 2654552212 FD14_Point_Map_Reserved_91 1;
BA_ "GenSigSendType" SG_ 2654552212 FD14_Point_Map_Age_91 1;
BA_ "GenSigSendType" SG_ 2654552212 FD14_Point_Map_Confidence_91 1;
BA_ "GenSigSendType" SG_ 2654552212 FD14_Point_Map_Height_91 1;
BA_ "GenSigSendType" SG_ 2654552212 FD14_Point_Map_Y_91 1;
BA_ "GenSigSendType" SG_ 2654552212 FD14_Point_Map_X_91 1;
BA_ "GenSigSendType" SG_ 2654552212 FD14_Point_Map_Reserved_90 1;
BA_ "GenSigSendType" SG_ 2654552212 FD14_Point_Map_Age_90 1;
BA_ "GenSigSendType" SG_ 2654552212 FD14_Point_Map_Confidence_90 1;
BA_ "GenSigSendType" SG_ 2654552212 FD14_Point_Map_Height_90 1;
BA_ "GenSigSendType" SG_ 2654552212 FD14_Point_Map_Y_90 1;
BA_ "GenSigSendType" SG_ 2654552212 FD14_Point_Map_X_90 1;
BA_ "GenSigSendType" SG_ 2654552212 FD14_Point_Map_Reserved_89 1;
BA_ "GenSigSendType" SG_ 2654552212 FD14_Point_Map_Age_89 1;
BA_ "GenSigSendType" SG_ 2654552212 FD14_Point_Map_Confidence_89 1;
BA_ "GenSigSendType" SG_ 2654552212 FD14_Point_Map_Height_89 1;
BA_ "GenSigSendType" SG_ 2654552212 FD14_Point_Map_Y_89 1;
BA_ "GenSigSendType" SG_ 2654552212 FD14_Point_Map_X_89 1;
BA_ "GenSigSendType" SG_ 2654552212 FD14_Point_Map_Reserved_88 1;
BA_ "GenSigSendType" SG_ 2654552212 FD14_Point_Map_Age_88 1;
BA_ "GenSigSendType" SG_ 2654552212 FD14_Point_Map_Confidence_88 1;
BA_ "GenSigSendType" SG_ 2654552212 FD14_Point_Map_Height_88 1;
BA_ "GenSigSendType" SG_ 2654552212 FD14_Point_Map_Y_88 1;
BA_ "GenSigSendType" SG_ 2654552212 FD14_Point_Map_X_88 1;
BA_ "GenSigSendType" SG_ 2654552212 FD14_Point_Map_Reserved_95 1;
BA_ "GenSigSendType" SG_ 2654552212 FD14_Point_Map_Age_95 1;
BA_ "GenSigSendType" SG_ 2654552212 FD14_Point_Map_Confidence_95 1;
BA_ "GenSigSendType" SG_ 2654552212 FD14_Point_Map_Y_95 1;
BA_ "GenSigSendType" SG_ 2654552212 FD14_Point_Map_Height_95 1;
BA_ "GenSigSendType" SG_ 2654552212 FD14_Point_Map_X_95 1;
BA_ "GenSigSendType" SG_ 2654552213 FD14_FiringMode_TimeStamp 1;
BA_ "GenSigSendType" SG_ 2654552213 FD14_Firing_Mode_Seq 1;
BA_ "GenSigSendType" SG_ 2654552214 FD14_FiringSnr_TimeStamp 1;
BA_ "GenSigSendType" SG_ 2654552214 FD14_Firing_Sensor 1;
BA_ "GenSigSendType" SG_ 2654552215 FD14_Current_Firing_Sequence 1;
BA_ "GenSigSendType" SG_ 2654552193 FD14_cntrCvpamFdData1_u16 1;
BA_ "GenSigSendType" SG_ 2654552193 FD14_crcCvpamFdData1_u8 1;
BA_ "GenSigSendType" SG_ 2654552193 FD14_msgcntrCvpamFdData1_u8 1;
BA_ "GenSigSendType" SG_ 2654552193 FD14_macCvpamFdData1_u64 1;
BA_ "GenSigSendType" SG_ 2654552193 FD14_obj_Pos_Longi 1;
BA_ "GenSigSendType" SG_ 2654552193 FD14_obj_Pos_Lat 1;
BA_ "GenSigSendType" SG_ 2654552193 FD14_objConf_e 1;
BA_ "GenSigSendType" SG_ 2654552193 FD14_FrontSensorDetHealth_e 1;
BA_ "GenSigSendType" SG_ 2654814256 FD14_Log_PackedDiagFlagData2_v 1;
BA_ "GenSigSendType" SG_ 2654814248 FD14_Log_PackedDiagFlagData1_v 1;
BA_ "GenSigSendType" SG_ 2654814249 FD14_Log_PackedNoiseMeasData 1;
BA_ "GenSigSendType" SG_ 2654552336 FD14_stFPAInfoToVCLockedSlotRear 1;
BA_ "SystemSignalLongSymbol" SG_ 2654552336 FD14_stFPAInfoToVCLockedSlotRear "FD14_stFPAInfoToVCLockedSlotRearRghtY";
BA_ "GenSigSendType" SG_ 2654552336 FD14_stFPAInfoToVCLockedSlotFrnt 1;
BA_ "SystemSignalLongSymbol" SG_ 2654552336 FD14_stFPAInfoToVCLockedSlotFrnt "FD14_stFPAInfoToVCLockedSlotFrntLeftY";
BA_ "GenSigSendType" SG_ 2654552336 FD14_stFPAInfoToVCLockedSlo_0000 1;
BA_ "SystemSignalLongSymbol" SG_ 2654552336 FD14_stFPAInfoToVCLockedSlo_0000 "FD14_stFPAInfoToVCLockedSlotRearRghtX";
BA_ "GenSigSendType" SG_ 2654552336 FD14_stFPAInfoToVCLockedSlo_0001 1;
BA_ "SystemSignalLongSymbol" SG_ 2654552336 FD14_stFPAInfoToVCLockedSlo_0001 "FD14_stFPAInfoToVCLockedSlotFrntLeftX";
BA_ "GenSigSendType" SG_ 2654552336 FD14_stFPAInfoToVCLockedSlotType 1;
BA_ "GenSigSendType" SG_ 2654552336 FD14_m_FPAToNVMParkInStyle 1;
BA_ "GenSigSendType" SG_ 2654552336 FD14_stFPAInfoToVCLockedSlotSide 1;
BA_ "GenSigSendType" SG_ 2654552336 FD14_m_FpaInfoToVCParkOutStyle 1;
BA_ "GenSigSendType" SG_ 2654552336 FD14_stFPAInfoToVCLockedSlotID 1;
BA_ "GenSigSendType" SG_ 2654552336 FD14_m_FPAInfoToUSSOMSlotID 1;
BA_ "GenSigSendType" SG_ 2654552336 FD14_m_FPAInfoToPLDSlotID 1;
BA_ "GenSigSendType" SG_ 2654552336 FD14_stFPAInfoToHMISlot6Valid 1;
BA_ "GenSigSendType" SG_ 2654552336 FD14_stFPAInfoToHMISlot5Valid 1;
BA_ "GenSigSendType" SG_ 2654552336 FD14_stFPAInfoToHMISlot4Valid 1;
BA_ "GenSigSendType" SG_ 2654552336 FD14_stFPAInfoToHMISlot3Valid 1;
BA_ "GenSigSendType" SG_ 2654552336 FD14_stFPAInfoToHMISlot2Valid 1;
BA_ "GenSigSendType" SG_ 2654552336 FD14_stFPAInfoToHMISlot1Valid 1;
BA_ "GenSigSendType" SG_ 2654552336 FD14_m_FPAToNVMWriteNVMParam_b 1;
BA_ "GenSigSendType" SG_ 2654552336 FD14_m_FPAToNVMReadNVMParam_b 1;
BA_ "GenSigSendType" SG_ 2654552336 FD14_stFPAInfoToVCLockedSlotVali 1;
BA_ "SystemSignalLongSymbol" SG_ 2654552336 FD14_stFPAInfoToVCLockedSlotVali "FD14_stFPAInfoToVCLockedSlotValid";
BA_ "GenSigSendType" SG_ 2654552336 FD14_AutoParkInitializedStatus_b 1;
BA_ "GenSigSendType" SG_ 2654552145 FD14_Frameset1AndTopFrontText_b 1;
BA_ "GenSigSendType" SG_ 2654552145 FD14_Frameset1AndTopRearText_b 1;
BA_ "GenSigSendType" SG_ 2654552145 FD14_Frameset2AndFrontCrossText_ 1;
BA_ "SystemSignalLongSymbol" SG_ 2654552145 FD14_Frameset2AndFrontCrossText_ "FD14_Frameset2AndFrontCrossText_b";
BA_ "GenSigSendType" SG_ 2654552145 FD14_Frameset2AndRearCrossText_b 1;
BA_ "GenSigSendType" SG_ 2654552145 FD14_MoreCamsIconFullScreenNoSel 1;
BA_ "SystemSignalLongSymbol" SG_ 2654552145 FD14_MoreCamsIconFullScreenNoSel "FD14_MoreCamsIconFullScreenNoSelect_b";
BA_ "GenSigSendType" SG_ 2654552145 FD14_TopRearButtonNoSelect_b 1;
BA_ "GenSigSendType" SG_ 2654552145 FD14_TopRearButtonSelect_b 1;
BA_ "GenSigSendType" SG_ 2654552145 FD14_RearCrossButtonNoSelect_b 1;
BA_ "GenSigSendType" SG_ 2654552145 FD14_RearCrossButtonSelect_b 1;
BA_ "GenSigSendType" SG_ 2654552145 FD14_FrontCrossButtonNoSelect_b 1;
BA_ "GenSigSendType" SG_ 2654552145 FD14_FrontCrossButtonSelect_b 1;
BA_ "GenSigSendType" SG_ 2654552145 FD14_TopFrontButtonSelect_b 1;
BA_ "GenSigSendType" SG_ 2654552145 FD14_TopFrontButtonNoSelect_b 1;
BA_ "GenSigSendType" SG_ 2654552145 FD14_BackupRearCamButtonSelect_b 1;
BA_ "GenSigSendType" SG_ 2654552145 FD14_BackupRearCamButtonNoSelect 1;
BA_ "SystemSignalLongSymbol" SG_ 2654552145 FD14_BackupRearCamButtonNoSelect "FD14_BackupRearCamButtonNoSelect_b";
BA_ "GenSigSendType" SG_ 2654552145 FD14_FrontFaceCamButtonSelect_b 1;
BA_ "GenSigSendType" SG_ 2654552145 FD14_FrontFaceCamButtonNoSelect_ 1;
BA_ "SystemSignalLongSymbol" SG_ 2654552145 FD14_FrontFaceCamButtonNoSelect_ "FD14_FrontFaceCamButtonNoSelect_b";
BA_ "GenSigSendType" SG_ 2654552145 FD14_FrontTireTracks_b 1;
BA_ "GenSigSendType" SG_ 2654552145 FD14_AuxCamButton1Select_b 1;
BA_ "GenSigSendType" SG_ 2654552145 FD14_AuxCamButton1NoSelect_b 1;
BA_ "GenSigSendType" SG_ 2654552145 FD14_AuxCamButton2Select_b 1;
BA_ "GenSigSendType" SG_ 2654552145 FD14_AuxCamButton2NoSelect_b 1;
BA_ "GenSigSendType" SG_ 2654552145 FD14_MoreCamsButton1Select_b 1;
BA_ "GenSigSendType" SG_ 2654552145 FD14_MoreCamsButton1NoSelect_b 1;
BA_ "GenSigSendType" SG_ 2654552145 FD14_MoreCamsButton2Select_b 1;
BA_ "GenSigSendType" SG_ 2654552145 FD14_MoreCamsButton2NoSelect_b 1;
BA_ "GenSigSendType" SG_ 2654552145 FD14_RearViewDynamics_b 1;
BA_ "GenSigSendType" SG_ 2654552145 FD14_TopViewRearDynamics_b 1;
BA_ "GenSigSendType" SG_ 2654552145 FD14_FrontViewDynamics_b 1;
BA_ "GenSigSendType" SG_ 2654552145 FD14_TopViewFrontDynamics_b 1;
BA_ "GenSigSendType" SG_ 2654552145 FD14_XIcon_b 1;
BA_ "GenSigSendType" SG_ 2654552145 FD14_ZoomButtonDisable_b 1;
BA_ "GenSigSendType" SG_ 2654552145 FD14_ZoomMinusIcon_b 1;
BA_ "GenSigSendType" SG_ 2654552145 FD14_ZoomPlusIcon_b 1;
BA_ "GenSigSendType" SG_ 2654552145 FD14_LeftDoorFrontOpen_Icon_b 1;
BA_ "GenSigSendType" SG_ 2654552145 FD14_LeftDoorRearOpen_Icon_b 1;
BA_ "GenSigSendType" SG_ 2654552145 FD14_RightDoorFrontOpen_Icon_b 1;
BA_ "GenSigSendType" SG_ 2654552145 FD14_RightDoorRearOpen_Icon_b 1;
BA_ "GenSigSendType" SG_ 2654552145 FD14_BackDoorOpen_Icon_b 1;
BA_ "GenSigSendType" SG_ 2654552145 FD14_FrontCam_NA_b 1;
BA_ "GenSigSendType" SG_ 2654552145 FD14_LeftCam_NA_b 1;
BA_ "GenSigSendType" SG_ 2654552145 FD14_BackCam_NA_b 1;
BA_ "GenSigSendType" SG_ 2654552145 FD14_RightCam_NA_b 1;
BA_ "GenSigSendType" SG_ 2654552145 FD14_TopViewBlack_b 1;
BA_ "GenSigSendType" SG_ 2654552145 FD14_LeftDoorFrontClose_Icon_b 1;
BA_ "GenSigSendType" SG_ 2654552145 FD14_LeftDoorRearClose_Icon_b 1;
BA_ "GenSigSendType" SG_ 2654552145 FD14_RightDoorFrontClose_Icon_b 1;
BA_ "GenSigSendType" SG_ 2654552145 FD14_RightDoorRearClose_Icon_b 1;
BA_ "GenSigSendType" SG_ 2654552145 FD14_Reserved13_b 1;
BA_ "GenSigSendType" SG_ 2654552145 FD14_PDC_RearCenter_Yellow_b 1;
BA_ "GenSigSendType" SG_ 2654552145 FD14_PDC_RearCenter_Red_b 1;
BA_ "GenSigSendType" SG_ 2654552145 FD14_Reserved12_b 1;
BA_ "GenSigSendType" SG_ 2654552145 FD14_PDC_RearRight_Yellow_b 1;
BA_ "GenSigSendType" SG_ 2654552145 FD14_PDC_RearRight_Red_b 1;
BA_ "GenSigSendType" SG_ 2654552145 FD14_Reserved11_b 1;
BA_ "GenSigSendType" SG_ 2654552145 FD14_PDC_FrontLeft_Yellow_b 1;
BA_ "GenSigSendType" SG_ 2654552145 FD14_PDC_FrontLeft_Red_b 1;
BA_ "GenSigSendType" SG_ 2654552145 FD14_Reserved10_b 1;
BA_ "GenSigSendType" SG_ 2654552145 FD14_PDC_FrontCenter_Yellow_b 1;
BA_ "GenSigSendType" SG_ 2654552145 FD14_PDC_FrontCenter_Red_b 1;
BA_ "GenSigSendType" SG_ 2654552145 FD14_Reserved09_b 1;
BA_ "GenSigSendType" SG_ 2654552145 FD14_PDC_FrontRight_Yellow_b 1;
BA_ "GenSigSendType" SG_ 2654552145 FD14_PDC_FrontRight_Red_b 1;
BA_ "GenSigSendType" SG_ 2654552145 FD14_Reserved08_b 1;
BA_ "GenSigSendType" SG_ 2654552145 FD14_PDC_RearLeft_Yellow_b 1;
BA_ "GenSigSendType" SG_ 2654552145 FD14_PDC_RearLeft_Red_b 1;
BA_ "GenSigSendType" SG_ 2654552145 FD14_SrvLayout_b 1;
BA_ "GenSigSendType" SG_ 2654552145 FD14_SrvStAngIndOk_b 1;
BA_ "GenSigSendType" SG_ 2654552145 FD14_SrvStAngIndNok_b 1;
BA_ "GenSigSendType" SG_ 2654552145 FD14_SrvSpOmIndOk_b 1;
BA_ "GenSigSendType" SG_ 2654552145 FD14_SrvSpOmIndNok_b 1;
BA_ "GenSigSendType" SG_ 2654552145 FD14_SrvChkIndRun_b 1;
BA_ "GenSigSendType" SG_ 2654552145 FD14_SrvChkIndOk_b 1;
BA_ "GenSigSendType" SG_ 2654552145 FD14_SrvChkIndNok_b 1;
BA_ "GenSigSendType" SG_ 2654552145 FD14_SrvChkIndCondNok_b 1;
BA_ "GenSigSendType" SG_ 2654552145 FD14_SrvCamIndFrOk_b 1;
BA_ "GenSigSendType" SG_ 2654552145 FD14_SrvCamIndFrNok_b 1;
BA_ "GenSigSendType" SG_ 2654552145 FD14_SrvCamIndFrPend_b 1;
BA_ "GenSigSendType" SG_ 2654552145 FD14_SrvCamIndFrNone_b 1;
BA_ "GenSigSendType" SG_ 2654552145 FD14_SrvCamIndLeOk_b 1;
BA_ "GenSigSendType" SG_ 2654552145 FD14_SrvCamIndLeNok_b 1;
BA_ "GenSigSendType" SG_ 2654552145 FD14_SrvCamIndLePend_b 1;
BA_ "GenSigSendType" SG_ 2654552145 FD14_SrvCamIndLeNone_b 1;
BA_ "GenSigSendType" SG_ 2654552145 FD14_SrvCamIndBaOk_b 1;
BA_ "GenSigSendType" SG_ 2654552145 FD14_SrvCamIndBaNok_b 1;
BA_ "GenSigSendType" SG_ 2654552145 FD14_SrvCamIndBaPend_b 1;
BA_ "GenSigSendType" SG_ 2654552145 FD14_SrvCamIndBaNone_b 1;
BA_ "GenSigSendType" SG_ 2654552145 FD14_SrvCamIndRiOk_b 1;
BA_ "GenSigSendType" SG_ 2654552145 FD14_SrvCamIndRiNok_b 1;
BA_ "GenSigSendType" SG_ 2654552145 FD14_SrvCamIndRiPend_b 1;
BA_ "GenSigSendType" SG_ 2654552145 FD14_SrvCamIndRiNone_b 1;
BA_ "GenSigSendType" SG_ 2654552145 FD14_SrvPrgBar0Per_b 1;
BA_ "GenSigSendType" SG_ 2654552145 FD14_SrvPrgBar20Per_b 1;
BA_ "GenSigSendType" SG_ 2654552145 FD14_SrvPrgBar40Per_b 1;
BA_ "GenSigSendType" SG_ 2654552145 FD14_SrvPrgBar60Per_b 1;
BA_ "GenSigSendType" SG_ 2654552145 FD14_SrvPrgBar80Per_b 1;
BA_ "GenSigSendType" SG_ 2654552145 FD14_SrvPrgBar100Per_b 1;
BA_ "GenSigSendType" SG_ 2654552145 FD14_TrscOvl 1;
BA_ "GenSigSendType" SG_ 2654552145 FD14_TrscJackKnifeOrange 1;
BA_ "GenSigSendType" SG_ 2654552145 FD14_TrscJackKnifeRed 1;
BA_ "GenSigSendType" SG_ 2654552145 FD14_TrscTrailerRed 1;
BA_ "GenSigSendType" SG_ 2654552145 FD14_THATriangleOverlay 1;
BA_ "GenSigSendType" SG_ 2654552145 FD14_THACouplerBulletIcon 1;
BA_ "GenSigSendType" SG_ 2654552145 FD14_THAButtonGrey 1;
BA_ "GenSigSendType" SG_ 2654552145 FD14_THAButtonSelectable 1;
BA_ "GenSigSendType" SG_ 2654552145 FD14_THAConfirmButton 1;
BA_ "GenSigSendType" SG_ 2654552145 FD14_THAStartButton 1;
BA_ "GenSigSendType" SG_ 2654552145 FD14_THAProgressBar 1;
BA_ "GenSigSendType" SG_ 2654552145 FD14_Reserved3_b 1;
BA_ "GenSigSendType" SG_ 2654552145 FD14_Reserved2_b 1;
BA_ "GenSigSendType" SG_ 2654552145 FD14_Reserved1_b 1;
BA_ "GenSigSendType" SG_ 2654552145 FD14_Reserved0_b 1;
BA_ "GenSigSendType" SG_ 2654552147 FD14_MePRX_b_TRSCPresence 1;
BA_ "GenSigStartValue" SG_ 2654552147 FD14_MePRX_b_TRSCPresence 1;
BA_ "GenSigSendType" SG_ 2654552147 FD14_MePRX_b_TRGPresence 1;
BA_ "GenSigStartValue" SG_ 2654552147 FD14_MePRX_b_TRGPresence 1;
BA_ "GenSigSendType" SG_ 2654552147 FD14_MePRX_b_CanNode27 1;
BA_ "GenSigStartValue" SG_ 2654552147 FD14_MePRX_b_CanNode27 1;
BA_ "GenSigSendType" SG_ 2654552147 FD14_MePRX_b_CANNode95 1;
BA_ "GenSigStartValue" SG_ 2654552147 FD14_MePRX_b_CANNode95 1;
BA_ "GenSigSendType" SG_ 2654552147 FD14_MePRX_b_AuxTrlrCam 1;
BA_ "GenSigStartValue" SG_ 2654552147 FD14_MePRX_b_AuxTrlrCam 1;
BA_ "GenSigSendType" SG_ 2654552147 FD14_MePRX_b_FrwFacingCam 1;
BA_ "GenSigStartValue" SG_ 2654552147 FD14_MePRX_b_FrwFacingCam 1;
BA_ "GenSigSendType" SG_ 2654552147 FD14_MePRX_b_SurroundViewCamera 1;
BA_ "GenSigStartValue" SG_ 2654552147 FD14_MePRX_b_SurroundViewCamera 1;
BA_ "GenSigSendType" SG_ 2654552147 FD14_MePRX_e_AutonomyLvl 1;
BA_ "GenSigSendType" SG_ 2654552147 FD14_MePRX_e_PAMTunSet 1;
BA_ "GenSigSendType" SG_ 2654552147 FD14_MePRX_e_MirrorType 1;
BA_ "GenSigSendType" SG_ 2654552147 FD14_MePRX_e_RadDispType 1;
BA_ "GenSigSendType" SG_ 2654552147 FD14_MePRX_e_SteerRatRackPinionT 1;
BA_ "SystemSignalLongSymbol" SG_ 2654552147 FD14_MePRX_e_SteerRatRackPinionT "FD14_MePRX_e_SteerRatRackPinionType";
BA_ "GenSigSendType" SG_ 2654552147 FD14_MePRX_e_Wheelbase 1;
BA_ "GenSigSendType" SG_ 2654552147 FD14_MePRX_e_VehLineCfg 1;
BA_ "GenSigSendType" SG_ 2654552147 FD14_MePRX_e_VariantID 1;
BA_ "GenSigSendType" SG_ 2654552144 FD14_Frameset1AndTopFrontText_b 1;
BA_ "GenSigSendType" SG_ 2654552144 FD14_Frameset1AndTopRearText_b 1;
BA_ "GenSigSendType" SG_ 2654552144 FD14_Frameset2AndFrontCross_0000 1;
BA_ "SystemSignalLongSymbol" SG_ 2654552144 FD14_Frameset2AndFrontCross_0000 "FD14_Frameset2AndFrontCrossText_b";
BA_ "GenSigSendType" SG_ 2654552144 FD14_Frameset2AndRearCrossText_b 1;
BA_ "GenSigSendType" SG_ 2654552144 FD14_MoreCamsIconFullScreen_0000 1;
BA_ "SystemSignalLongSymbol" SG_ 2654552144 FD14_MoreCamsIconFullScreen_0000 "FD14_MoreCamsIconFullScreenNoSelect_b";
BA_ "GenSigSendType" SG_ 2654552144 FD14_TopRearButtonNoSelect_b 1;
BA_ "GenSigSendType" SG_ 2654552144 FD14_TopRearButtonSelect_b 1;
BA_ "GenSigSendType" SG_ 2654552144 FD14_RearCrossButtonNoSelect_b 1;
BA_ "GenSigSendType" SG_ 2654552144 FD14_RearCrossButtonSelect_b 1;
BA_ "GenSigSendType" SG_ 2654552144 FD14_FrontCrossButtonNoSelect_b 1;
BA_ "GenSigSendType" SG_ 2654552144 FD14_FrontCrossButtonSelect_b 1;
BA_ "GenSigSendType" SG_ 2654552144 FD14_TopFrontButtonSelect_b 1;
BA_ "GenSigSendType" SG_ 2654552144 FD14_TopFrontButtonNoSelect_b 1;
BA_ "GenSigSendType" SG_ 2654552144 FD14_BackupRearCamButtonSelect_b 1;
BA_ "GenSigSendType" SG_ 2654552144 FD14_BackupRearCamButtonNoS_0000 1;
BA_ "SystemSignalLongSymbol" SG_ 2654552144 FD14_BackupRearCamButtonNoS_0000 "FD14_BackupRearCamButtonNoSelect_b";
BA_ "GenSigSendType" SG_ 2654552144 FD14_FrontFaceCamButtonSelect_b 1;
BA_ "GenSigSendType" SG_ 2654552144 FD14_FrontFaceCamButtonNoSe_0000 1;
BA_ "SystemSignalLongSymbol" SG_ 2654552144 FD14_FrontFaceCamButtonNoSe_0000 "FD14_FrontFaceCamButtonNoSelect_b";
BA_ "GenSigSendType" SG_ 2654552144 FD14_FrontTireTracks_b 1;
BA_ "GenSigSendType" SG_ 2654552144 FD14_AuxCamButton1Select_b 1;
BA_ "GenSigSendType" SG_ 2654552144 FD14_AuxCamButton1NoSelect_b 1;
BA_ "GenSigSendType" SG_ 2654552144 FD14_AuxCamButton2Select_b 1;
BA_ "GenSigSendType" SG_ 2654552144 FD14_AuxCamButton2NoSelect_b 1;
BA_ "GenSigSendType" SG_ 2654552144 FD14_MoreCamsButton1Select_b 1;
BA_ "GenSigSendType" SG_ 2654552144 FD14_MoreCamsButton1NoSelect_b 1;
BA_ "GenSigSendType" SG_ 2654552144 FD14_MoreCamsButton2Select_b 1;
BA_ "GenSigSendType" SG_ 2654552144 FD14_MoreCamsButton2NoSelect_b 1;
BA_ "GenSigSendType" SG_ 2654552144 FD14_RearViewDynamics_b 1;
BA_ "GenSigSendType" SG_ 2654552144 FD14_TopViewRearDynamics_b 1;
BA_ "GenSigSendType" SG_ 2654552144 FD14_FrontViewDynamics_b 1;
BA_ "GenSigSendType" SG_ 2654552144 FD14_TopViewFrontDynamics_b 1;
BA_ "GenSigSendType" SG_ 2654552144 FD14_XIcon_b 1;
BA_ "GenSigSendType" SG_ 2654552144 FD14_ZoomButtonDisable_b 1;
BA_ "GenSigSendType" SG_ 2654552144 FD14_ZoomMinusIcon_b 1;
BA_ "GenSigSendType" SG_ 2654552144 FD14_ZoomPlusIcon_b 1;
BA_ "GenSigSendType" SG_ 2654552144 FD14_LeftDoorFrontOpen_Icon_b 1;
BA_ "GenSigSendType" SG_ 2654552144 FD14_LeftDoorRearOpen_Icon_b 1;
BA_ "GenSigSendType" SG_ 2654552144 FD14_RightDoorFrontOpen_Icon_b 1;
BA_ "GenSigSendType" SG_ 2654552144 FD14_RightDoorRearOpen_Icon_b 1;
BA_ "GenSigSendType" SG_ 2654552144 FD14_BackDoorOpen_Icon_b 1;
BA_ "GenSigSendType" SG_ 2654552144 FD14_FrontCam_NA_b 1;
BA_ "GenSigSendType" SG_ 2654552144 FD14_LeftCam_NA_b 1;
BA_ "GenSigSendType" SG_ 2654552144 FD14_BackCam_NA_b 1;
BA_ "GenSigSendType" SG_ 2654552144 FD14_RightCam_NA_b 1;
BA_ "GenSigSendType" SG_ 2654552144 FD14_TopViewBlack_b 1;
BA_ "GenSigSendType" SG_ 2654552144 FD14_LeftDoorFrontClose_Icon_b 1;
BA_ "GenSigSendType" SG_ 2654552144 FD14_LeftDoorRearClose_Icon_b 1;
BA_ "GenSigSendType" SG_ 2654552144 FD14_RightDoorFrontClose_Icon_b 1;
BA_ "GenSigSendType" SG_ 2654552144 FD14_RightDoorRearClose_Icon_b 1;
BA_ "GenSigSendType" SG_ 2654552144 FD14_Reserved13_b 1;
BA_ "GenSigSendType" SG_ 2654552144 FD14_PDC_RearCenter_Yellow_b 1;
BA_ "GenSigSendType" SG_ 2654552144 FD14_PDC_RearCenter_Red_b 1;
BA_ "GenSigSendType" SG_ 2654552144 FD14_Reserved12_b 1;
BA_ "GenSigSendType" SG_ 2654552144 FD14_PDC_RearRight_Yellow_b 1;
BA_ "GenSigSendType" SG_ 2654552144 FD14_PDC_RearRight_Red_b 1;
BA_ "GenSigSendType" SG_ 2654552144 FD14_Reserved11_b 1;
BA_ "GenSigSendType" SG_ 2654552144 FD14_PDC_FrontLeft_Yellow_b 1;
BA_ "GenSigSendType" SG_ 2654552144 FD14_PDC_FrontLeft_Red_b 1;
BA_ "GenSigSendType" SG_ 2654552144 FD14_Reserved10_b 1;
BA_ "GenSigSendType" SG_ 2654552144 FD14_PDC_FrontCenter_Yellow_b 1;
BA_ "GenSigSendType" SG_ 2654552144 FD14_PDC_FrontCenter_Red_b 1;
BA_ "GenSigSendType" SG_ 2654552144 FD14_Reserved09_b 1;
BA_ "GenSigSendType" SG_ 2654552144 FD14_PDC_FrontRight_Yellow_b 1;
BA_ "GenSigSendType" SG_ 2654552144 FD14_PDC_FrontRight_Red_b 1;
BA_ "GenSigSendType" SG_ 2654552144 FD14_Reserved08_b 1;
BA_ "GenSigSendType" SG_ 2654552144 FD14_PDC_RearLeft_Yellow_b 1;
BA_ "GenSigSendType" SG_ 2654552144 FD14_PDC_RearLeft_Red_b 1;
BA_ "GenSigSendType" SG_ 2654552144 FD14_SrvLayout_b 1;
BA_ "GenSigSendType" SG_ 2654552144 FD14_SrvStAngIndOk_b 1;
BA_ "GenSigSendType" SG_ 2654552144 FD14_SrvStAngIndNok_b 1;
BA_ "GenSigSendType" SG_ 2654552144 FD14_SrvSpOmIndOk_b 1;
BA_ "GenSigSendType" SG_ 2654552144 FD14_SrvSpOmIndNok_b 1;
BA_ "GenSigSendType" SG_ 2654552144 FD14_SrvChkIndRun_b 1;
BA_ "GenSigSendType" SG_ 2654552144 FD14_SrvChkIndOk_b 1;
BA_ "GenSigSendType" SG_ 2654552144 FD14_SrvChkIndNok_b 1;
BA_ "GenSigSendType" SG_ 2654552144 FD14_SrvChkIndCondNok_b 1;
BA_ "GenSigSendType" SG_ 2654552144 FD14_SrvCamIndFrOk_b 1;
BA_ "GenSigSendType" SG_ 2654552144 FD14_SrvCamIndFrNok_b 1;
BA_ "GenSigSendType" SG_ 2654552144 FD14_SrvCamIndFrPend_b 1;
BA_ "GenSigSendType" SG_ 2654552144 FD14_SrvCamIndFrNone_b 1;
BA_ "GenSigSendType" SG_ 2654552144 FD14_SrvCamIndLeOk_b 1;
BA_ "GenSigSendType" SG_ 2654552144 FD14_SrvCamIndLeNok_b 1;
BA_ "GenSigSendType" SG_ 2654552144 FD14_SrvCamIndLePend_b 1;
BA_ "GenSigSendType" SG_ 2654552144 FD14_SrvCamIndLeNone_b 1;
BA_ "GenSigSendType" SG_ 2654552144 FD14_SrvCamIndBaOk_b 1;
BA_ "GenSigSendType" SG_ 2654552144 FD14_SrvCamIndBaNok_b 1;
BA_ "GenSigSendType" SG_ 2654552144 FD14_SrvCamIndBaPend_b 1;
BA_ "GenSigSendType" SG_ 2654552144 FD14_SrvCamIndBaNone_b 1;
BA_ "GenSigSendType" SG_ 2654552144 FD14_SrvCamIndRiOk_b 1;
BA_ "GenSigSendType" SG_ 2654552144 FD14_SrvCamIndRiNok_b 1;
BA_ "GenSigSendType" SG_ 2654552144 FD14_SrvCamIndRiPend_b 1;
BA_ "GenSigSendType" SG_ 2654552144 FD14_SrvCamIndRiNone_b 1;
BA_ "GenSigSendType" SG_ 2654552144 FD14_SrvPrgBar0Per_b 1;
BA_ "GenSigSendType" SG_ 2654552144 FD14_SrvPrgBar20Per_b 1;
BA_ "GenSigSendType" SG_ 2654552144 FD14_SrvPrgBar40Per_b 1;
BA_ "GenSigSendType" SG_ 2654552144 FD14_SrvPrgBar60Per_b 1;
BA_ "GenSigSendType" SG_ 2654552144 FD14_SrvPrgBar80Per_b 1;
BA_ "GenSigSendType" SG_ 2654552144 FD14_SrvPrgBar100Per_b 1;
BA_ "GenSigSendType" SG_ 2654552144 FD14_TrscOvl 1;
BA_ "GenSigSendType" SG_ 2654552144 FD14_TrscJackKnifeOrange 1;
BA_ "GenSigSendType" SG_ 2654552144 FD14_TrscJackKnifeRed 1;
BA_ "GenSigSendType" SG_ 2654552144 FD14_TrscTrailerRed 1;
BA_ "GenSigSendType" SG_ 2654552144 FD14_THATriangleOverlay 1;
BA_ "GenSigSendType" SG_ 2654552144 FD14_THACouplerBulletIcon 1;
BA_ "GenSigSendType" SG_ 2654552144 FD14_THAButtonGrey 1;
BA_ "GenSigSendType" SG_ 2654552144 FD14_THAButtonSelectable 1;
BA_ "GenSigSendType" SG_ 2654552144 FD14_THAConfirmButton 1;
BA_ "GenSigSendType" SG_ 2654552144 FD14_THAStartButton 1;
BA_ "GenSigSendType" SG_ 2654552144 FD14_THAProgressBar 1;
BA_ "GenSigSendType" SG_ 2654552144 FD14_Reserved3_b 1;
BA_ "GenSigSendType" SG_ 2654552144 FD14_Reserved2_b 1;
BA_ "GenSigSendType" SG_ 2654552144 FD14_Reserved1_b 1;
BA_ "GenSigSendType" SG_ 2654552144 FD14_Reserved0_b 1;
BA_ "GenSigSendType" SG_ 2654552146 FD14_MePRX_b_TRSCPresence 1;
BA_ "GenSigStartValue" SG_ 2654552146 FD14_MePRX_b_TRSCPresence 1;
BA_ "GenSigSendType" SG_ 2654552146 FD14_MePRX_b_TRGPresence 1;
BA_ "GenSigStartValue" SG_ 2654552146 FD14_MePRX_b_TRGPresence 1;
BA_ "GenSigSendType" SG_ 2654552146 FD14_MePRX_b_CanNode27 1;
BA_ "GenSigStartValue" SG_ 2654552146 FD14_MePRX_b_CanNode27 1;
BA_ "GenSigSendType" SG_ 2654552146 FD14_MePRX_b_CANNode95 1;
BA_ "GenSigStartValue" SG_ 2654552146 FD14_MePRX_b_CANNode95 1;
BA_ "GenSigSendType" SG_ 2654552146 FD14_MePRX_b_AuxTrlrCam 1;
BA_ "GenSigStartValue" SG_ 2654552146 FD14_MePRX_b_AuxTrlrCam 1;
BA_ "GenSigSendType" SG_ 2654552146 FD14_MePRX_b_FrwFacingCam 1;
BA_ "GenSigStartValue" SG_ 2654552146 FD14_MePRX_b_FrwFacingCam 1;
BA_ "GenSigSendType" SG_ 2654552146 FD14_MePRX_b_SurroundViewCamera 1;
BA_ "GenSigStartValue" SG_ 2654552146 FD14_MePRX_b_SurroundViewCamera 1;
BA_ "GenSigSendType" SG_ 2654552146 FD14_MePRX_e_AutonomyLvl 1;
BA_ "GenSigSendType" SG_ 2654552146 FD14_MePRX_e_PAMTunSet 1;
BA_ "GenSigSendType" SG_ 2654552146 FD14_MePRX_e_MirrorType 1;
BA_ "GenSigSendType" SG_ 2654552146 FD14_MePRX_e_RadDispType 1;
BA_ "GenSigSendType" SG_ 2654552146 FD14_MePRX_e_SteerRatRackPi_0000 1;
BA_ "SystemSignalLongSymbol" SG_ 2654552146 FD14_MePRX_e_SteerRatRackPi_0000 "FD14_MePRX_e_SteerRatRackPinionType";
BA_ "GenSigSendType" SG_ 2654552146 FD14_MePRX_e_Wheelbase 1;
BA_ "GenSigSendType" SG_ 2654552146 FD14_MePRX_e_VehLineCfg 1;
BA_ "GenSigSendType" SG_ 2654552146 FD14_MePRX_e_VariantID 1;
BA_ "GenSigSendType" SG_ 2654552184 FD14_LMD_m_Line_2_End_Range 1;
BA_ "GenSigSendType" SG_ 2654552184 FD14_LMD_m_Line_2_Start_Range 1;
BA_ "GenSigSendType" SG_ 2654552184 FD14_LMD_rad_Line_2_Heading 1;
BA_ "GenSigSendType" SG_ 2654552184 FD14_LMD_m_Line_2_Offset 1;
BA_ "GenSigSendType" SG_ 2654552184 FD14_LMD_e_Line_2_Type 1;
BA_ "GenSigSendType" SG_ 2654552184 FD14_LMD_pct_Line_2_Confidence 1;
BA_ "GenSigSendType" SG_ 2654552184 FD14_LMD_px_Line_2_Curvature 1;
BA_ "GenSigSendType" SG_ 2654552184 FD14_LMD_m_Line_1_End_Range 1;
BA_ "GenSigSendType" SG_ 2654552184 FD14_LMD_m_Line_1_Start_Range 1;
BA_ "GenSigSendType" SG_ 2654552184 FD14_LMD_rad_Line_1_Heading 1;
BA_ "GenSigSendType" SG_ 2654552184 FD14_LMD_m_Line_1_Offset 1;
BA_ "GenSigSendType" SG_ 2654552184 FD14_LMD_e_Line_1_Type 1;
BA_ "GenSigSendType" SG_ 2654552184 FD14_LMD_px_Line_1_Curvature 1;
BA_ "GenSigSendType" SG_ 2654552184 FD14_LMD_pct_Line_1_Confidence 1;
BA_ "GenSigSendType" SG_ 2654552321 FD14_LMD_e_Line_4_Type 1;
BA_ "GenSigSendType" SG_ 2654552321 FD14_LMD_e_Line_3_Type 1;
BA_ "GenSigSendType" SG_ 2654552321 FD14_LMD_pct_Line_3_Confidence 1;
BA_ "GenSigSendType" SG_ 2654552321 FD14_LMD_px_Line_3_Curvature 1;
BA_ "GenSigSendType" SG_ 2654552321 FD14_LMD_m_Line_4_End_Range 1;
BA_ "GenSigSendType" SG_ 2654552321 FD14_LMD_m_Line_4_Start_Range 1;
BA_ "GenSigSendType" SG_ 2654552321 FD14_LMD_rad_Line_4_Heading 1;
BA_ "GenSigSendType" SG_ 2654552321 FD14_LMD_m_Line_4_Offset 1;
BA_ "GenSigSendType" SG_ 2654552321 FD14_LMD_pct_Line_4_Confidence 1;
BA_ "GenSigSendType" SG_ 2654552321 FD14_LMD_px_Line_4_Curvature 1;
BA_ "GenSigSendType" SG_ 2654552321 FD14_LMD_m_Line_3_End_Range 1;
BA_ "GenSigSendType" SG_ 2654552321 FD14_LMD_m_Line_3_Start_Range 1;
BA_ "GenSigSendType" SG_ 2654552321 FD14_LMD_rad_Line_3_Heading 1;
BA_ "GenSigSendType" SG_ 2654552321 FD14_LMD_m_Line_3_Offset 1;
BA_ "GenSigSendType" SG_ 2654552322 FD14_LMD_m_Segment_5_Y1 1;
BA_ "GenSigSendType" SG_ 2654552322 FD14_LMD_m_Segment_4_Y1 1;
BA_ "GenSigSendType" SG_ 2654552322 FD14_LMD_m_Segment_3_Y1 1;
BA_ "GenSigSendType" SG_ 2654552322 FD14_LMD_m_Segment_2_Y1 1;
BA_ "GenSigSendType" SG_ 2654552322 FD14_LMD_m_Segment_1_Y1 1;
BA_ "GenSigSendType" SG_ 2654552322 FD14_LMD_m_Segment_8_X1 1;
BA_ "GenSigSendType" SG_ 2654552322 FD14_LMD_m_Segment_6_X1 1;
BA_ "GenSigSendType" SG_ 2654552322 FD14_LMD_m_Segment_7_X1 1;
BA_ "GenSigSendType" SG_ 2654552322 FD14_LMD_m_Segment_5_X1 1;
BA_ "GenSigSendType" SG_ 2654552322 FD14_LMD_m_Segment_4_X1 1;
BA_ "GenSigSendType" SG_ 2654552322 FD14_LMD_m_Segment_3_X1 1;
BA_ "GenSigSendType" SG_ 2654552322 FD14_LMD_m_Segment_2_X1 1;
BA_ "GenSigSendType" SG_ 2654552322 FD14_LMD_m_Segment_1_X1 1;
BA_ "GenSigSendType" SG_ 2654552322 FD14_LMD_e_Segment_7_ID 1;
BA_ "GenSigSendType" SG_ 2654552322 FD14_LMD_e_Segment_8_ID 1;
BA_ "GenSigSendType" SG_ 2654552322 FD14_LMD_e_Segment_5_ID 1;
BA_ "GenSigSendType" SG_ 2654552322 FD14_LMD_e_Segment_6_ID 1;
BA_ "GenSigSendType" SG_ 2654552322 FD14_LMD_e_Segment_3_ID 1;
BA_ "GenSigSendType" SG_ 2654552322 FD14_LMD_e_Segment_4_ID 1;
BA_ "GenSigSendType" SG_ 2654552322 FD14_LMD_e_Segment_1_ID 1;
BA_ "GenSigSendType" SG_ 2654552322 FD14_LMD_e_Segment_2_ID 1;
BA_ "GenSigSendType" SG_ 2654552323 FD14_LMD_m_Segment_8_Y1 1;
BA_ "GenSigSendType" SG_ 2654552323 FD14_LMD_m_Segment_7_Y1 1;
BA_ "GenSigSendType" SG_ 2654552323 FD14_LMD_m_Segment_6_Y1 1;
BA_ "GenSigSendType" SG_ 2654552324 FD14_LMD_m_Segment_8_Y2 1;
BA_ "GenSigSendType" SG_ 2654552324 FD14_LMD_m_Segment_7_Y2 1;
BA_ "GenSigSendType" SG_ 2654552324 FD14_LMD_m_Segment_6_Y2 1;
BA_ "GenSigSendType" SG_ 2654552324 FD14_LMD_m_Segment_5_Y2 1;
BA_ "GenSigSendType" SG_ 2654552324 FD14_LMD_m_Segment_4_Y2 1;
BA_ "GenSigSendType" SG_ 2654552324 FD14_LMD_m_Segment_3_Y2 1;
BA_ "GenSigSendType" SG_ 2654552324 FD14_LMD_m_Segment_2_Y2 1;
BA_ "GenSigSendType" SG_ 2654552324 FD14_LMD_m_Segment_1_Y2 1;
BA_ "GenSigSendType" SG_ 2654552324 FD14_LMD_m_Segment_8_X2 1;
BA_ "GenSigSendType" SG_ 2654552324 FD14_LMD_m_Segment_7_X2 1;
BA_ "GenSigSendType" SG_ 2654552324 FD14_LMD_m_Segment_6_X2 1;
BA_ "GenSigSendType" SG_ 2654552324 FD14_LMD_m_Segment_5_X2 1;
BA_ "GenSigSendType" SG_ 2654552324 FD14_LMD_m_Segment_4_X2 1;
BA_ "GenSigSendType" SG_ 2654552324 FD14_LMD_m_Segment_3_X2 1;
BA_ "GenSigSendType" SG_ 2654552324 FD14_LMD_m_Segment_2_X2 1;
BA_ "GenSigSendType" SG_ 2654552324 FD14_LMD_m_Segment_1_X2 1;
BA_ "GenSigSendType" SG_ 2654552325 FD14_leLMD_e_HealthStatus 1;
BA_ "GenSigSendType" SG_ 2654552325 FD14_IeLMD_e_CameraStatus 1;
BA_ "GenSigSendType" SG_ 2654552325 FD14_Total_lines_count 1;
BA_ "GenSigSendType" SG_ 2654552325 FD14_Frame_Index_Lanes__1 1;
BA_ "GenSigSendType" SG_ 2654552325 FD14_LMD_pct_Segment_7_Confidenc 1;
BA_ "SystemSignalLongSymbol" SG_ 2654552325 FD14_LMD_pct_Segment_7_Confidenc "FD14_LMD_pct_Segment_7_Confidence";
BA_ "GenSigSendType" SG_ 2654552325 FD14_LMD_pct_Segment_8_Confidenc 1;
BA_ "SystemSignalLongSymbol" SG_ 2654552325 FD14_LMD_pct_Segment_8_Confidenc "FD14_LMD_pct_Segment_8_Confidence";
BA_ "GenSigSendType" SG_ 2654552325 FD14_LMD_pct_Segment_5_Confidenc 1;
BA_ "SystemSignalLongSymbol" SG_ 2654552325 FD14_LMD_pct_Segment_5_Confidenc "FD14_LMD_pct_Segment_5_Confidence";
BA_ "GenSigSendType" SG_ 2654552325 FD14_LMD_pct_Segment_6_Confidenc 1;
BA_ "SystemSignalLongSymbol" SG_ 2654552325 FD14_LMD_pct_Segment_6_Confidenc "FD14_LMD_pct_Segment_6_Confidence";
BA_ "GenSigSendType" SG_ 2654552325 FD14_LMD_pct_Segment_3_Confidenc 1;
BA_ "SystemSignalLongSymbol" SG_ 2654552325 FD14_LMD_pct_Segment_3_Confidenc "FD14_LMD_pct_Segment_3_Confidence";
BA_ "GenSigSendType" SG_ 2654552325 FD14_LMD_pct_Segment_4_Confidenc 1;
BA_ "SystemSignalLongSymbol" SG_ 2654552325 FD14_LMD_pct_Segment_4_Confidenc "FD14_LMD_pct_Segment_4_Confidence";
BA_ "GenSigSendType" SG_ 2654552325 FD14_LMD_pct_Segment_1_Confidenc 1;
BA_ "SystemSignalLongSymbol" SG_ 2654552325 FD14_LMD_pct_Segment_1_Confidenc "FD14_LMD_pct_Segment_1_Confidence";
BA_ "GenSigSendType" SG_ 2654552325 FD14_LMD_pct_Segment_2_Confidenc 1;
BA_ "SystemSignalLongSymbol" SG_ 2654552325 FD14_LMD_pct_Segment_2_Confidenc "FD14_LMD_pct_Segment_2_Confidence";
BA_ "GenSigSendType" SG_ 2654814230 FD14_Log_SnrMeasData_1 1;
BA_ "GenSigSendType" SG_ 2654814231 FD14_Log_SnrMeasData_2 1;
BA_ "GenSigSendType" SG_ 2654814247 FD14_Log_SnrMeasData_3 1;
BA_ "GenSigSendType" SG_ 2654814233 FD14_Log_SnrMeasData_4 1;
BA_ "GenSigSendType" SG_ 2654814234 FD14_Log_SnrMeasData_5 1;
BA_ "GenSigSendType" SG_ 2654814235 FD14_Log_SnrMeasData_6 1;
BA_ "GenSigSendType" SG_ 2654814236 FD14_Log_SnrMeasData_7 1;
BA_ "GenSigSendType" SG_ 2654814236 FD14_SnrMeasDataChecksum 1;
BA_ "GenSigSendType" SG_ 2654814237 FD14_Log_Sensor_Temperature 1;
BA_ "GenSigSendType" SG_ 2654552337 FD14_Tstr_SD_FSR_DrvFreq 1;
BA_ "GenSigSendType" SG_ 2654552337 FD14_Tstr_SD_FSR_RingFreq 1;
BA_ "GenSigSendType" SG_ 2654552337 FD14_Tstr_SD_FSR_Ringtime_us 1;
BA_ "GenSigSendType" SG_ 2654552337 FD14_Tstr_SD_FSR_Unfiltered_DirD 1;
BA_ "SystemSignalLongSymbol" SG_ 2654552337 FD14_Tstr_SD_FSR_Unfiltered_DirD "FD14_Tstr_SD_FSR_Unfiltered_DirDist1_";
BA_ "GenSigSendType" SG_ 2654552337 FD14_Tstr_SD_FSR_Unfiltered_0000 1;
BA_ "SystemSignalLongSymbol" SG_ 2654552337 FD14_Tstr_SD_FSR_Unfiltered_0000 "FD14_Tstr_SD_FSR_Unfiltered_DirDist2_";
BA_ "GenSigSendType" SG_ 2654552337 FD14_Tstr_SD_FSR_EchoHeight_adc 1;
BA_ "GenSigSendType" SG_ 2654552337 FD14_Tstr_SD_FSR_SensorBlkgSetCo 1;
BA_ "SystemSignalLongSymbol" SG_ 2654552337 FD14_Tstr_SD_FSR_SensorBlkgSetCo "FD14_Tstr_SD_FSR_SensorBlkgSetCounter";
BA_ "GenSigSendType" SG_ 2654552337 FD14_Tstr_SD_FSR_SensorBlkgClrCo 1;
BA_ "SystemSignalLongSymbol" SG_ 2654552337 FD14_Tstr_SD_FSR_SensorBlkgClrCo "FD14_Tstr_SD_FSR_SensorBlkgClrCounter";
BA_ "GenSigSendType" SG_ 2654552337 FD14_Tstr_SD_FOR_DrvFreq 1;
BA_ "GenSigSendType" SG_ 2654552337 FD14_Tstr_SD_FOR_RingFreq 1;
BA_ "GenSigSendType" SG_ 2654552337 FD14_Tstr_SD_FOR_Ringtime_us 1;
BA_ "GenSigSendType" SG_ 2654552337 FD14_Tstr_SD_FOR_Unfiltered_DirD 1;
BA_ "SystemSignalLongSymbol" SG_ 2654552337 FD14_Tstr_SD_FOR_Unfiltered_DirD "FD14_Tstr_SD_FOR_Unfiltered_DirDist1_";
BA_ "GenSigSendType" SG_ 2654552337 FD14_Tstr_SD_FOR_Unfiltered_0000 1;
BA_ "SystemSignalLongSymbol" SG_ 2654552337 FD14_Tstr_SD_FOR_Unfiltered_0000 "FD14_Tstr_SD_FOR_Unfiltered_DirDist2_";
BA_ "GenSigSendType" SG_ 2654552337 FD14_Tstr_SD_FOR_EchoHeight_adc 1;
BA_ "GenSigSendType" SG_ 2654552337 FD14_Tstr_SD_FOR_SensorBlkgSetCo 1;
BA_ "SystemSignalLongSymbol" SG_ 2654552337 FD14_Tstr_SD_FOR_SensorBlkgSetCo "FD14_Tstr_SD_FOR_SensorBlkgSetCounter";
BA_ "GenSigSendType" SG_ 2654552337 FD14_Tstr_SD_FOR_SensorBlkgClrCo 1;
BA_ "SystemSignalLongSymbol" SG_ 2654552337 FD14_Tstr_SD_FOR_SensorBlkgClrCo "FD14_Tstr_SD_FOR_SensorBlkgClrCounter";
BA_ "GenSigSendType" SG_ 2654552337 FD14_Tstr_SD_FIR_DrvFreq 1;
BA_ "GenSigSendType" SG_ 2654552337 FD14_Tstr_SD_FIR_RingFreq 1;
BA_ "GenSigSendType" SG_ 2654552337 FD14_Tstr_SD_FIR_Ringtime_us 1;
BA_ "GenSigSendType" SG_ 2654552337 FD14_Tstr_SD_FIR_Unfiltered_DirD 1;
BA_ "SystemSignalLongSymbol" SG_ 2654552337 FD14_Tstr_SD_FIR_Unfiltered_DirD "FD14_Tstr_SD_FIR_Unfiltered_DirDist1_";
BA_ "GenSigSendType" SG_ 2654552337 FD14_Tstr_SD_FIR_Unfiltered_0000 1;
BA_ "SystemSignalLongSymbol" SG_ 2654552337 FD14_Tstr_SD_FIR_Unfiltered_0000 "FD14_Tstr_SD_FIR_Unfiltered_DirDist2_";
BA_ "GenSigSendType" SG_ 2654552337 FD14_Tstr_SD_FIR_EchoHeight_adc 1;
BA_ "GenSigSendType" SG_ 2654552337 FD14_Tstr_SD_FIR_SensorBlkgSetCo 1;
BA_ "SystemSignalLongSymbol" SG_ 2654552337 FD14_Tstr_SD_FIR_SensorBlkgSetCo "FD14_Tstr_SD_FIR_SensorBlkgSetCounter";
BA_ "GenSigSendType" SG_ 2654552337 FD14_Tstr_SD_FIR_SensorBlkgClrCo 1;
BA_ "SystemSignalLongSymbol" SG_ 2654552337 FD14_Tstr_SD_FIR_SensorBlkgClrCo "FD14_Tstr_SD_FIR_SensorBlkgClrCounter";
BA_ "GenSigSendType" SG_ 2654552337 FD14_Tstr_SD_FIL_DrvFreq 1;
BA_ "GenSigSendType" SG_ 2654552337 FD14_Tstr_SD_FIL_RingFreq 1;
BA_ "GenSigSendType" SG_ 2654552337 FD14_Tstr_SD_FIL_Ringtime_us 1;
BA_ "GenSigSendType" SG_ 2654552337 FD14_Tstr_SD_FIL_Unfiltered_DirD 1;
BA_ "SystemSignalLongSymbol" SG_ 2654552337 FD14_Tstr_SD_FIL_Unfiltered_DirD "FD14_Tstr_SD_FIL_Unfiltered_DirDist1_";
BA_ "GenSigSendType" SG_ 2654552337 FD14_Tstr_SD_FIL_Unfiltered_0000 1;
BA_ "SystemSignalLongSymbol" SG_ 2654552337 FD14_Tstr_SD_FIL_Unfiltered_0000 "FD14_Tstr_SD_FIL_Unfiltered_DirDist2_";
BA_ "GenSigSendType" SG_ 2654552337 FD14_Tstr_SD_FIL_EchoHeight_adc 1;
BA_ "GenSigSendType" SG_ 2654552337 FD14_Tstr_SD_FIL_SensorBlkgSetCo 1;
BA_ "SystemSignalLongSymbol" SG_ 2654552337 FD14_Tstr_SD_FIL_SensorBlkgSetCo "FD14_Tstr_SD_FIL_SensorBlkgSetCounter";
BA_ "GenSigSendType" SG_ 2654552337 FD14_Tstr_SD_FIL_SensorBlkgClrCo 1;
BA_ "SystemSignalLongSymbol" SG_ 2654552337 FD14_Tstr_SD_FIL_SensorBlkgClrCo "FD14_Tstr_SD_FIL_SensorBlkgClrCounter";
BA_ "GenSigSendType" SG_ 2654552338 FD14_Tstr_SD_FOL_DrvFreq 1;
BA_ "GenSigSendType" SG_ 2654552338 FD14_Tstr_SD_FOL_RingFreq 1;
BA_ "GenSigSendType" SG_ 2654552338 FD14_Tstr_SD_FOL_Ringtime_us 1;
BA_ "GenSigSendType" SG_ 2654552338 FD14_Tstr_SD_FOL_Unfiltered_DirD 1;
BA_ "SystemSignalLongSymbol" SG_ 2654552338 FD14_Tstr_SD_FOL_Unfiltered_DirD "FD14_Tstr_SD_FOL_Unfiltered_DirDist1_";
BA_ "GenSigSendType" SG_ 2654552338 FD14_Tstr_SD_FOL_Unfiltered_0000 1;
BA_ "SystemSignalLongSymbol" SG_ 2654552338 FD14_Tstr_SD_FOL_Unfiltered_0000 "FD14_Tstr_SD_FOL_Unfiltered_DirDist2_";
BA_ "GenSigSendType" SG_ 2654552338 FD14_Tstr_SD_FOL_EchoHeight_adc 1;
BA_ "GenSigSendType" SG_ 2654552338 FD14_Tstr_SD_FOL_SensorBlkgSetCo 1;
BA_ "SystemSignalLongSymbol" SG_ 2654552338 FD14_Tstr_SD_FOL_SensorBlkgSetCo "FD14_Tstr_SD_FOL_SensorBlkgSetCounter";
BA_ "GenSigSendType" SG_ 2654552338 FD14_Tstr_SD_FOL_SensorBlkgClrCo 1;
BA_ "SystemSignalLongSymbol" SG_ 2654552338 FD14_Tstr_SD_FOL_SensorBlkgClrCo "FD14_Tstr_SD_FOL_SensorBlkgClrCounter";
BA_ "GenSigSendType" SG_ 2654552338 FD14_Tstr_SD_FSL_DrvFreq 1;
BA_ "GenSigSendType" SG_ 2654552338 FD14_Tstr_SD_FSL_RingFreq 1;
BA_ "GenSigSendType" SG_ 2654552338 FD14_Tstr_SD_FSL_Ringtime_us 1;
BA_ "GenSigSendType" SG_ 2654552338 FD14_Tstr_SD_FSL_Unfiltered_DirD 1;
BA_ "SystemSignalLongSymbol" SG_ 2654552338 FD14_Tstr_SD_FSL_Unfiltered_DirD "FD14_Tstr_SD_FSL_Unfiltered_DirDist1_";
BA_ "GenSigSendType" SG_ 2654552338 FD14_Tstr_SD_FSL_Unfiltered_0000 1;
BA_ "SystemSignalLongSymbol" SG_ 2654552338 FD14_Tstr_SD_FSL_Unfiltered_0000 "FD14_Tstr_SD_FSL_Unfiltered_DirDist2_";
BA_ "GenSigSendType" SG_ 2654552338 FD14_Tstr_SD_FSL_EchoHeight_adc 1;
BA_ "GenSigSendType" SG_ 2654552338 FD14_Tstr_SD_FSL_SensorBlkgSetCo 1;
BA_ "SystemSignalLongSymbol" SG_ 2654552338 FD14_Tstr_SD_FSL_SensorBlkgSetCo "FD14_Tstr_SD_FSL_SensorBlkgSetCounter";
BA_ "GenSigSendType" SG_ 2654552338 FD14_Tstr_SD_FSL_SensorBlkgClrCo 1;
BA_ "SystemSignalLongSymbol" SG_ 2654552338 FD14_Tstr_SD_FSL_SensorBlkgClrCo "FD14_Tstr_SD_FSL_SensorBlkgClrCounter";
BA_ "GenSigSendType" SG_ 2654552338 FD14_Tstr_SD_RSR_DrvFreq 1;
BA_ "GenSigSendType" SG_ 2654552338 FD14_Tstr_SD_RSR_RingFreq 1;
BA_ "GenSigSendType" SG_ 2654552338 FD14_Tstr_SD_RSR_Ringtime_us 1;
BA_ "GenSigSendType" SG_ 2654552338 FD14_Tstr_SD_RSR_Unfiltered_DirD 1;
BA_ "SystemSignalLongSymbol" SG_ 2654552338 FD14_Tstr_SD_RSR_Unfiltered_DirD "FD14_Tstr_SD_RSR_Unfiltered_DirDist1_";
BA_ "GenSigSendType" SG_ 2654552338 FD14_Tstr_SD_RSR_Unfiltered_0000 1;
BA_ "SystemSignalLongSymbol" SG_ 2654552338 FD14_Tstr_SD_RSR_Unfiltered_0000 "FD14_Tstr_SD_RSR_Unfiltered_DirDist2_";
BA_ "GenSigSendType" SG_ 2654552338 FD14_Tstr_SD_RSR_EchoHeight_adc 1;
BA_ "GenSigSendType" SG_ 2654552338 FD14_Tstr_SD_RSR_SensorBlkgSetCo 1;
BA_ "SystemSignalLongSymbol" SG_ 2654552338 FD14_Tstr_SD_RSR_SensorBlkgSetCo "FD14_Tstr_SD_RSR_SensorBlkgSetCounter";
BA_ "GenSigSendType" SG_ 2654552338 FD14_Tstr_SD_RSR_SensorBlkgClrCo 1;
BA_ "SystemSignalLongSymbol" SG_ 2654552338 FD14_Tstr_SD_RSR_SensorBlkgClrCo "FD14_Tstr_SD_RSR_SensorBlkgClrCounter";
BA_ "GenSigSendType" SG_ 2654552338 FD14_Tstr_SD_ROR_DrvFreq 1;
BA_ "GenSigSendType" SG_ 2654552338 FD14_Tstr_SD_ROR_RingFreq 1;
BA_ "GenSigSendType" SG_ 2654552338 FD14_Tstr_SD_ROR_Ringtime_us 1;
BA_ "GenSigSendType" SG_ 2654552338 FD14_Tstr_SD_ROR_Unfiltered_DirD 1;
BA_ "SystemSignalLongSymbol" SG_ 2654552338 FD14_Tstr_SD_ROR_Unfiltered_DirD "FD14_Tstr_SD_ROR_Unfiltered_DirDist1_";
BA_ "GenSigSendType" SG_ 2654552338 FD14_Tstr_SD_ROR_Unfiltered_0000 1;
BA_ "SystemSignalLongSymbol" SG_ 2654552338 FD14_Tstr_SD_ROR_Unfiltered_0000 "FD14_Tstr_SD_ROR_Unfiltered_DirDist2_";
BA_ "GenSigSendType" SG_ 2654552338 FD14_Tstr_SD_ROR_EchoHeight_adc 1;
BA_ "GenSigSendType" SG_ 2654552338 FD14_Tstr_SD_ROR_SensorBlkgSetCo 1;
BA_ "SystemSignalLongSymbol" SG_ 2654552338 FD14_Tstr_SD_ROR_SensorBlkgSetCo "FD14_Tstr_SD_ROR_SensorBlkgSetCounter";
BA_ "GenSigSendType" SG_ 2654552338 FD14_Tstr_SD_ROR_SensorBlkgClrCo 1;
BA_ "SystemSignalLongSymbol" SG_ 2654552338 FD14_Tstr_SD_ROR_SensorBlkgClrCo "FD14_Tstr_SD_ROR_SensorBlkgClrCounter";
BA_ "GenSigSendType" SG_ 2654552339 FD14_Tstr_SD_RIR_DrvFreq 1;
BA_ "GenSigSendType" SG_ 2654552339 FD14_Tstr_SD_RIR_RingFreq 1;
BA_ "GenSigSendType" SG_ 2654552339 FD14_Tstr_SD_RIR_Ringtime_us 1;
BA_ "GenSigSendType" SG_ 2654552339 FD14_Tstr_SD_RIR_Unfiltered_DirD 1;
BA_ "SystemSignalLongSymbol" SG_ 2654552339 FD14_Tstr_SD_RIR_Unfiltered_DirD "FD14_Tstr_SD_RIR_Unfiltered_DirDist1_";
BA_ "GenSigSendType" SG_ 2654552339 FD14_Tstr_SD_RIR_Unfiltered_0000 1;
BA_ "SystemSignalLongSymbol" SG_ 2654552339 FD14_Tstr_SD_RIR_Unfiltered_0000 "FD14_Tstr_SD_RIR_Unfiltered_DirDist2_";
BA_ "GenSigSendType" SG_ 2654552339 FD14_Tstr_SD_RIR_EchoHeight_adc 1;
BA_ "GenSigSendType" SG_ 2654552339 FD14_Tstr_SD_RIR_SensorBlkgSetCo 1;
BA_ "SystemSignalLongSymbol" SG_ 2654552339 FD14_Tstr_SD_RIR_SensorBlkgSetCo "FD14_Tstr_SD_RIR_SensorBlkgSetCounter";
BA_ "GenSigSendType" SG_ 2654552339 FD14_Tstr_SD_RIR_SensorBlkgClrCo 1;
BA_ "SystemSignalLongSymbol" SG_ 2654552339 FD14_Tstr_SD_RIR_SensorBlkgClrCo "FD14_Tstr_SD_RIR_SensorBlkgClrCounter";
BA_ "GenSigSendType" SG_ 2654552339 FD14_Tstr_SD_RIL_DrvFreq 1;
BA_ "GenSigSendType" SG_ 2654552339 FD14_Tstr_SD_RIL_RingFreq 1;
BA_ "GenSigSendType" SG_ 2654552339 FD14_Tstr_SD_RIL_Ringtime_us 1;
BA_ "GenSigSendType" SG_ 2654552339 FD14_Tstr_SD_RIL_Unfiltered_DirD 1;
BA_ "SystemSignalLongSymbol" SG_ 2654552339 FD14_Tstr_SD_RIL_Unfiltered_DirD "FD14_Tstr_SD_RIL_Unfiltered_DirDist1_";
BA_ "GenSigSendType" SG_ 2654552339 FD14_Tstr_SD_RIL_Unfiltered_0000 1;
BA_ "SystemSignalLongSymbol" SG_ 2654552339 FD14_Tstr_SD_RIL_Unfiltered_0000 "FD14_Tstr_SD_RIL_Unfiltered_DirDist2_";
BA_ "GenSigSendType" SG_ 2654552339 FD14_Tstr_SD_RIL_EchoHeight_adc 1;
BA_ "GenSigSendType" SG_ 2654552339 FD14_Tstr_SD_RIL_SensorBlkgSetCo 1;
BA_ "SystemSignalLongSymbol" SG_ 2654552339 FD14_Tstr_SD_RIL_SensorBlkgSetCo "FD14_Tstr_SD_RIL_SensorBlkgSetCounter";
BA_ "GenSigSendType" SG_ 2654552339 FD14_Tstr_SD_RIL_SensorBlkgClrCo 1;
BA_ "SystemSignalLongSymbol" SG_ 2654552339 FD14_Tstr_SD_RIL_SensorBlkgClrCo "FD14_Tstr_SD_RIL_SensorBlkgClrCounter";
BA_ "GenSigSendType" SG_ 2654552339 FD14_Tstr_SD_ROL_DrvFreq 1;
BA_ "GenSigSendType" SG_ 2654552339 FD14_Tstr_SD_ROL_RingFreq 1;
BA_ "GenSigSendType" SG_ 2654552339 FD14_Tstr_SD_ROL_Ringtime_us 1;
BA_ "GenSigSendType" SG_ 2654552339 FD14_Tstr_SD_ROL_Unfiltered_DirD 1;
BA_ "SystemSignalLongSymbol" SG_ 2654552339 FD14_Tstr_SD_ROL_Unfiltered_DirD "FD14_Tstr_SD_ROL_Unfiltered_DirDist1_";
BA_ "GenSigSendType" SG_ 2654552339 FD14_Tstr_SD_ROL_Unfiltered_0000 1;
BA_ "SystemSignalLongSymbol" SG_ 2654552339 FD14_Tstr_SD_ROL_Unfiltered_0000 "FD14_Tstr_SD_ROL_Unfiltered_DirDist2_";
BA_ "GenSigSendType" SG_ 2654552339 FD14_Tstr_SD_ROL_EchoHeight_adc 1;
BA_ "GenSigSendType" SG_ 2654552339 FD14_Tstr_SD_ROL_SensorBlkgSetCo 1;
BA_ "SystemSignalLongSymbol" SG_ 2654552339 FD14_Tstr_SD_ROL_SensorBlkgSetCo "FD14_Tstr_SD_ROL_SensorBlkgSetCounter";
BA_ "GenSigSendType" SG_ 2654552339 FD14_Tstr_SD_ROL_SensorBlkgClrCo 1;
BA_ "SystemSignalLongSymbol" SG_ 2654552339 FD14_Tstr_SD_ROL_SensorBlkgClrCo "FD14_Tstr_SD_ROL_SensorBlkgClrCounter";
BA_ "GenSigSendType" SG_ 2654552339 FD14_Tstr_SD_RSL_DrvFreq 1;
BA_ "GenSigSendType" SG_ 2654552339 FD14_Tstr_SD_RSL_RingFreq 1;
BA_ "GenSigSendType" SG_ 2654552339 FD14_Tstr_SD_RSL_Ringtime_us 1;
BA_ "GenSigSendType" SG_ 2654552339 FD14_Tstr_SD_RSL_Unfiltered_DirD 1;
BA_ "SystemSignalLongSymbol" SG_ 2654552339 FD14_Tstr_SD_RSL_Unfiltered_DirD "FD14_Tstr_SD_RSL_Unfiltered_DirDist1_";
BA_ "GenSigSendType" SG_ 2654552339 FD14_Tstr_SD_RSL_Unfiltered_0000 1;
BA_ "SystemSignalLongSymbol" SG_ 2654552339 FD14_Tstr_SD_RSL_Unfiltered_0000 "FD14_Tstr_SD_RSL_Unfiltered_DirDist2_";
BA_ "GenSigSendType" SG_ 2654552339 FD14_Tstr_SD_RSL_EchoHeight_adc 1;
BA_ "GenSigSendType" SG_ 2654552339 FD14_Tstr_SD_RSL_SensorBlkgSetCo 1;
BA_ "SystemSignalLongSymbol" SG_ 2654552339 FD14_Tstr_SD_RSL_SensorBlkgSetCo "FD14_Tstr_SD_RSL_SensorBlkgSetCounter";
BA_ "GenSigSendType" SG_ 2654552339 FD14_Tstr_SD_RSL_SensorBlkgClrCo 1;
BA_ "SystemSignalLongSymbol" SG_ 2654552339 FD14_Tstr_SD_RSL_SensorBlkgClrCo "FD14_Tstr_SD_RSL_SensorBlkgClrCounter";
BA_ "GenSigSendType" SG_ 2654814238 FD14_Debug_Signal_4 1;
BA_ "GenSigSendType" SG_ 2654814238 FD14_Debug_Signal_3 1;
BA_ "GenSigSendType" SG_ 2654814238 FD14_Debug_Signal_2 1;
BA_ "GenSigSendType" SG_ 2654814238 FD14_Debug_Signal_1 1;
BA_ "GenSigSendType" SG_ 2654814240 FD14_Debug_Signal_6 1;
BA_ "GenSigSendType" SG_ 2654814240 FD14_Debug_Signal_8 1;
BA_ "GenSigSendType" SG_ 2654814240 FD14_Debug_Signal_7 1;
BA_ "GenSigSendType" SG_ 2654814240 FD14_Debug_Signal_5 1;
BA_ "GenSigSendType" SG_ 2654552352 FD14_Firing_Sensor_Info_F 1;
BA_ "GenSigSendType" SG_ 2654552352 FD14_SnrDat_FSR_Dir1_cm 1;
BA_ "GenSigSendType" SG_ 2654552352 FD14_SnrDat_FOR_Dir1_cm 1;
BA_ "GenSigSendType" SG_ 2654552352 FD14_SnrDat_FIR_Dir1_cm 1;
BA_ "GenSigSendType" SG_ 2654552352 FD14_SnrDat_FIL_Dir1_cm 1;
BA_ "GenSigSendType" SG_ 2654552352 FD14_SnrDat_FOL_Dir1_cm 1;
BA_ "GenSigSendType" SG_ 2654552352 FD14_SnrDat_FSL_Dir1_cm 1;
BA_ "GenSigSendType" SG_ 2654552344 FD14_SnrDat_FSR_Dir2_cm 1;
BA_ "GenSigSendType" SG_ 2654552344 FD14_SnrDat_FOR_Dir2_cm 1;
BA_ "GenSigSendType" SG_ 2654552344 FD14_SnrDat_FIR_Dir2_cm 1;
BA_ "GenSigSendType" SG_ 2654552344 FD14_SnrDat_FIL_Dir2_cm 1;
BA_ "GenSigSendType" SG_ 2654552344 FD14_SnrDat_FOL_Dir2_cm 1;
BA_ "GenSigSendType" SG_ 2654552344 FD14_SnrDat_FSL_Dir2_cm 1;
BA_ "GenSigSendType" SG_ 2654552342 FD14_SnrDat_sFSR_Indir_FOR_cm 1;
BA_ "GenSigSendType" SG_ 2654552342 FD14_SnrDat_sFOR_Indir_FSR_cm 1;
BA_ "GenSigSendType" SG_ 2654552342 FD14_SnrDat_sFOR_Indir_FIR_cm 1;
BA_ "GenSigSendType" SG_ 2654552342 FD14_SnrDat_sFIR_Indir_FOR_cm 1;
BA_ "GenSigSendType" SG_ 2654552342 FD14_SnrDat_sFIR_Indir_FIL_cm 1;
BA_ "GenSigSendType" SG_ 2654552342 FD14_SnrDat_sFIL_Indir_FIR_cm 1;
BA_ "GenSigSendType" SG_ 2654552340 FD14_SnrDat_sFIL_Indir_FOL_cm 1;
BA_ "GenSigSendType" SG_ 2654552340 FD14_SnrDat_sFOL_Indir_FIL_cm 1;
BA_ "GenSigSendType" SG_ 2654552340 FD14_SnrDat_sFOL_Indir_FSL_cm 1;
BA_ "GenSigSendType" SG_ 2654552340 FD14_SnrDat_sFSL_Indir_FOL_cm 1;
BA_ "GenSigSendType" SG_ 2654552353 FD14_Firing_Sensor_Info_R 1;
BA_ "GenSigSendType" SG_ 2654552353 FD14_SnrDat_RSR_Dir1_cm 1;
BA_ "GenSigSendType" SG_ 2654552353 FD14_SnrDat_ROR_Dir1_cm 1;
BA_ "GenSigSendType" SG_ 2654552353 FD14_SnrDat_RIR_Dir1_cm 1;
BA_ "GenSigSendType" SG_ 2654552353 FD14_SnrDat_RIL_Dir1_cm 1;
BA_ "GenSigSendType" SG_ 2654552353 FD14_SnrDat_ROL_Dir1_cm 1;
BA_ "GenSigSendType" SG_ 2654552353 FD14_SnrDat_RSL_Dir1_cm 1;
BA_ "GenSigSendType" SG_ 2654552345 FD14_SnrDat_RSR_Dir2_cm 1;
BA_ "GenSigSendType" SG_ 2654552345 FD14_SnrDat_ROR_Dir2_cm 1;
BA_ "GenSigSendType" SG_ 2654552345 FD14_SnrDat_RIR_Dir2_cm 1;
BA_ "GenSigSendType" SG_ 2654552345 FD14_SnrDat_RIL_Dir2_cm 1;
BA_ "GenSigSendType" SG_ 2654552345 FD14_SnrDat_ROL_Dir2_cm 1;
BA_ "GenSigSendType" SG_ 2654552345 FD14_SnrDat_RSL_Dir2_cm 1;
BA_ "GenSigSendType" SG_ 2654552343 FD14_SnrDat_sROL_Indir_RSL_cm 1;
BA_ "GenSigSendType" SG_ 2654552343 FD14_SnrDat_sRIR_Indir_RIL_cm 1;
BA_ "GenSigSendType" SG_ 2654552343 FD14_SnrDat_sRIL_Indir_RIR_cm 1;
BA_ "GenSigSendType" SG_ 2654552343 FD14_SnrDat_sRIL_Indir_ROL_cm 1;
BA_ "GenSigSendType" SG_ 2654552343 FD14_SnrDat_sROL_Indir_RIL_cm 1;
BA_ "GenSigSendType" SG_ 2654552343 FD14_SnrDat_sRSL_Indir_ROL_cm 1;
BA_ "GenSigSendType" SG_ 2654552341 FD14_SnrDat_sRSR_Indir_ROR_cm 1;
BA_ "GenSigSendType" SG_ 2654552341 FD14_SnrDat_sROR_Indir_RSR_cm 1;
BA_ "GenSigSendType" SG_ 2654552341 FD14_SnrDat_sROR_Indir_RIR_cm 1;
BA_ "GenSigSendType" SG_ 2654552341 FD14_SnrDat_sRIR_Indir_ROR_cm 1;
BA_ "GenSigSendType" SG_ 2654814243 FD14_TimeStamp_SystemStatus 1;
BA_ "GenSigSendType" SG_ 2654814243 FD14_SystemMode 1;
BA_ "GenSigSendType" SG_ 2654814243 FD14_SystemStatus 1;
BA_ "GenSigSendType" SG_ 2654814243 FD14_BumberStatus_Right_Side 1;
BA_ "GenSigSendType" SG_ 2654814243 FD14_BumberStatus_Left_Side 1;
BA_ "GenSigSendType" SG_ 2654814243 FD14_BumberStatus_Rear 1;
BA_ "GenSigSendType" SG_ 2654814243 FD14_BumberStatus_Front 1;
BA_ "GenSigSendType" SG_ 2654814270 FD14_RSR_MinDistance 1;
BA_ "GenSigSendType" SG_ 2654814270 FD14_FSL_MinDistance 1;
BA_ "GenSigSendType" SG_ 2654814270 FD14_FOL_MinDistance 1;
BA_ "GenSigSendType" SG_ 2654814270 FD14_FIL_MinDistance 1;
BA_ "GenSigSendType" SG_ 2654814270 FD14_FIR_MinDistance 1;
BA_ "GenSigSendType" SG_ 2654814270 FD14_FOR_MinDistance 1;
BA_ "GenSigSendType" SG_ 2654814270 FD14_FSR_MinDistance 1;
BA_ "GenSigSendType" SG_ 2654814271 FD14_BOL_MinDistance 1;
BA_ "GenSigSendType" SG_ 2654814271 FD14_AOL_MinDistance 1;
BA_ "GenSigSendType" SG_ 2654814271 FD14_RSL_MinDistance 1;
BA_ "GenSigSendType" SG_ 2654814271 FD14_ROL_MinDistance 1;
BA_ "GenSigSendType" SG_ 2654814271 FD14_RIL_MinDistance 1;
BA_ "GenSigSendType" SG_ 2654814271 FD14_RIR_MinDistance 1;
BA_ "GenSigSendType" SG_ 2654814271 FD14_ROR_MinDistance 1;
BA_ "GenSigSendType" SG_ 2654814272 FD14_MinDistance_TimeStamp 1;
BA_ "GenSigSendType" SG_ 2654814272 FD14_BOR_MinDistance 1;
BA_ "GenSigSendType" SG_ 2654814272 FD14_AOR_MinDistance 1;
BA_ "GenSigSendType" SG_ 2654552179 FD14_MOT_ObjValid_1 1;
BA_ "GenSigSendType" SG_ 2654552179 FD14_MOT_ObjValid_0 1;
BA_ "GenSigSendType" SG_ 2654552179 FD14_MOT_ObjectDimensions_1_1 1;
BA_ "GenSigSendType" SG_ 2654552179 FD14_MOT_ObjectDimensions_0_1 1;
BA_ "GenSigSendType" SG_ 2654552179 FD14_MOT_ObjVelY_1 1;
BA_ "GenSigSendType" SG_ 2654552179 FD14_MOT_ObjVelX_1 1;
BA_ "GenSigSendType" SG_ 2654552179 FD14_MOT_ClosestPntDist_1_1 1;
BA_ "GenSigSendType" SG_ 2654552179 FD14_MOT_ClosestPntDist_0_1 1;
BA_ "GenSigSendType" SG_ 2654552179 FD14_MOT_ObjectDimensions_1_0 1;
BA_ "GenSigSendType" SG_ 2654552179 FD14_MOT_ObjectDimensions_0_0 1;
BA_ "GenSigSendType" SG_ 2654552179 FD14_MOT_ObjVelY_0 1;
BA_ "GenSigSendType" SG_ 2654552179 FD14_MOT_ObjVelX_0 1;
BA_ "GenSigSendType" SG_ 2654552179 FD14_MOT_ClosestPntDist_1_0 1;
BA_ "GenSigSendType" SG_ 2654552179 FD14_MOT_ClosestPntDist_0_0 1;
BA_ "GenSigSendType" SG_ 2654552180 FD14_MOT_ObjectDimensions_1_3 1;
BA_ "GenSigSendType" SG_ 2654552180 FD14_MOT_ObjectDimensions_0_3 1;
BA_ "GenSigSendType" SG_ 2654552180 FD14_MOT_ObjVelY_3 1;
BA_ "GenSigSendType" SG_ 2654552180 FD14_MOT_ObjVelX_3 1;
BA_ "GenSigSendType" SG_ 2654552180 FD14_MOT_ClosestPntDist_1_3 1;
BA_ "GenSigSendType" SG_ 2654552180 FD14_MOT_ClosestPntDist_0_3 1;
BA_ "GenSigSendType" SG_ 2654552180 FD14_MOT_ObjectDimensions_1_2 1;
BA_ "GenSigSendType" SG_ 2654552180 FD14_MOT_ObjectDimensions_0_2 1;
BA_ "GenSigSendType" SG_ 2654552180 FD14_MOT_ObjVelY_2 1;
BA_ "GenSigSendType" SG_ 2654552180 FD14_MOT_ObjVelX_2 1;
BA_ "GenSigSendType" SG_ 2654552180 FD14_MOT_ClosestPntDist_1_2 1;
BA_ "GenSigSendType" SG_ 2654552180 FD14_MOT_ClosestPntDist_0_2 1;
BA_ "GenSigSendType" SG_ 2654552180 FD14_MOT_ObjValid_3 1;
BA_ "GenSigSendType" SG_ 2654552180 FD14_MOT_ObjValid_2 1;
BA_ "GenSigSendType" SG_ 2654552181 FD14_MOT_ObjectDimensions_1_5 1;
BA_ "GenSigSendType" SG_ 2654552181 FD14_MOT_ObjectDimensions_0_5 1;
BA_ "GenSigSendType" SG_ 2654552181 FD14_MOT_ObjVelY_5 1;
BA_ "GenSigSendType" SG_ 2654552181 FD14_MOT_ObjVelX_5 1;
BA_ "GenSigSendType" SG_ 2654552181 FD14_MOT_ClosestPntDist_1_5 1;
BA_ "GenSigSendType" SG_ 2654552181 FD14_MOT_ClosestPntDist_0_5 1;
BA_ "GenSigSendType" SG_ 2654552181 FD14_MOT_ObjectDimensions_1_4 1;
BA_ "GenSigSendType" SG_ 2654552181 FD14_MOT_ObjectDimensions_0_4 1;
BA_ "GenSigSendType" SG_ 2654552181 FD14_MOT_ObjVelY_4 1;
BA_ "GenSigSendType" SG_ 2654552181 FD14_MOT_ObjVelX_4 1;
BA_ "GenSigSendType" SG_ 2654552181 FD14_MOT_ClosestPntDist_1_4 1;
BA_ "GenSigSendType" SG_ 2654552181 FD14_MOT_ClosestPntDist_0_4 1;
BA_ "GenSigSendType" SG_ 2654552181 FD14_MOT_ObjValid_5 1;
BA_ "GenSigSendType" SG_ 2654552181 FD14_MOT_ObjValid_4 1;
BA_ "GenSigSendType" SG_ 2654552182 FD14_MOT_ObjectDimensions_1_7 1;
BA_ "GenSigSendType" SG_ 2654552182 FD14_MOT_ObjectDimensions_0_7 1;
BA_ "GenSigSendType" SG_ 2654552182 FD14_MOT_ObjVelY_7 1;
BA_ "GenSigSendType" SG_ 2654552182 FD14_MOT_ObjVelX_7 1;
BA_ "GenSigSendType" SG_ 2654552182 FD14_MOT_ClosestPntDist_1_7 1;
BA_ "GenSigSendType" SG_ 2654552182 FD14_MOT_ClosestPntDist_0_7 1;
BA_ "GenSigSendType" SG_ 2654552182 FD14_MOT_ObjectDimensions_1_6 1;
BA_ "GenSigSendType" SG_ 2654552182 FD14_MOT_ObjectDimensions_0_6 1;
BA_ "GenSigSendType" SG_ 2654552182 FD14_MOT_ObjVelY_6 1;
BA_ "GenSigSendType" SG_ 2654552182 FD14_MOT_ObjVelX_6 1;
BA_ "GenSigSendType" SG_ 2654552182 FD14_MOT_ClosestPntDist_1_6 1;
BA_ "GenSigSendType" SG_ 2654552182 FD14_MOT_ClosestPntDist_0_6 1;
BA_ "GenSigSendType" SG_ 2654552182 FD14_MOT_ObjValid_7 1;
BA_ "GenSigSendType" SG_ 2654552182 FD14_MOT_ObjValid_6 1;
BA_ "GenSigSendType" SG_ 2654552183 FD14_MOT_ObjectDimensions_1_9 1;
BA_ "GenSigSendType" SG_ 2654552183 FD14_MOT_ObjectDimensions_0_9 1;
BA_ "GenSigSendType" SG_ 2654552183 FD14_MOT_ObjVelY_9 1;
BA_ "GenSigSendType" SG_ 2654552183 FD14_MOT_ObjVelX_9 1;
BA_ "GenSigSendType" SG_ 2654552183 FD14_MOT_ClosestPntDist_1_9 1;
BA_ "GenSigSendType" SG_ 2654552183 FD14_MOT_ClosestPntDist_0_9 1;
BA_ "GenSigSendType" SG_ 2654552183 FD14_MOT_ObjectDimensions_1_8 1;
BA_ "GenSigSendType" SG_ 2654552183 FD14_MOT_ObjectDimensions_0_8 1;
BA_ "GenSigSendType" SG_ 2654552183 FD14_MOT_ObjVelY_8 1;
BA_ "GenSigSendType" SG_ 2654552183 FD14_MOT_ObjVelX_8 1;
BA_ "GenSigSendType" SG_ 2654552183 FD14_MOT_ClosestPntDist_1_8 1;
BA_ "GenSigSendType" SG_ 2654552183 FD14_MOT_ClosestPntDist_0_8 1;
BA_ "GenSigSendType" SG_ 2654552183 FD14_MOT_ObjValid_9 1;
BA_ "GenSigSendType" SG_ 2654552183 FD14_MOT_ObjValid_8 1;
BA_ "GenSigSendType" SG_ 2654552326 FD14_stPLDParkingSlot4SlotType 1;
BA_ "GenSigSendType" SG_ 2654552326 FD14_stPLDParkingSlot4DataSlotSi 1;
BA_ "SystemSignalLongSymbol" SG_ 2654552326 FD14_stPLDParkingSlot4DataSlotSi "FD14_stPLDParkingSlot4DataSlotSide";
BA_ "GenSigSendType" SG_ 2654552326 FD14_stPLDParkingSlot4DataSlotID 1;
BA_ "GenSigSendType" SG_ 2654552326 FD14_stPLDParkingSlot4RearRightX 1;
BA_ "GenSigSendType" SG_ 2654552326 FD14_stPLDParkingSlot4RearRightY 1;
BA_ "GenSigSendType" SG_ 2654552326 FD14_stPLDParkingSlot4FrontLeftY 1;
BA_ "GenSigSendType" SG_ 2654552326 FD14_stPLDParkingSlot4FrontLeftX 1;
BA_ "GenSigSendType" SG_ 2654552326 FD14_stPLDParkingSlot1DataSlotID 1;
BA_ "GenSigSendType" SG_ 2654552326 FD14_stPLDParkingSlot1DataSlotSi 1;
BA_ "SystemSignalLongSymbol" SG_ 2654552326 FD14_stPLDParkingSlot1DataSlotSi "FD14_stPLDParkingSlot1DataSlotSide";
BA_ "GenSigSendType" SG_ 2654552326 FD14_stPLDParkingSlot1SlotType 1;
BA_ "GenSigSendType" SG_ 2654552326 FD14_stPLDParkingSlot1RearRightY 1;
BA_ "GenSigSendType" SG_ 2654552326 FD14_stPLDParkingSlot1RearRightX 1;
BA_ "GenSigSendType" SG_ 2654552326 FD14_stPLDParkingSlot1FrontLeftY 1;
BA_ "GenSigSendType" SG_ 2654552326 FD14_stPLDParkingSlot1FrontLeftX 1;
BA_ "GenSigSendType" SG_ 2654552326 FD14_stPLDParkingSlot6SlotValid 1;
BA_ "GenSigSendType" SG_ 2654552326 FD14_stPLDParkingSlot5SlotValid 1;
BA_ "GenSigSendType" SG_ 2654552326 FD14_stPLDParkingSlot3SlotValid 1;
BA_ "GenSigSendType" SG_ 2654552326 FD14_stPLDParkingSlot2SlotValid 1;
BA_ "GenSigSendType" SG_ 2654552326 FD14_stPLDParkingSlot4SlotValid 1;
BA_ "GenSigSendType" SG_ 2654552326 FD14_stPLDParkingSlot1SlotValid 1;
BA_ "GenSigSendType" SG_ 2654552326 FD14_isPLDInitSuccess_b 1;
BA_ "GenSigSendType" SG_ 2654552327 FD14_stPLDLockedSlotDataSlotVali 1;
BA_ "SystemSignalLongSymbol" SG_ 2654552327 FD14_stPLDLockedSlotDataSlotVali "FD14_stPLDLockedSlotDataSlotValid";
BA_ "GenSigSendType" SG_ 2654552327 FD14_stPLDLockedSlotDataSlotID 1;
BA_ "GenSigSendType" SG_ 2654552327 FD14_stPLDLockedSlotDataSlotSide 1;
BA_ "GenSigSendType" SG_ 2654552327 FD14_stPLDLockedSlotDataSlotType 1;
BA_ "GenSigSendType" SG_ 2654552327 FD14_stPLDLockedSlotDataRearRigh 1;
BA_ "SystemSignalLongSymbol" SG_ 2654552327 FD14_stPLDLockedSlotDataRearRigh "FD14_stPLDLockedSlotDataRearRightY";
BA_ "GenSigSendType" SG_ 2654552327 FD14_stPLDLockedSlotDataRea_0000 1;
BA_ "SystemSignalLongSymbol" SG_ 2654552327 FD14_stPLDLockedSlotDataRea_0000 "FD14_stPLDLockedSlotDataRearRightX";
BA_ "GenSigSendType" SG_ 2654552327 FD14_stPLDLockedSlotDataFrontLef 1;
BA_ "SystemSignalLongSymbol" SG_ 2654552327 FD14_stPLDLockedSlotDataFrontLef "FD14_stPLDLockedSlotDataFrontLeftY";
BA_ "GenSigSendType" SG_ 2654552327 FD14_stPLDLockedSlotDataFro_0000 1;
BA_ "SystemSignalLongSymbol" SG_ 2654552327 FD14_stPLDLockedSlotDataFro_0000 "FD14_stPLDLockedSlotDataFrontLeftX";
BA_ "GenSigSendType" SG_ 2654814273 FD14_Pntdebugdata_0 1;
BA_ "GenSigSendType" SG_ 2654814274 FD14_Pntdebugdata_1 1;
BA_ "GenSigSendType" SG_ 2654814275 FD14_Pntdebugdata_2 1;
BA_ "GenSigSendType" SG_ 2654814277 FD14_Pntdebugdata_3 1;
BA_ "GenSigSendType" SG_ 2654552185 FD14_MeTHA_deg_RoadWhlAng 1;
BA_ "GenSigSendType" SG_ 2654552185 FD14_MeTHA_b_THAAbortStatus 1;
BA_ "GenSigSendType" SG_ 2654552185 FD14_MeTHA_b_UsrCplrSelCnfm 1;
BA_ "GenSigSendType" SG_ 2654552185 FD14_MeTHA_b_UsrHitchCnfm 1;
BA_ "GenSigSendType" SG_ 2654552185 FD14_MeTHA_e_THAStateInfo 1;
BA_ "GenSigSendType" SG_ 2654552185 FD14_MeTHA_e_RearBrkSupprInfo 1;
BA_ "GenSigSendType" SG_ 2654552185 FD14_MeTHA_e_ScreenRequest 1;
BA_ "GenSigSendType" SG_ 2654552185 FD14_MeTHA_b_EnblRearParkAsstTrg 1;
BA_ "GenSigSendType" SG_ 2654552185 FD14_MeTHA_b_TrlrCplrStatus 1;
BA_ "GenSigSendType" SG_ 2654552185 FD14_IeTHA_e_PamChimeTyp 1;
BA_ "GenSigSendType" SG_ 2654552185 FD14_IeTHA_b_ChimeActvRhf 1;
BA_ "GenSigSendType" SG_ 2654552185 FD14_IeTHA_b_ChimeActvLhf 1;
BA_ "GenSigSendType" SG_ 2654552185 FD14_IeTHA_e_PamVol 1;
BA_ "GenSigSendType" SG_ 2654552192 FD14_MeTHA_px_CplrPntY 1;
BA_ "GenSigStartValue" SG_ 2654552192 FD14_MeTHA_px_CplrPntY 298;
BA_ "GenSigSendType" SG_ 2654552192 FD14_MeTHA_px_CplrPntX 1;
BA_ "GenSigStartValue" SG_ 2654552192 FD14_MeTHA_px_CplrPntX 327;
BA_ "GenSigSendType" SG_ 2654552192 FD14_MeTHA_px_HitchPntY 1;
BA_ "GenSigStartValue" SG_ 2654552192 FD14_MeTHA_px_HitchPntY 298;
BA_ "GenSigSendType" SG_ 2654552192 FD14_MeTHA_px_HitchPntX 1;
BA_ "GenSigStartValue" SG_ 2654552192 FD14_MeTHA_px_HitchPntX 327;
BA_ "GenSigSendType" SG_ 2654552192 FD14_MeTHA_pct_CplrTrckConf 1;
BA_ "GenSigSendType" SG_ 2654552192 FD14_MeTHA_pct_CplrDetConf 1;
BA_ "GenSigSendType" SG_ 2654552192 FD14_MeTHA_px_HitchCplrPixDiffLa 1;
BA_ "SystemSignalLongSymbol" SG_ 2654552192 FD14_MeTHA_px_HitchCplrPixDiffLa "FD14_MeTHA_px_HitchCplrPixDiffLat";
BA_ "GenSigSendType" SG_ 2654552192 FD14_MeTHA_px_HitchCplrPixDiffLo 1;
BA_ "SystemSignalLongSymbol" SG_ 2654552192 FD14_MeTHA_px_HitchCplrPixDiffLo "FD14_MeTHA_px_HitchCplrPixDiffLong";
BA_ "GenSigSendType" SG_ 2654552192 FD14_MeTHA_deg_CplrAng 1;
BA_ "GenSigSendType" SG_ 2654552192 FD14_MeTHA_e_CplrDetctStatus 1;
BA_ "GenSigSendType" SG_ 2654552192 FD14_MeTHA_e_HitchDetctStatus 1;
BA_ "GenSigSendType" SG_ 2654552151 FD14_ReservedTRSCSig2 1;
BA_ "GenSigSendType" SG_ 2654552151 FD14_ReservedTRSCSig1 1;
BA_ "GenSigSendType" SG_ 2654552151 FD14_MeTRSC_cnt_TRSCAliveCounter 1;
BA_ "GenSigSendType" SG_ 2654552151 FD14_MeTRSC_s_TRSCTimeTaken 1;
BA_ "GenSigSendType" SG_ 2654552151 FD14_MeTRSC_s_TRSCPeriodicity 1;
BA_ "GenSigSendType" SG_ 2654552151 FD14_IeTRSC_pct_TrlrRecogConf 1;
BA_ "GenSigSendType" SG_ 2654552151 FD14_IeTRSC_pct_TrlrTrackConf 1;
BA_ "GenSigSendType" SG_ 2654552151 FD14_MeTRSC_m_HitchLength 1;
BA_ "GenSigStartValue" SG_ 2654552151 FD14_MeTRSC_m_HitchLength 100000;
BA_ "GenSigSendType" SG_ 2654552151 FD14_IeTRSC_m_TrlrWhlBaseEff 1;
BA_ "GenSigSendType" SG_ 2654552151 FD14_IeTRSC_pct_TrlrDetConf 1;
BA_ "GenSigSendType" SG_ 2654552151 FD14_MeTRSC_deg_JackKnifeAngle 1;
BA_ "GenSigStartValue" SG_ 2654552151 FD14_MeTRSC_deg_JackKnifeAngle 5300;
BA_ "GenSigSendType" SG_ 2654552151 FD14_MeTRSC_m_TrailerBeamLen 1;
BA_ "GenSigStartValue" SG_ 2654552151 FD14_MeTRSC_m_TrailerBeamLen 100;
BA_ "GenSigSendType" SG_ 2654552151 FD14_MeTRSC_e_TrlrAngSign 1;
BA_ "GenSigSendType" SG_ 2654552151 FD14_MeTRSC_e_TrlrPrsntInfo 1;
BA_ "GenSigSendType" SG_ 2654552151 FD14_MeTRSC_e_TrlrRecogInfo 1;
BA_ "GenSigSendType" SG_ 2654552151 FD14_MeTRSC_e_TrlrCalInfo 1;
BA_ "GenSigSendType" SG_ 2654552151 FD14_MeSVS_b_MoreCamReqSts 1;
BA_ "GenSigSendType" SG_ 2654552151 FD14_MeTRSC_deg_JackknifeThrAngl 1;
BA_ "GenSigStartValue" SG_ 2654552151 FD14_MeTRSC_deg_JackknifeThrAngl 530;
BA_ "SystemSignalLongSymbol" SG_ 2654552151 FD14_MeTRSC_deg_JackknifeThrAngl "FD14_MeTRSC_deg_JackknifeThrAngle";
BA_ "GenSigSendType" SG_ 2654552151 FD14_MeTRSC_deg_TADAngleRate 1;
BA_ "GenSigSendType" SG_ 2654552151 FD14_MeTRSC_deg_MaxAllowedTADAng 1;
BA_ "SystemSignalLongSymbol" SG_ 2654552151 FD14_MeTRSC_deg_MaxAllowedTADAng "FD14_MeTRSC_deg_MaxAllowedTADAngle";
BA_ "GenSigSendType" SG_ 2654552151 FD14_MeTRSC_e_TrailerID 1;
BA_ "GenSigStartValue" SG_ 2654552151 FD14_MeTRSC_e_TrailerID 6;
BA_ "GenSigSendType" SG_ 2654552151 FD14_MeTRSC_e_CalFail 1;
BA_ "GenSigSendType" SG_ 2654552151 FD14_MeTRSC_e_TADCalibrationSubs 1;
BA_ "SystemSignalLongSymbol" SG_ 2654552151 FD14_MeTRSC_e_TADCalibrationSubs "FD14_MeTRSC_e_TADCalibrationSubstate";
BA_ "GenSigSendType" SG_ 2654552151 FD14_MeTRSC_e_TurnAroundSubState 1;
BA_ "GenSigSendType" SG_ 2654552151 FD14_MeTRSC_e_TADState 1;
BA_ "GenSigSendType" SG_ 2654552151 FD14_MeTRSC_deg_TADAngle 1;
BA_ "GenSigSendType" SG_ 2654552165 FD14_IeTRSC_e_TRSCAbortReas 1;
BA_ "GenSigSendType" SG_ 2654552165 FD14_MeTRSC_e_TRSCStat 1;
BA_ "GenSigSendType" SG_ 2654552165 FD14_IeTRSC_e_TrlrAngGrapOverSts 1;
BA_ "GenSigSendType" SG_ 2654552165 FD14_IeTRSC_e_TRSCUnavailReas 1;
BA_ "GenSigSendType" SG_ 2654552165 FD14_IeTRSC_e_CamBlockSts 1;
BA_ "GenSigSendType" SG_ 2654552165 FD14_IeTRSC_kph_VehSpeedVSOSig 1;
BA_ "GenSigSendType" SG_ 2654552165 FD14_IeTRSC_M_TRSCStrTrq 1;
BA_ "GenSigSendType" SG_ 2654552165 FD14_IeTRSC_deg_JackknifeThrAngl 1;
BA_ "SystemSignalLongSymbol" SG_ 2654552165 FD14_IeTRSC_deg_JackknifeThrAngl "FD14_IeTRSC_deg_JackknifeThrAngle";
BA_ "GenSigSendType" SG_ 2654552165 FD14_IeTRSC_deg_TADAngle 1;
BA_ "GenSigSendType" SG_ 2654552165 FD14_IeTRSC_deg_TrlrAngKnob 1;
BA_ "GenSigSendType" SG_ 2654552165 FD14_IeTRSC_e_TrlrRecogInfo 1;
BA_ "GenSigSendType" SG_ 2654552165 FD14_IeTRSC_e_TRSKMSts 1;
BA_ "GenSigSendType" SG_ 2654552165 FD14_IeTRSC_e_TRSKMCenBtnSts 1;
BA_ "GenSigSendType" SG_ 2654552165 FD14_IeTRSC_e_TRSKMBtnSts 1;
BA_ "GenSigSendType" SG_ 2654552165 FD14_IeTRSC_e_TrailerID 1;
BA_ "GenSigSendType" SG_ 2654552165 FD14_IeTRSC_e_GearShiftSts 1;
BA_ "GenSigSendType" SG_ 2654552165 FD14_IeTRSC_deg_FrntWhlAng 1;
BA_ "GenSigSendType" SG_ 2654552165 FD14_IeTRSC_e_TrlrPrsntSts 1;
BA_ "GenSigSendType" SG_ 2654552165 FD14_IeTRSC_e_TrlrPrsntFailReas 1;
BA_ "GenSigSendType" SG_ 2654552165 FD14_IeTRSC_e_TrlrCalibSts 1;
BA_ "GenSigSendType" SG_ 2654552165 FD14_IeTRSC_e_TrlrCalibManState 1;
BA_ "GenSigSendType" SG_ 2654552165 FD14_IeTRSC_e_TrlrCalibFailReas 1;
BA_ "GenSigSendType" SG_ 2654552165 FD14_IeTRSC_cnt_TrlrCalibPa_0000 1;
BA_ "SystemSignalLongSymbol" SG_ 2654552165 FD14_IeTRSC_cnt_TrlrCalibPa_0000 "FD14_IeTRSC_cnt_TrlrCalibPassCntCurr";
BA_ "GenSigSendType" SG_ 2654552165 FD14_IeTRSC_cnt_TrlrCalibPassCnt 1;
BA_ "GenSigSendType" SG_ 2654552165 FD14_IeTRSC_cnt_TrlrCalibFa_0000 1;
BA_ "SystemSignalLongSymbol" SG_ 2654552165 FD14_IeTRSC_cnt_TrlrCalibFa_0000 "FD14_IeTRSC_cnt_TrlrCalibFailCntCurr";
BA_ "GenSigSendType" SG_ 2654552165 FD14_IeTRSC_cnt_TrlrCalibFailCnt 1;
BA_ "GenSigSendType" SG_ 2654552165 FD14_IeTRSC_cnt_KnobPos 1;
VAL_ 2654552193 FD14_objConf_e 3 "Conf_High" 2 "Conf_Med" 1 "Conf_Low" 0 "Conf_None" ;
VAL_ 2654552193 FD14_FrontSensorDetHealth_e 3 "SNA" 2 "Not_Active_failure" 1 "Not_Active_blocked" 0 "Active" ;
VAL_ 2654552151 FD14_MeTRSC_e_TrlrAngSign 2 "None" 1 "Anticlockwise" 0 "Clockwise" ;
VAL_ 2654552151 FD14_MeTRSC_e_TrlrPrsntInfo 2 "TRLR_PRSNT" 1 "NO_TRLR" 0 "UNKNOWN" ;
VAL_ 2654552151 FD14_MeTRSC_e_TrlrRecogInfo 1 "Known" 0 "Unknown" ;
VAL_ 2654552151 FD14_MeTRSC_e_TrlrCalInfo 2 "Undefined" 1 "Calibrated" 0 "Not Calibrated" ;
VAL_ 2654552151 FD14_MeTRSC_e_TrailerID 6 "Trailer_MAX" 5 "Trailer_Absent" 4 "Trailer_ID5" 3 "Trailer_ID4" 2 "Trailer_ID3" 1 "Trailer_ID2" 0 "Trailer_ID1" ;
VAL_ 2654552151 FD14_MeTRSC_e_CalFail 2 "More Turn Needed" 1 "Camera Blocked" 0 "No Failure" ;
VAL_ 2654552151 FD14_MeTRSC_e_TADCalibrationSubs 2 "Wait" 1 "TurnLeftOrRight" 0 "DriveStraight" ;
VAL_ 2654552151 FD14_MeTRSC_e_TurnAroundSubState 2 "Wait" 1 "TurnLeftOrRight" 0 "DriveStraight" ;
VAL_ 2654552151 FD14_MeTRSC_e_TADState 7 "Trackinglost" 6 "AngleDetection" 5 "Turnaround" 4 "ScanningForTrailer" 3 "Calibration" 2 "TrailerRecognition" 1 "TrailerDetection" 0 "Idle" ;
VAL_ 2654552165 FD14_IeTRSC_e_TRSCAbortReas 21 "SNA" 20 "Fail Not Present" 19 "Invalid PROXI/veh configmismatch" 18 "Veh speed > spped req by CVADAS" 17 "Trailer angle too steep" 16 "ECU Voltage too low/high" 15 "No/Invalid response from TRSKM" 14 "TRSC butt pressed on TRSKM/Radio" 13 "No user feedback for 600s" 12 "Driver steering override" 11 "trlr image Cameraview lost inFOV" 10 "Forward direction speed > 25mph" 9 "Driver Door Open" 8 "Engine Status signal = OFF" 7 "Rear Tailgate Open" 6 "Ignition not in RUN" 5 "No/invalid response from Radio" 4 "No/invalid response ORC" 3 "No/invalid response Trans Cont." 2 "No/invalid response EPSM" 1 "No/invalid response BSM" 0 "No/Invalid rspnsEngineController" ;
VAL_ 2654552165 FD14_MeTRSC_e_TRSCStat 6 "Fault" 5 "ActiveHoldOvr" 4 "Active" 3 "PreActive" 2 "Calibrating" 1 "Standby" 0 "Off" ;
VAL_ 2654552165 FD14_IeTRSC_e_TrlrAngGrapOverSts 2 "SNA" 1 "Active" 0 "Inactive" ;
VAL_ 2654552165 FD14_IeTRSC_e_TRSCUnavailReas 20 "SNA" 19 "Fail Not Present" 18 "Invalid PROXI/Veh Conf. Mismatch" 17 "ECU in Plant Mode" 16 "ECU Voltage too low/high" 15 "No/invalid response TRSKM" 14 "Trailer Calibration Failure" 13 "trailer angle too steep" 12 "Trailer not detected by system" 11 "Camera calibration is unknown" 10 "Vehicle not in 'P'" 9 "Driver door open" 8 "Engine status signal = OFF" 7 "Rear tailgate open" 6 "Ignition not in RUN" 5 "No/invalid response Radio" 4 "No/invalid response ORC" 3 "No/invalid response TC" 2 "No/invalid response EPSM" 1 "No/invalid response BSM" 0 "No/invalid rspnsEngineController" ;
VAL_ 2654552165 FD14_IeTRSC_e_CamBlockSts 3 "SNA" 2 "Low light" 1 "Camera clear" 0 "Camera blocked" ;
VAL_ 2654552165 FD14_IeTRSC_e_TrlrRecogInfo 3 "SNA" 2 "No trailer detected" 1 "Unknown Trailer" 0 "Known Trailer" ;
VAL_ 2654552165 FD14_IeTRSC_e_TRSKMSts 2 "SNA" 1 "Not Enabled" 0 "Enabled" ;
VAL_ 2654552165 FD14_IeTRSC_e_TRSKMCenBtnSts 3 "SNA" 2 "Struck" 1 "Not Pressed" 0 "Pressed" ;
VAL_ 2654552165 FD14_IeTRSC_e_TRSKMBtnSts 3 "SNA" 2 "Stuck" 1 "Not Pressed" 0 "Pressed" ;
VAL_ 2654552165 FD14_IeTRSC_e_TrailerID 5 "Trailer_Absent" 4 "Trailer_ID5" 3 "Trailer_ID4" 2 "Trailer_ID3" 1 "Trailer_ID2" 0 "Trailer_ID1" ;
VAL_ 2654552165 FD14_IeTRSC_e_GearShiftSts 7 "SNA" 6 "S" 5 "M" 4 "L" 3 "D" 2 "N" 1 "R" 0 "P" ;
VAL_ 2654552165 FD14_IeTRSC_e_TrlrPrsntSts 2 "SNA" 1 "Detected" 0 "Not Detected" ;
VAL_ 2654552165 FD14_IeTRSC_e_TrlrPrsntFailReas 2 "SNA" 1 "None" 0 "Camera Occlusion/Lowlight Status" ;
VAL_ 2654552165 FD14_IeTRSC_e_TrlrCalibSts 2 "SNA" 1 "Not Calibrated" 0 "Calibrated" ;
VAL_ 2654552165 FD14_IeTRSC_e_TrlrCalibManState 3 "SNA" 2 "None" 1 "Intersection turn left or right" 0 "Drive straight" ;
VAL_ 2654552165 FD14_IeTRSC_e_TrlrCalibFailReas 4 "SNA" 3 "None" 2 "Camera Occlusion/Lowlight Status" 1 "Require more straight driving" 0 "Need more turn radius/arc length" ;
SIG_VALTYPE_ 2654552193 FD14_obj_Pos_Longi : 1;
SIG_VALTYPE_ 2654552193 FD14_obj_Pos_Lat : 1;
SIG_VALTYPE_ 2654552336 FD14_stFPAInfoToVCLockedSlotRear : 1;
SIG_VALTYPE_ 2654552336 FD14_stFPAInfoToVCLockedSlotFrnt : 1;
SIG_VALTYPE_ 2654552336 FD14_stFPAInfoToVCLockedSlo_0000 : 1;
SIG_VALTYPE_ 2654552336 FD14_stFPAInfoToVCLockedSlo_0001 : 1;
SIG_VALTYPE_ 2654552184 FD14_LMD_m_Line_2_End_Range : 1;
SIG_VALTYPE_ 2654552184 FD14_LMD_m_Line_2_Start_Range : 1;
SIG_VALTYPE_ 2654552184 FD14_LMD_rad_Line_2_Heading : 1;
SIG_VALTYPE_ 2654552184 FD14_LMD_m_Line_2_Offset : 1;
SIG_VALTYPE_ 2654552184 FD14_LMD_pct_Line_2_Confidence : 1;
SIG_VALTYPE_ 2654552184 FD14_LMD_px_Line_2_Curvature : 1;
SIG_VALTYPE_ 2654552184 FD14_LMD_m_Line_1_End_Range : 1;
SIG_VALTYPE_ 2654552184 FD14_LMD_m_Line_1_Start_Range : 1;
SIG_VALTYPE_ 2654552184 FD14_LMD_rad_Line_1_Heading : 1;
SIG_VALTYPE_ 2654552184 FD14_LMD_m_Line_1_Offset : 1;
SIG_VALTYPE_ 2654552184 FD14_LMD_px_Line_1_Curvature : 1;
SIG_VALTYPE_ 2654552184 FD14_LMD_pct_Line_1_Confidence : 1;
SIG_VALTYPE_ 2654552321 FD14_LMD_pct_Line_3_Confidence : 1;
SIG_VALTYPE_ 2654552321 FD14_LMD_px_Line_3_Curvature : 1;
SIG_VALTYPE_ 2654552321 FD14_LMD_m_Line_4_End_Range : 1;
SIG_VALTYPE_ 2654552321 FD14_LMD_m_Line_4_Start_Range : 1;
SIG_VALTYPE_ 2654552321 FD14_LMD_rad_Line_4_Heading : 1;
SIG_VALTYPE_ 2654552321 FD14_LMD_m_Line_4_Offset : 1;
SIG_VALTYPE_ 2654552321 FD14_LMD_pct_Line_4_Confidence : 1;
SIG_VALTYPE_ 2654552321 FD14_LMD_px_Line_4_Curvature : 1;
SIG_VALTYPE_ 2654552321 FD14_LMD_m_Line_3_End_Range : 1;
SIG_VALTYPE_ 2654552321 FD14_LMD_m_Line_3_Start_Range : 1;
SIG_VALTYPE_ 2654552321 FD14_LMD_rad_Line_3_Heading : 1;
SIG_VALTYPE_ 2654552321 FD14_LMD_m_Line_3_Offset : 1;
SIG_VALTYPE_ 2654552322 FD14_LMD_m_Segment_5_Y1 : 1;
SIG_VALTYPE_ 2654552322 FD14_LMD_m_Segment_4_Y1 : 1;
SIG_VALTYPE_ 2654552322 FD14_LMD_m_Segment_3_Y1 : 1;
SIG_VALTYPE_ 2654552322 FD14_LMD_m_Segment_2_Y1 : 1;
SIG_VALTYPE_ 2654552322 FD14_LMD_m_Segment_1_Y1 : 1;
SIG_VALTYPE_ 2654552322 FD14_LMD_m_Segment_8_X1 : 1;
SIG_VALTYPE_ 2654552322 FD14_LMD_m_Segment_6_X1 : 1;
SIG_VALTYPE_ 2654552322 FD14_LMD_m_Segment_7_X1 : 1;
SIG_VALTYPE_ 2654552322 FD14_LMD_m_Segment_5_X1 : 1;
SIG_VALTYPE_ 2654552322 FD14_LMD_m_Segment_4_X1 : 1;
SIG_VALTYPE_ 2654552322 FD14_LMD_m_Segment_3_X1 : 1;
SIG_VALTYPE_ 2654552322 FD14_LMD_m_Segment_2_X1 : 1;
SIG_VALTYPE_ 2654552322 FD14_LMD_m_Segment_1_X1 : 1;
SIG_VALTYPE_ 2654552323 FD14_LMD_m_Segment_8_Y1 : 1;
SIG_VALTYPE_ 2654552323 FD14_LMD_m_Segment_7_Y1 : 1;
SIG_VALTYPE_ 2654552323 FD14_LMD_m_Segment_6_Y1 : 1;
SIG_VALTYPE_ 2654552324 FD14_LMD_m_Segment_8_Y2 : 1;
SIG_VALTYPE_ 2654552324 FD14_LMD_m_Segment_7_Y2 : 1;
SIG_VALTYPE_ 2654552324 FD14_LMD_m_Segment_6_Y2 : 1;
SIG_VALTYPE_ 2654552324 FD14_LMD_m_Segment_5_Y2 : 1;
SIG_VALTYPE_ 2654552324 FD14_LMD_m_Segment_4_Y2 : 1;
SIG_VALTYPE_ 2654552324 FD14_LMD_m_Segment_3_Y2 : 1;
SIG_VALTYPE_ 2654552324 FD14_LMD_m_Segment_2_Y2 : 1;
SIG_VALTYPE_ 2654552324 FD14_LMD_m_Segment_1_Y2 : 1;
SIG_VALTYPE_ 2654552324 FD14_LMD_m_Segment_8_X2 : 1;
SIG_VALTYPE_ 2654552324 FD14_LMD_m_Segment_7_X2 : 1;
SIG_VALTYPE_ 2654552324 FD14_LMD_m_Segment_6_X2 : 1;
SIG_VALTYPE_ 2654552324 FD14_LMD_m_Segment_5_X2 : 1;
SIG_VALTYPE_ 2654552324 FD14_LMD_m_Segment_4_X2 : 1;
SIG_VALTYPE_ 2654552324 FD14_LMD_m_Segment_3_X2 : 1;
SIG_VALTYPE_ 2654552324 FD14_LMD_m_Segment_2_X2 : 1;
SIG_VALTYPE_ 2654552324 FD14_LMD_m_Segment_1_X2 : 1;
SIG_VALTYPE_ 2654552325 FD14_LMD_pct_Segment_7_Confidenc : 1;
SIG_VALTYPE_ 2654552325 FD14_LMD_pct_Segment_8_Confidenc : 1;
SIG_VALTYPE_ 2654552325 FD14_LMD_pct_Segment_5_Confidenc : 1;
SIG_VALTYPE_ 2654552325 FD14_LMD_pct_Segment_6_Confidenc : 1;
SIG_VALTYPE_ 2654552325 FD14_LMD_pct_Segment_3_Confidenc : 1;
SIG_VALTYPE_ 2654552325 FD14_LMD_pct_Segment_4_Confidenc : 1;
SIG_VALTYPE_ 2654552325 FD14_LMD_pct_Segment_1_Confidenc : 1;
SIG_VALTYPE_ 2654552325 FD14_LMD_pct_Segment_2_Confidenc : 1;
SIG_VALTYPE_ 2654552179 FD14_MOT_ObjectDimensions_1_1 : 1;
SIG_VALTYPE_ 2654552179 FD14_MOT_ObjectDimensions_0_1 : 1;
SIG_VALTYPE_ 2654552179 FD14_MOT_ObjVelY_1 : 1;
SIG_VALTYPE_ 2654552179 FD14_MOT_ObjVelX_1 : 1;
SIG_VALTYPE_ 2654552179 FD14_MOT_ClosestPntDist_1_1 : 1;
SIG_VALTYPE_ 2654552179 FD14_MOT_ClosestPntDist_0_1 : 1;
SIG_VALTYPE_ 2654552179 FD14_MOT_ObjectDimensions_1_0 : 1;
SIG_VALTYPE_ 2654552179 FD14_MOT_ObjectDimensions_0_0 : 1;
SIG_VALTYPE_ 2654552179 FD14_MOT_ObjVelY_0 : 1;
SIG_VALTYPE_ 2654552179 FD14_MOT_ObjVelX_0 : 1;
SIG_VALTYPE_ 2654552179 FD14_MOT_ClosestPntDist_1_0 : 1;
SIG_VALTYPE_ 2654552179 FD14_MOT_ClosestPntDist_0_0 : 1;
SIG_VALTYPE_ 2654552180 FD14_MOT_ObjectDimensions_1_3 : 1;
SIG_VALTYPE_ 2654552180 FD14_MOT_ObjectDimensions_0_3 : 1;
SIG_VALTYPE_ 2654552180 FD14_MOT_ObjVelY_3 : 1;
SIG_VALTYPE_ 2654552180 FD14_MOT_ObjVelX_3 : 1;
SIG_VALTYPE_ 2654552180 FD14_MOT_ClosestPntDist_1_3 : 1;
SIG_VALTYPE_ 2654552180 FD14_MOT_ClosestPntDist_0_3 : 1;
SIG_VALTYPE_ 2654552180 FD14_MOT_ObjectDimensions_1_2 : 1;
SIG_VALTYPE_ 2654552180 FD14_MOT_ObjectDimensions_0_2 : 1;
SIG_VALTYPE_ 2654552180 FD14_MOT_ObjVelY_2 : 1;
SIG_VALTYPE_ 2654552180 FD14_MOT_ObjVelX_2 : 1;
SIG_VALTYPE_ 2654552180 FD14_MOT_ClosestPntDist_1_2 : 1;
SIG_VALTYPE_ 2654552180 FD14_MOT_ClosestPntDist_0_2 : 1;
SIG_VALTYPE_ 2654552181 FD14_MOT_ObjectDimensions_1_5 : 1;
SIG_VALTYPE_ 2654552181 FD14_MOT_ObjectDimensions_0_5 : 1;
SIG_VALTYPE_ 2654552181 FD14_MOT_ObjVelY_5 : 1;
SIG_VALTYPE_ 2654552181 FD14_MOT_ObjVelX_5 : 1;
SIG_VALTYPE_ 2654552181 FD14_MOT_ClosestPntDist_1_5 : 1;
SIG_VALTYPE_ 2654552181 FD14_MOT_ClosestPntDist_0_5 : 1;
SIG_VALTYPE_ 2654552181 FD14_MOT_ObjectDimensions_1_4 : 1;
SIG_VALTYPE_ 2654552181 FD14_MOT_ObjectDimensions_0_4 : 1;
SIG_VALTYPE_ 2654552181 FD14_MOT_ObjVelY_4 : 1;
SIG_VALTYPE_ 2654552181 FD14_MOT_ObjVelX_4 : 1;
SIG_VALTYPE_ 2654552181 FD14_MOT_ClosestPntDist_1_4 : 1;
SIG_VALTYPE_ 2654552181 FD14_MOT_ClosestPntDist_0_4 : 1;
SIG_VALTYPE_ 2654552182 FD14_MOT_ObjectDimensions_1_7 : 1;
SIG_VALTYPE_ 2654552182 FD14_MOT_ObjectDimensions_0_7 : 1;
SIG_VALTYPE_ 2654552182 FD14_MOT_ObjVelY_7 : 1;
SIG_VALTYPE_ 2654552182 FD14_MOT_ObjVelX_7 : 1;
SIG_VALTYPE_ 2654552182 FD14_MOT_ClosestPntDist_1_7 : 1;
SIG_VALTYPE_ 2654552182 FD14_MOT_ClosestPntDist_0_7 : 1;
SIG_VALTYPE_ 2654552182 FD14_MOT_ObjectDimensions_1_6 : 1;
SIG_VALTYPE_ 2654552182 FD14_MOT_ObjectDimensions_0_6 : 1;
SIG_VALTYPE_ 2654552182 FD14_MOT_ObjVelY_6 : 1;
SIG_VALTYPE_ 2654552182 FD14_MOT_ObjVelX_6 : 1;
SIG_VALTYPE_ 2654552182 FD14_MOT_ClosestPntDist_1_6 : 1;
SIG_VALTYPE_ 2654552182 FD14_MOT_ClosestPntDist_0_6 : 1;
SIG_VALTYPE_ 2654552183 FD14_MOT_ObjectDimensions_1_9 : 1;
SIG_VALTYPE_ 2654552183 FD14_MOT_ObjectDimensions_0_9 : 1;
SIG_VALTYPE_ 2654552183 FD14_MOT_ObjVelY_9 : 1;
SIG_VALTYPE_ 2654552183 FD14_MOT_ObjVelX_9 : 1;
SIG_VALTYPE_ 2654552183 FD14_MOT_ClosestPntDist_1_9 : 1;
SIG_VALTYPE_ 2654552183 FD14_MOT_ClosestPntDist_0_9 : 1;
SIG_VALTYPE_ 2654552183 FD14_MOT_ObjectDimensions_1_8 : 1;
SIG_VALTYPE_ 2654552183 FD14_MOT_ObjectDimensions_0_8 : 1;
SIG_VALTYPE_ 2654552183 FD14_MOT_ObjVelY_8 : 1;
SIG_VALTYPE_ 2654552183 FD14_MOT_ObjVelX_8 : 1;
SIG_VALTYPE_ 2654552183 FD14_MOT_ClosestPntDist_1_8 : 1;
SIG_VALTYPE_ 2654552183 FD14_MOT_ClosestPntDist_0_8 : 1;
SIG_VALTYPE_ 2654552326 FD14_stPLDParkingSlot4RearRightX : 1;
SIG_VALTYPE_ 2654552326 FD14_stPLDParkingSlot4RearRightY : 1;
SIG_VALTYPE_ 2654552326 FD14_stPLDParkingSlot4FrontLeftY : 1;
SIG_VALTYPE_ 2654552326 FD14_stPLDParkingSlot4FrontLeftX : 1;
SIG_VALTYPE_ 2654552326 FD14_stPLDParkingSlot1RearRightY : 1;
SIG_VALTYPE_ 2654552326 FD14_stPLDParkingSlot1RearRightX : 1;
SIG_VALTYPE_ 2654552326 FD14_stPLDParkingSlot1FrontLeftY : 1;
SIG_VALTYPE_ 2654552326 FD14_stPLDParkingSlot1FrontLeftX : 1;
SIG_VALTYPE_ 2654552327 FD14_stPLDLockedSlotDataRearRigh : 1;
SIG_VALTYPE_ 2654552327 FD14_stPLDLockedSlotDataRea_0000 : 1;
SIG_VALTYPE_ 2654552327 FD14_stPLDLockedSlotDataFrontLef : 1;
SIG_VALTYPE_ 2654552327 FD14_stPLDLockedSlotDataFro_0000 : 1;
SIG_VALTYPE_ 2654552185 FD14_MeTHA_deg_RoadWhlAng : 1;
SIG_VALTYPE_ 2654552192 FD14_MeTHA_deg_CplrAng : 1;
SIG_VALTYPE_ 2654552151 FD14_ReservedTRSCSig2 : 1;
SIG_VALTYPE_ 2654552151 FD14_ReservedTRSCSig1 : 1;
SIG_VALTYPE_ 2654552151 FD14_IeTRSC_pct_TrlrRecogConf : 1;
SIG_VALTYPE_ 2654552151 FD14_IeTRSC_pct_TrlrTrackConf : 1;
SIG_VALTYPE_ 2654552151 FD14_MeTRSC_m_HitchLength : 1;
SIG_VALTYPE_ 2654552151 FD14_IeTRSC_m_TrlrWhlBaseEff : 1;
SIG_VALTYPE_ 2654552151 FD14_IeTRSC_pct_TrlrDetConf : 1;
SIG_VALTYPE_ 2654552151 FD14_MeTRSC_deg_JackKnifeAngle : 1;
SIG_VALTYPE_ 2654552151 FD14_MeTRSC_m_TrailerBeamLen : 1;
SIG_VALTYPE_ 2654552151 FD14_MeTRSC_deg_JackknifeThrAngl : 1;
SIG_VALTYPE_ 2654552151 FD14_MeTRSC_deg_TADAngleRate : 1;
SIG_VALTYPE_ 2654552151 FD14_MeTRSC_deg_MaxAllowedTADAng : 1;
SIG_VALTYPE_ 2654552151 FD14_MeTRSC_deg_TADAngle : 1;
SIG_VALTYPE_ 2654552165 FD14_IeTRSC_kph_VehSpeedVSOSig : 1;
SIG_VALTYPE_ 2654552165 FD14_IeTRSC_M_TRSCStrTrq : 1;
SIG_VALTYPE_ 2654552165 FD14_IeTRSC_deg_JackknifeThrAngl : 1;
SIG_VALTYPE_ 2654552165 FD14_IeTRSC_deg_TADAngle : 1;
SIG_VALTYPE_ 2654552165 FD14_IeTRSC_deg_TrlrAngKnob : 1;
SIG_VALTYPE_ 2654552165 FD14_IeTRSC_deg_FrntWhlAng : 1;
